VERSION ""

NS_ :

BS_:

BU_: AHLM ASBS CBC DIAGNOST DPDM DTCM ECM EHPS ESC ESL ESM ETM GPF HCP IC IRCM OCM ORC PTS RF_HUB SCCM SGW TBM TCM TPM

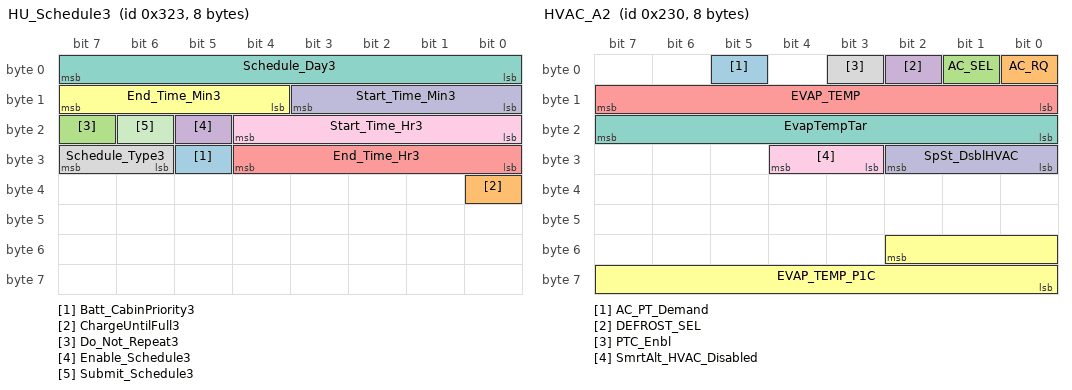
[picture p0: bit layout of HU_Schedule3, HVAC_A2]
BO_ 803 HU_Schedule3: 8 CBC
 SG_ Batt_CabinPriority3 : 29|1@1+ (1,0) [0|0] ""  HCP,SGW
 SG_ ChargeUntilFull3 : 32|1@1+ (1,0) [0|0] ""  HCP,SGW
 SG_ Do_Not_Repeat3 : 23|1@1+ (1,0) [0|0] ""  HCP,SGW
 SG_ Enable_Schedule3 : 21|1@1+ (1,0) [0|0] ""  HCP,SGW
 SG_ End_Time_Hr3 : 24|5@1+ (1,0) [0|23] "Hours"  HCP,SGW
 SG_ End_Time_Min3 : 12|4@1+ (5,0) [0|55] "min"  HCP,SGW
 SG_ Schedule_Day3 : 0|8@1+ (1,0) [0|0] ""  HCP,SGW
 SG_ Schedule_Type3 : 30|2@1+ (1,0) [0|0] ""  HCP,SGW
 SG_ Start_Time_Hr3 : 16|5@1+ (1,0) [0|23] "Hours"  HCP,SGW
 SG_ Start_Time_Min3 : 8|4@1+ (5,0) [0|55] "min"  HCP,SGW
 SG_ Submit_Schedule3 : 22|1@1+ (1,0) [0|0] ""  HCP,SGW

BO_ 560 HVAC_A2: 8 CBC
 SG_ AC_PT_Demand : 5|1@1+ (1,0) [0|0] ""  ECM,SGW
 SG_ AC_RQ : 0|1@1+ (1,0) [0|0] ""  ECM,HCP,SGW
 SG_ AC_SEL : 1|1@1+ (1,0) [0|0] ""  ECM,SGW
 SG_ DEFROST_SEL : 2|1@1+ (1,0) [0|0] ""  ECM,HCP,SGW
 SG_ EVAP_TEMP : 8|8@1+ (0.5,-20) [-20|107] "°C"  ECM,SGW
 SG_ EVAP_TEMP_P1C : 50|11@0+ (0.1,-40) [-40|85] "°C"  HCP,SGW
 SG_ EvapTempTar : 16|8@1+ (0.5,-20) [-20|107] "°C"  ECM,HCP,SGW
 SG_ PTC_Enbl : 3|1@1+ (1,0) [0|0] ""  ECM,SGW
 SG_ SmrtAlt_HVAC_Disabled : 27|2@1+ (1,0) [0|0] ""  SGW
 SG_ SpSt_DsblHVAC : 24|3@1+ (1,0) [0|0] ""  ECM,SGW

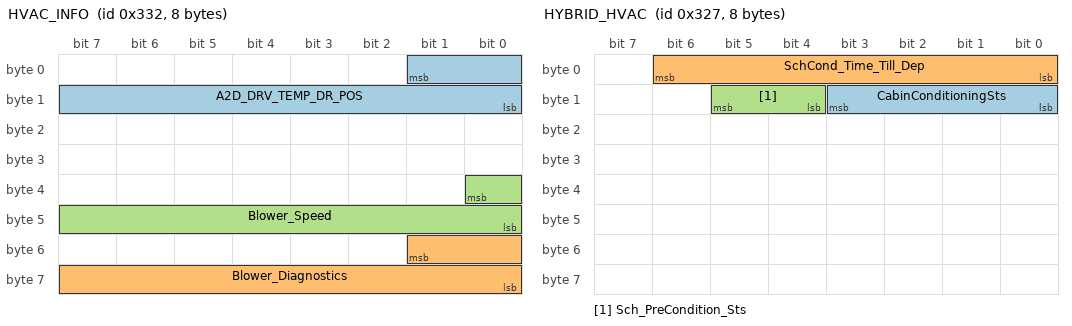
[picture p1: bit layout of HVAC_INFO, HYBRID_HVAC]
BO_ 818 HVAC_INFO: 8 CBC
 SG_ A2D_DRV_TEMP_DR_POS : 1|10@0+ (0.00489237,0) [0|5] "V"  ECM,SGW
 SG_ Blower_Diagnostics : 49|10@0+ (0.1,0) [0|100] "%"  ECM,HCP,SGW
 SG_ Blower_Speed : 32|9@0+ (1,0) [0|350] "Hz"  ECM,SGW

BO_ 807 HYBRID_HVAC: 8 HCP
 SG_ CabinConditioningSts : 8|4@1+ (1,0) [0|0] ""  CBC,ETM,SGW,TBM
 SG_ SchCond_Time_Till_Dep : 0|7@1+ (1,0) [0|126] ""  CBC,SGW,TBM
 SG_ Sch_PreCondition_Sts : 12|2@1+ (1,0) [0|0] ""  CBC,SGW,TBM

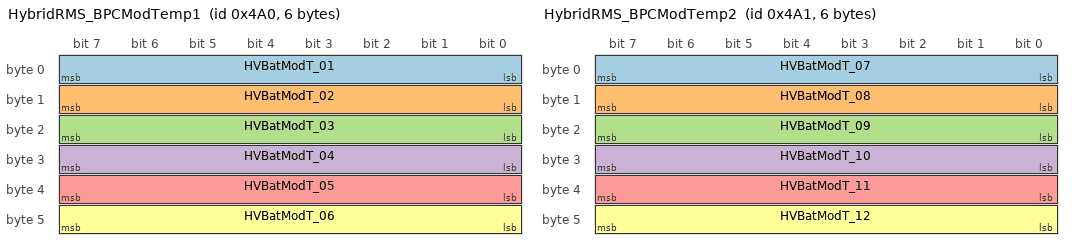
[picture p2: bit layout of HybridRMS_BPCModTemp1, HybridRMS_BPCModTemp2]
BO_ 1184 HybridRMS_BPCModTemp1: 6 HCP
 SG_ HVBatModT_01 : 0|8@1+ (1,-40) [-40|214] "oC"  SGW,TBM
 SG_ HVBatModT_02 : 8|8@1+ (1,-40) [-40|214] "oC"  SGW,TBM
 SG_ HVBatModT_03 : 16|8@1+ (1,-40) [-40|214] "oC"  SGW,TBM
 SG_ HVBatModT_04 : 24|8@1+ (1,-40) [-40|214] "oC"  SGW,TBM
 SG_ HVBatModT_05 : 32|8@1+ (1,-40) [-40|214] "oC"  SGW,TBM
 SG_ HVBatModT_06 : 40|8@1+ (1,-40) [-40|214] "oC"  SGW,TBM

BO_ 1185 HybridRMS_BPCModTemp2: 6 HCP
 SG_ HVBatModT_07 : 0|8@1+ (1,-40) [-40|214] "oC"  SGW,TBM
 SG_ HVBatModT_08 : 8|8@1+ (1,-40) [-40|214] "oC"  SGW,TBM
 SG_ HVBatModT_09 : 16|8@1+ (1,-40) [-40|214] "oC"  SGW,TBM
 SG_ HVBatModT_10 : 24|8@1+ (1,-40) [-40|214] "oC"  SGW,TBM
 SG_ HVBatModT_11 : 32|8@1+ (1,-40) [-40|214] "oC"  SGW,TBM
 SG_ HVBatModT_12 : 40|8@1+ (1,-40) [-40|214] "oC"  SGW,TBM

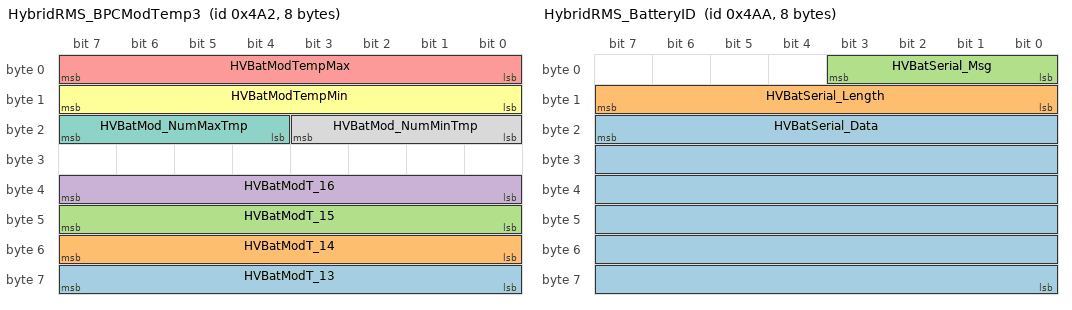
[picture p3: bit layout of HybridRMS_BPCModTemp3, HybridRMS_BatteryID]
BO_ 1186 HybridRMS_BPCModTemp3: 8 HCP
 SG_ HVBatModT_13 : 56|8@1+ (1,-40) [-40|214] "oC"  SGW,TBM
 SG_ HVBatModT_14 : 48|8@1+ (1,-40) [-40|214] "oC"  SGW,TBM
 SG_ HVBatModT_15 : 40|8@1+ (1,-40) [-40|214] "oC"  SGW,TBM
 SG_ HVBatModT_16 : 32|8@1+ (1,-40) [-40|214] "oC"  SGW,TBM
 SG_ HVBatModTempMax : 0|8@1+ (1,-40) [-40|214] "oC"  SGW,TBM
 SG_ HVBatModTempMin : 8|8@1+ (1,-40) [-40|214] "oC"  SGW,TBM
 SG_ HVBatMod_NumMaxTmp : 20|4@1+ (1,0) [0|15] ""  SGW,TBM
 SG_ HVBatMod_NumMinTmp : 16|4@1+ (1,0) [0|15] ""  SGW,TBM

BO_ 1194 HybridRMS_BatteryID: 8 HCP
 SG_ HVBatSerial_Data : 23|48@0+ (1,0) [0|281474976710000] "ASCII"  SGW,TBM
 SG_ HVBatSerial_Length : 8|8@1+ (1,0) [0|254] ""  SGW,TBM
 SG_ HVBatSerial_Msg : 0|4@1+ (1,0) [0|0] ""  SGW,TBM

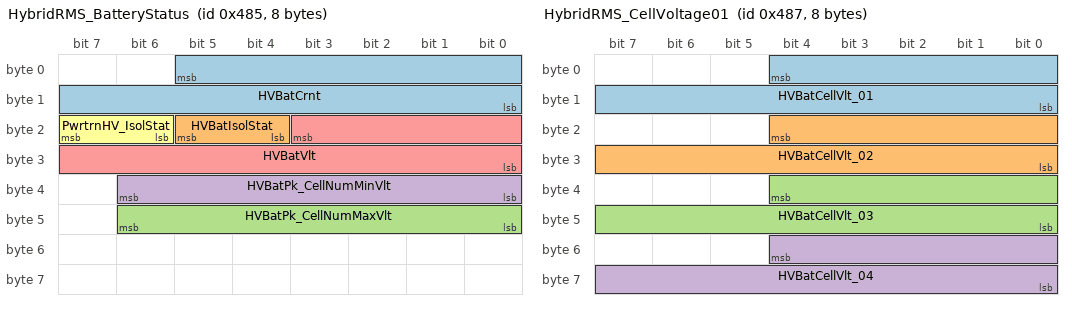
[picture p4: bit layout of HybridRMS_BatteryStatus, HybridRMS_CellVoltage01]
BO_ 1157 HybridRMS_BatteryStatus: 8 HCP
 SG_ HVBatCrnt : 5|14@0+ (0.1,-512.1) [-512|512] "Amp"  SGW,TBM
 SG_ HVBatIsolStat : 20|2@1+ (1,0) [0|0] ""  SGW,TBM
 SG_ HVBatPk_CellNumMaxVlt : 40|7@1+ (1,0) [1|96] "Volts"  SGW,TBM
 SG_ HVBatPk_CellNumMinVlt : 32|7@1+ (1,0) [1|96] "Volts"  SGW,TBM
 SG_ HVBatVlt : 19|12@0+ (0.1,180) [180|511] "Volts"  SGW,TBM
 SG_ PwrtrnHV_IsolStat : 22|2@1+ (1,0) [0|0] ""  SGW,TBM

BO_ 1159 HybridRMS_CellVoltage01: 8 HCP
 SG_ HVBatCellVlt_01 : 4|13@0+ (0.001,0) [0|5] "V"  SGW,TBM
 SG_ HVBatCellVlt_02 : 20|13@0+ (0.001,0) [0|5] "V"  SGW,TBM
 SG_ HVBatCellVlt_03 : 36|13@0+ (0.001,0) [0|5] "V"  SGW,TBM
 SG_ HVBatCellVlt_04 : 52|13@0+ (0.001,0) [0|5] "V"  SGW,TBM

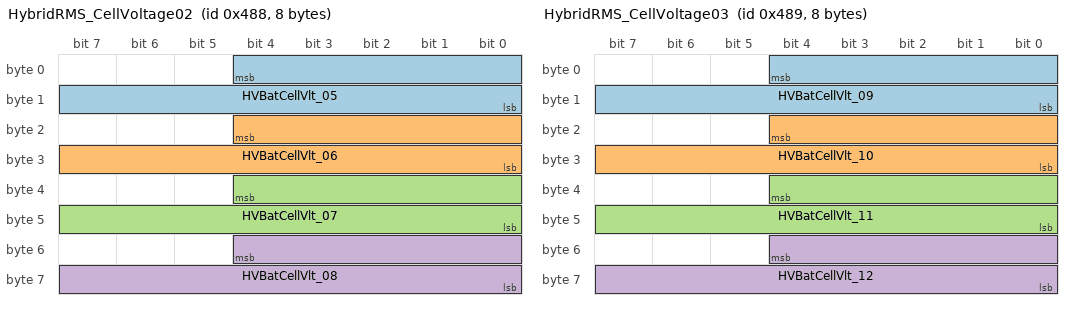
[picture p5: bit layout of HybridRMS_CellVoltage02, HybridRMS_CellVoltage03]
BO_ 1160 HybridRMS_CellVoltage02: 8 HCP
 SG_ HVBatCellVlt_05 : 4|13@0+ (0.001,0) [0|5] "V"  SGW,TBM
 SG_ HVBatCellVlt_06 : 20|13@0+ (0.001,0) [0|5] "V"  SGW,TBM
 SG_ HVBatCellVlt_07 : 36|13@0+ (0.001,0) [0|5] "V"  SGW,TBM
 SG_ HVBatCellVlt_08 : 52|13@0+ (0.001,0) [0|5] "V"  SGW,TBM

BO_ 1161 HybridRMS_CellVoltage03: 8 HCP
 SG_ HVBatCellVlt_09 : 4|13@0+ (0.001,0) [0|5] "V"  SGW,TBM
 SG_ HVBatCellVlt_10 : 20|13@0+ (0.001,0) [0|5] "V"  SGW,TBM
 SG_ HVBatCellVlt_11 : 36|13@0+ (0.001,0) [0|5] "V"  SGW,TBM
 SG_ HVBatCellVlt_12 : 52|13@0+ (0.001,0) [0|5] "V"  SGW,TBM

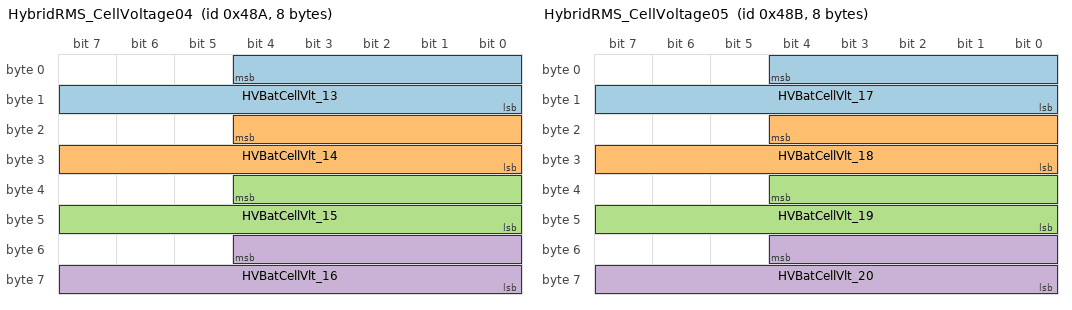
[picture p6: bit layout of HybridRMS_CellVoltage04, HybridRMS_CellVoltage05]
BO_ 1162 HybridRMS_CellVoltage04: 8 HCP
 SG_ HVBatCellVlt_13 : 4|13@0+ (0.001,0) [0|5] "V"  SGW,TBM
 SG_ HVBatCellVlt_14 : 20|13@0+ (0.001,0) [0|5] "V"  SGW,TBM
 SG_ HVBatCellVlt_15 : 36|13@0+ (0.001,0) [0|5] "V"  SGW,TBM
 SG_ HVBatCellVlt_16 : 52|13@0+ (0.001,0) [0|5] "V"  SGW,TBM

BO_ 1163 HybridRMS_CellVoltage05: 8 HCP
 SG_ HVBatCellVlt_17 : 4|13@0+ (0.001,0) [0|5] "V"  SGW,TBM
 SG_ HVBatCellVlt_18 : 20|13@0+ (0.001,0) [0|5] "V"  SGW,TBM
 SG_ HVBatCellVlt_19 : 36|13@0+ (0.001,0) [0|5] "V"  SGW,TBM
 SG_ HVBatCellVlt_20 : 52|13@0+ (0.001,0) [0|5] "V"  SGW,TBM

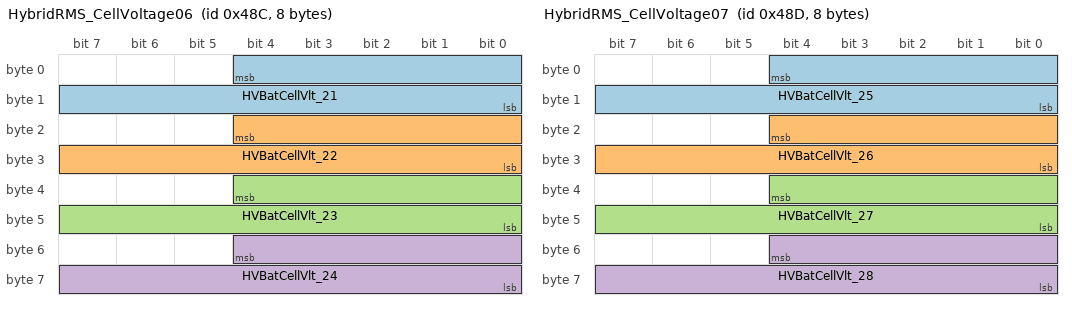
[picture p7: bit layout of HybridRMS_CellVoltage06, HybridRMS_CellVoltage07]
BO_ 1164 HybridRMS_CellVoltage06: 8 HCP
 SG_ HVBatCellVlt_21 : 4|13@0+ (0.001,0) [0|5] "V"  SGW,TBM
 SG_ HVBatCellVlt_22 : 20|13@0+ (0.001,0) [0|5] "V"  SGW,TBM
 SG_ HVBatCellVlt_23 : 36|13@0+ (0.001,0) [0|5] "V"  SGW,TBM
 SG_ HVBatCellVlt_24 : 52|13@0+ (0.001,0) [0|5] "V"  SGW,TBM

BO_ 1165 HybridRMS_CellVoltage07: 8 HCP
 SG_ HVBatCellVlt_25 : 4|13@0+ (0.001,0) [0|5] "V"  SGW,TBM
 SG_ HVBatCellVlt_26 : 20|13@0+ (0.001,0) [0|5] "V"  SGW,TBM
 SG_ HVBatCellVlt_27 : 36|13@0+ (0.001,0) [0|5] "V"  SGW,TBM
 SG_ HVBatCellVlt_28 : 52|13@0+ (0.001,0) [0|5] "V"  SGW,TBM

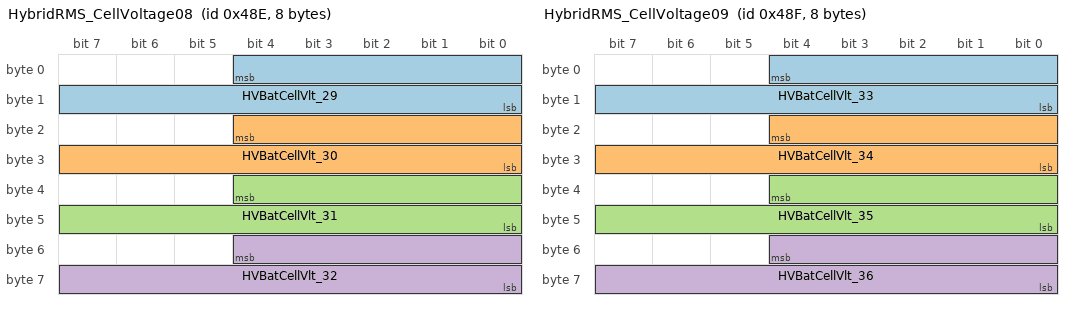
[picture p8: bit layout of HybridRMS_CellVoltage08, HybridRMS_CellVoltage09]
BO_ 1166 HybridRMS_CellVoltage08: 8 HCP
 SG_ HVBatCellVlt_29 : 4|13@0+ (0.001,0) [0|5] "V"  SGW,TBM
 SG_ HVBatCellVlt_30 : 20|13@0+ (0.001,0) [0|5] "V"  SGW,TBM
 SG_ HVBatCellVlt_31 : 36|13@0+ (0.001,0) [0|5] "V"  SGW,TBM
 SG_ HVBatCellVlt_32 : 52|13@0+ (0.001,0) [0|5] "V"  SGW,TBM

BO_ 1167 HybridRMS_CellVoltage09: 8 HCP
 SG_ HVBatCellVlt_33 : 4|13@0+ (0.001,0) [0|5] "V"  SGW,TBM
 SG_ HVBatCellVlt_34 : 20|13@0+ (0.001,0) [0|5] "V"  SGW,TBM
 SG_ HVBatCellVlt_35 : 36|13@0+ (0.001,0) [0|5] "V"  SGW,TBM
 SG_ HVBatCellVlt_36 : 52|13@0+ (0.001,0) [0|5] "V"  SGW,TBM

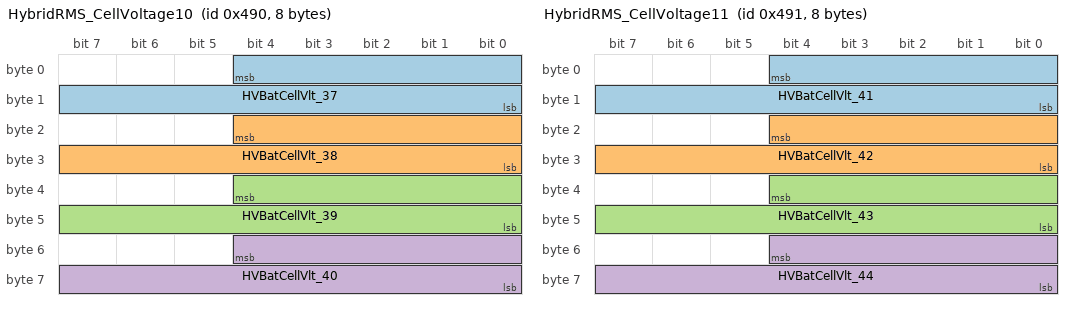
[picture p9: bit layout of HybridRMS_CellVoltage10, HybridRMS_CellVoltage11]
BO_ 1168 HybridRMS_CellVoltage10: 8 HCP
 SG_ HVBatCellVlt_37 : 4|13@0+ (0.001,0) [0|5] "V"  SGW,TBM
 SG_ HVBatCellVlt_38 : 20|13@0+ (0.001,0) [0|5] "V"  SGW,TBM
 SG_ HVBatCellVlt_39 : 36|13@0+ (0.001,0) [0|5] "V"  SGW,TBM
 SG_ HVBatCellVlt_40 : 52|13@0+ (0.001,0) [0|5] "V"  SGW,TBM

BO_ 1169 HybridRMS_CellVoltage11: 8 HCP
 SG_ HVBatCellVlt_41 : 4|13@0+ (0.001,0) [0|5] "V"  SGW,TBM
 SG_ HVBatCellVlt_42 : 20|13@0+ (0.001,0) [0|5] "V"  SGW,TBM
 SG_ HVBatCellVlt_43 : 36|13@0+ (0.001,0) [0|5] "V"  SGW,TBM
 SG_ HVBatCellVlt_44 : 52|13@0+ (0.001,0) [0|5] "V"  SGW,TBM

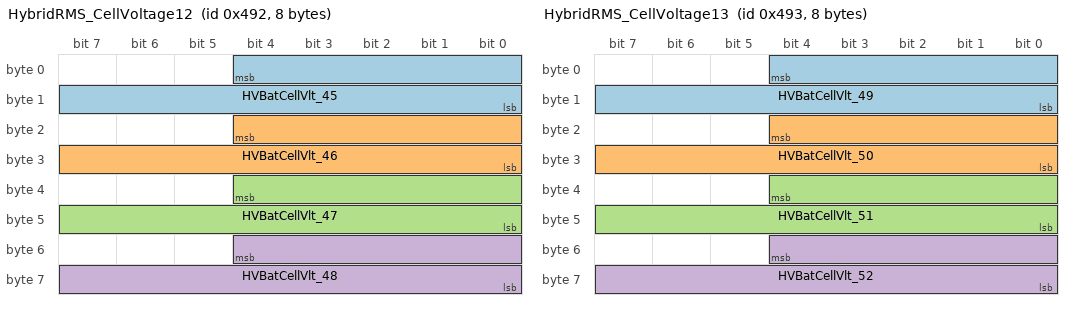
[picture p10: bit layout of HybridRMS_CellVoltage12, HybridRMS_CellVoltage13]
BO_ 1170 HybridRMS_CellVoltage12: 8 HCP
 SG_ HVBatCellVlt_45 : 4|13@0+ (0.001,0) [0|5] "V"  SGW,TBM
 SG_ HVBatCellVlt_46 : 20|13@0+ (0.001,0) [0|5] "V"  SGW,TBM
 SG_ HVBatCellVlt_47 : 36|13@0+ (0.001,0) [0|5] "V"  SGW,TBM
 SG_ HVBatCellVlt_48 : 52|13@0+ (0.001,0) [0|5] "V"  SGW,TBM

BO_ 1171 HybridRMS_CellVoltage13: 8 HCP
 SG_ HVBatCellVlt_49 : 4|13@0+ (0.001,0) [0|5] "V"  SGW,TBM
 SG_ HVBatCellVlt_50 : 20|13@0+ (0.001,0) [0|5] "V"  SGW,TBM
 SG_ HVBatCellVlt_51 : 36|13@0+ (0.001,0) [0|5] "V"  SGW,TBM
 SG_ HVBatCellVlt_52 : 52|13@0+ (0.001,0) [0|5] "V"  SGW,TBM

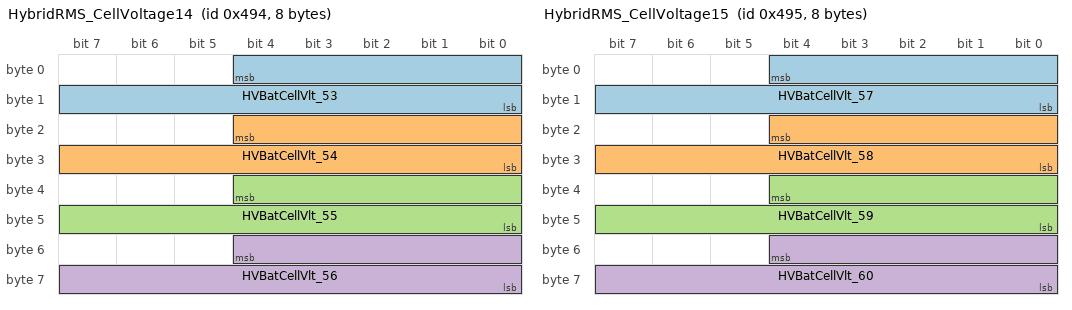
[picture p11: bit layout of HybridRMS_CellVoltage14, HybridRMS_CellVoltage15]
BO_ 1172 HybridRMS_CellVoltage14: 8 HCP
 SG_ HVBatCellVlt_53 : 4|13@0+ (0.001,0) [0|5] "V"  SGW,TBM
 SG_ HVBatCellVlt_54 : 20|13@0+ (0.001,0) [0|5] "V"  SGW,TBM
 SG_ HVBatCellVlt_55 : 36|13@0+ (0.001,0) [0|5] "V"  SGW,TBM
 SG_ HVBatCellVlt_56 : 52|13@0+ (0.001,0) [0|5] "V"  SGW,TBM

BO_ 1173 HybridRMS_CellVoltage15: 8 HCP
 SG_ HVBatCellVlt_57 : 4|13@0+ (0.001,0) [0|5] "V"  SGW,TBM
 SG_ HVBatCellVlt_58 : 20|13@0+ (0.001,0) [0|5] "V"  SGW,TBM
 SG_ HVBatCellVlt_59 : 36|13@0+ (0.001,0) [0|5] "V"  SGW,TBM
 SG_ HVBatCellVlt_60 : 52|13@0+ (0.001,0) [0|5] "V"  SGW,TBM

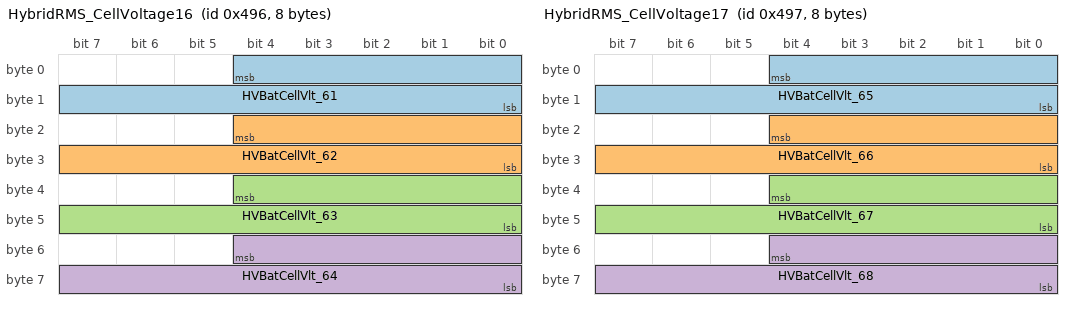
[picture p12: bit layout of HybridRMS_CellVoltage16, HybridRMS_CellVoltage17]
BO_ 1174 HybridRMS_CellVoltage16: 8 HCP
 SG_ HVBatCellVlt_61 : 4|13@0+ (0.001,0) [0|5] "V"  SGW,TBM
 SG_ HVBatCellVlt_62 : 20|13@0+ (0.001,0) [0|5] "V"  SGW,TBM
 SG_ HVBatCellVlt_63 : 36|13@0+ (0.001,0) [0|5] "V"  SGW,TBM
 SG_ HVBatCellVlt_64 : 52|13@0+ (0.001,0) [0|5] "V"  SGW,TBM

BO_ 1175 HybridRMS_CellVoltage17: 8 HCP
 SG_ HVBatCellVlt_65 : 4|13@0+ (0.001,0) [0|5] "V"  SGW,TBM
 SG_ HVBatCellVlt_66 : 20|13@0+ (0.001,0) [0|5] "V"  SGW,TBM
 SG_ HVBatCellVlt_67 : 36|13@0+ (0.001,0) [0|5] "V"  SGW,TBM
 SG_ HVBatCellVlt_68 : 52|13@0+ (0.001,0) [0|5] "V"  SGW,TBM

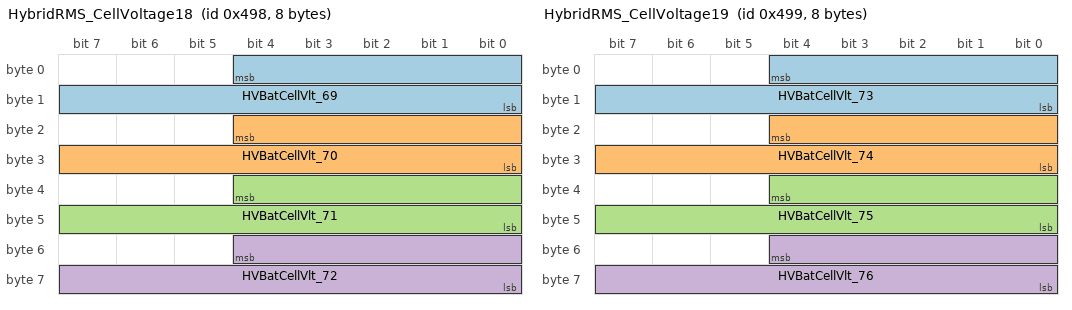
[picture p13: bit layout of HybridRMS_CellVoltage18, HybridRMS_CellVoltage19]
BO_ 1176 HybridRMS_CellVoltage18: 8 HCP
 SG_ HVBatCellVlt_69 : 4|13@0+ (0.001,0) [0|5] "V"  SGW,TBM
 SG_ HVBatCellVlt_70 : 20|13@0+ (0.001,0) [0|5] "V"  SGW,TBM
 SG_ HVBatCellVlt_71 : 36|13@0+ (0.001,0) [0|5] "V"  SGW,TBM
 SG_ HVBatCellVlt_72 : 52|13@0+ (0.001,0) [0|5] "V"  SGW,TBM

BO_ 1177 HybridRMS_CellVoltage19: 8 HCP
 SG_ HVBatCellVlt_73 : 4|13@0+ (0.001,0) [0|5] "V"  SGW,TBM
 SG_ HVBatCellVlt_74 : 20|13@0+ (0.001,0) [0|5] "V"  SGW,TBM
 SG_ HVBatCellVlt_75 : 36|13@0+ (0.001,0) [0|5] "V"  SGW,TBM
 SG_ HVBatCellVlt_76 : 52|13@0+ (0.001,0) [0|5] "V"  SGW,TBM

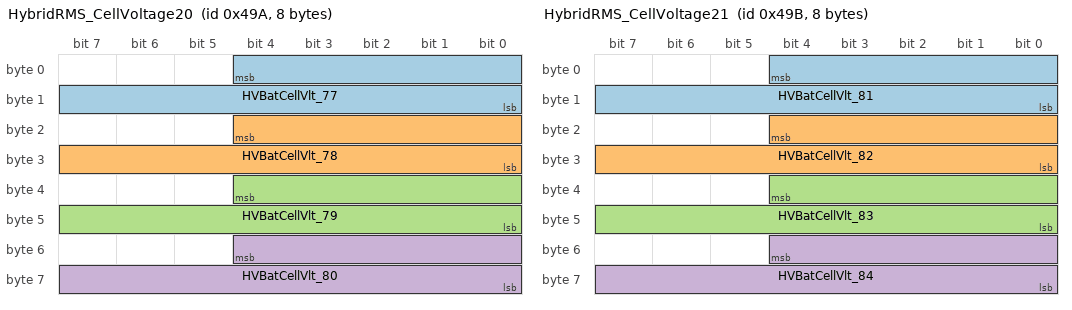
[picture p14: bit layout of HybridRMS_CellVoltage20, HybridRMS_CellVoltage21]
BO_ 1178 HybridRMS_CellVoltage20: 8 HCP
 SG_ HVBatCellVlt_77 : 4|13@0+ (0.001,0) [0|5] "V"  SGW,TBM
 SG_ HVBatCellVlt_78 : 20|13@0+ (0.001,0) [0|5] "V"  SGW,TBM
 SG_ HVBatCellVlt_79 : 36|13@0+ (0.001,0) [0|5] "V"  SGW,TBM
 SG_ HVBatCellVlt_80 : 52|13@0+ (0.001,0) [0|5] "V"  SGW,TBM

BO_ 1179 HybridRMS_CellVoltage21: 8 HCP
 SG_ HVBatCellVlt_81 : 4|13@0+ (0.001,0) [0|5] "V"  SGW,TBM
 SG_ HVBatCellVlt_82 : 20|13@0+ (0.001,0) [0|5] "V"  SGW,TBM
 SG_ HVBatCellVlt_83 : 36|13@0+ (0.001,0) [0|5] "V"  SGW,TBM
 SG_ HVBatCellVlt_84 : 52|13@0+ (0.001,0) [0|5] "V"  SGW,TBM

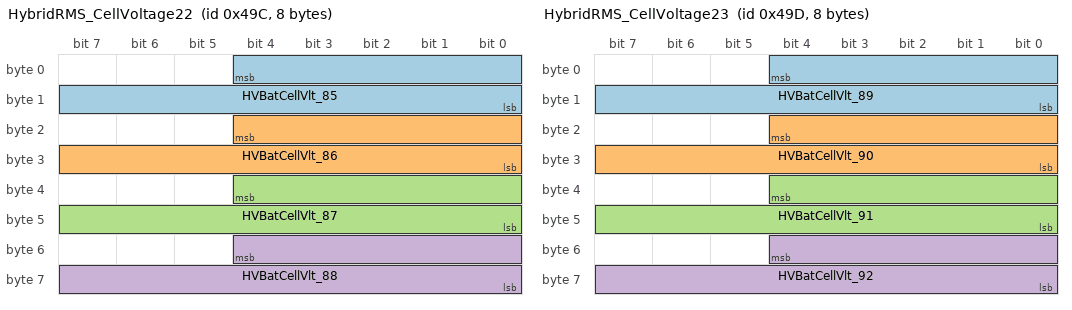
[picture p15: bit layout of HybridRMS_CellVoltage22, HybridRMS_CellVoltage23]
BO_ 1180 HybridRMS_CellVoltage22: 8 HCP
 SG_ HVBatCellVlt_85 : 4|13@0+ (0.001,0) [0|5] "V"  SGW,TBM
 SG_ HVBatCellVlt_86 : 20|13@0+ (0.001,0) [0|5] "V"  SGW,TBM
 SG_ HVBatCellVlt_87 : 36|13@0+ (0.001,0) [0|5] "V"  SGW,TBM
 SG_ HVBatCellVlt_88 : 52|13@0+ (0.001,0) [0|5] "V"  SGW,TBM

BO_ 1181 HybridRMS_CellVoltage23: 8 HCP
 SG_ HVBatCellVlt_89 : 4|13@0+ (0.001,0) [0|5] "V"  SGW,TBM
 SG_ HVBatCellVlt_90 : 20|13@0+ (0.001,0) [0|5] "V"  SGW,TBM
 SG_ HVBatCellVlt_91 : 36|13@0+ (0.001,0) [0|5] "V"  SGW,TBM
 SG_ HVBatCellVlt_92 : 52|13@0+ (0.001,0) [0|5] "V"  SGW,TBM

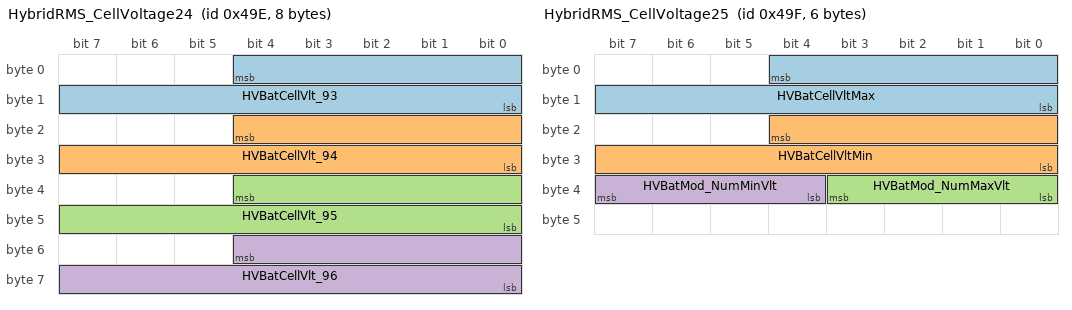
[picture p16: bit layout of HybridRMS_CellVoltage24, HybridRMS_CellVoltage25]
BO_ 1182 HybridRMS_CellVoltage24: 8 HCP
 SG_ HVBatCellVlt_93 : 4|13@0+ (0.001,0) [0|5] "V"  SGW,TBM
 SG_ HVBatCellVlt_94 : 20|13@0+ (0.001,0) [0|5] "V"  SGW,TBM
 SG_ HVBatCellVlt_95 : 36|13@0+ (0.001,0) [0|5] "V"  SGW,TBM
 SG_ HVBatCellVlt_96 : 52|13@0+ (0.001,0) [0|5] "V"  SGW,TBM

BO_ 1183 HybridRMS_CellVoltage25: 6 HCP
 SG_ HVBatCellVltMax : 4|13@0+ (0.001,0) [0|5] "Volts"  SGW,TBM
 SG_ HVBatCellVltMin : 20|13@0+ (0.001,0) [0|5] "Volts"  SGW,TBM
 SG_ HVBatMod_NumMaxVlt : 32|4@1+ (1,0) [0|15] ""  SGW,TBM
 SG_ HVBatMod_NumMinVlt : 36|4@1+ (1,0) [0|15] ""  SGW,TBM

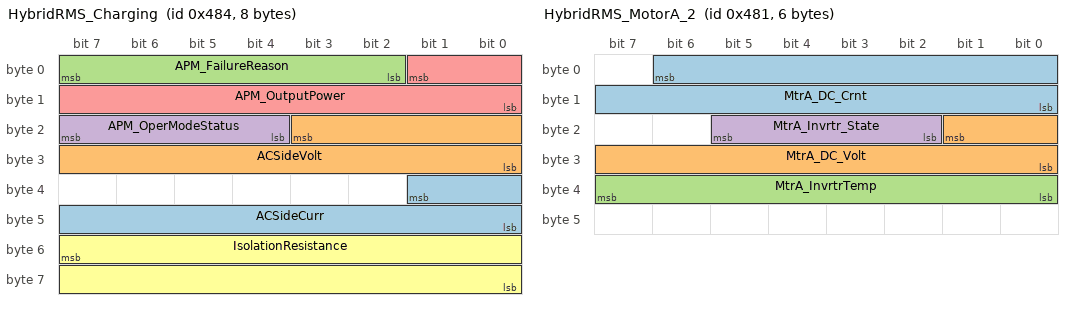
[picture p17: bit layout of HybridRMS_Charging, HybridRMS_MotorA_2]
BO_ 1156 HybridRMS_Charging: 8 HCP
 SG_ ACSideCurr : 33|10@0+ (0.1,-50) [-50|50] "Amp"  SGW,TBM
 SG_ ACSideVolt : 19|12@0+ (0.1,0) [0|300] "Volts"  SGW,TBM
 SG_ APM_FailureReason : 2|6@1+ (1,0) [0|0] ""  SGW,TBM
 SG_ APM_OperModeStatus : 20|4@1+ (1,0) [0|0] ""  SGW,TBM
 SG_ APM_OutputPower : 1|10@0+ (3,0) [0|3066] "W"  SGW,TBM
 SG_ IsolationResistance : 55|16@0+ (1,0) [0|65534] "kOhm"  SGW,TBM

BO_ 1152 HybridRMS_MotorA_1: 6 HCP
 SG_ MtrA_RPM : 7|16@0+ (1,-32768) [-32768|32767] "RPM"  SGW,TBM
 SG_ MtrA_Temp : 32|8@1+ (1,-40) [-40|215] "oC"  SGW,TBM
 SG_ MtrA_TorqAchieved : 20|13@0+ (0.125,-512) [-512|511.875] "Nm"  SGW,TBM

BO_ 1153 HybridRMS_MotorA_2: 6 HCP
 SG_ MtrA_DC_Crnt : 6|15@0+ (0.1,-1638.4) [-1638.4|1638.3] "A"  SGW,TBM
 SG_ MtrA_DC_Volt : 17|10@0+ (1,0) [0|1023] "V"  SGW,TBM
 SG_ MtrA_InvrtrTemp : 32|8@1+ (1,-40) [-40|215] "oC"  SGW,TBM
 SG_ MtrA_Invrtr_State : 18|4@1+ (1,0) [0|0] ""  SGW,TBM

BO_ 1154 HybridRMS_MotorB_1: 6 HCP
 SG_ MtrB_RPM : 7|16@0+ (1,-32768) [-32768|32767] "RPM"  SGW,TBM
 SG_ MtrB_Temp : 32|8@1+ (1,-40) [-40|215] "oC"  SGW,TBM
 SG_ MtrB_TorqAchieved : 20|13@0+ (0.125,-512) [-512|511.875] "Nm"  SGW,TBM

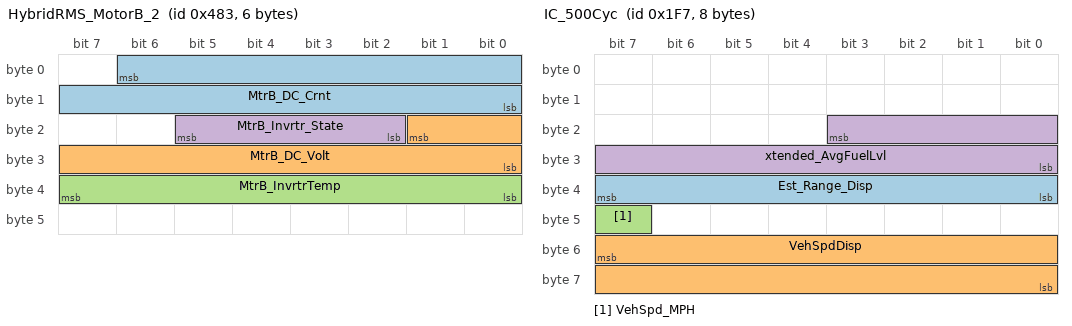
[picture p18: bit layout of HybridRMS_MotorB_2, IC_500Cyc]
BO_ 1155 HybridRMS_MotorB_2: 6 HCP
 SG_ MtrB_DC_Crnt : 6|15@0+ (0.1,-1638.4) [-1638.4|1638.3] "A"  SGW,TBM
 SG_ MtrB_DC_Volt : 17|10@0+ (1,0) [0|1023] "V"  SGW,TBM
 SG_ MtrB_InvrtrTemp : 32|8@1+ (1,-40) [-40|215] "oC"  SGW,TBM
 SG_ MtrB_Invrtr_State : 18|4@1+ (1,0) [0|0] ""  SGW,TBM

BO_ 1158 HybridRMS_Warnings: 8 HCP
 SG_ APMPerfWrn : 2|1@1+ (1,0) [0|0] ""  SGW,TBM
 SG_ APMTempWrn : 3|1@1+ (1,0) [0|0] ""  SGW,TBM
 SG_ BPCMCellBalWrn : 5|1@1+ (1,0) [0|0] ""  SGW,TBM
 SG_ BPCMCellOverWrn : 6|1@1+ (1,0) [0|0] ""  SGW,TBM
 SG_ BPCMCellUnderWrn : 7|1@1+ (1,0) [0|0] ""  SGW,TBM
 SG_ BPCMHighSOCWrn : 8|1@1+ (1,0) [0|0] ""  SGW,TBM
 SG_ BPCMInsulWrn : 9|1@1+ (1,0) [0|0] ""  SGW,TBM
 SG_ BPCMMaxTempWrn : 1|1@1+ (1,0) [0|0] ""  SGW,TBM
 SG_ BPCMOverChrgWrn : 10|1@1+ (1,0) [0|0] ""  SGW,TBM
 SG_ BPCMOverVoltWrn : 11|1@1+ (1,0) [0|0] ""  SGW,TBM
 SG_ BPCMSOCJumpWrn : 12|1@1+ (1,0) [0|0] ""  SGW,TBM
 SG_ BPCMSOCLowWrn : 13|1@1+ (1,0) [0|0] ""  SGW,TBM
 SG_ BPCMTempDiffWrn : 0|1@1+ (1,0) [0|0] ""  SGW,TBM
 SG_ BPCMUnderVoltWrn : 14|1@1+ (1,0) [0|0] ""  SGW,TBM
 SG_ BPCMUnmatchedWrn : 15|1@1+ (1,0) [0|0] ""  SGW,TBM
 SG_ HVILWrn : 4|1@1+ (1,0) [0|0] ""  SGW,TBM
 SG_ HighestWarnLevel : 16|2@1+ (1,0) [0|0] ""  SGW,TBM
 SG_ MtrA_InvOverTempWrn : 19|1@1+ (1,0) [0|0] ""  SGW,TBM
 SG_ MtrA_OverTempWrn : 18|1@1+ (1,0) [0|0] ""  SGW,TBM
 SG_ MtrB_InvOverTempWrn : 21|1@1+ (1,0) [0|0] ""  SGW,TBM
 SG_ MtrB_OverTempWrn : 20|1@1+ (1,0) [0|0] ""  SGW,TBM

BO_ 503 IC_500Cyc: 8 IC
 SG_ Est_Range_Disp : 32|8@1+ (1,0) [0|254] ""  CBC,ETM,SGW,TBM
 SG_ VehSpdDisp : 55|16@0+ (1,0) [0|65534] ""  CBC,SGW
 SG_ VehSpd_MPH : 47|1@1+ (1,0) [0|0] ""  CBC,SGW
 SG_ xtended_AvgFuelLvl : 19|12@0+ (0.5,0) [0|2047] "liters"  CBC,ECM,SGW

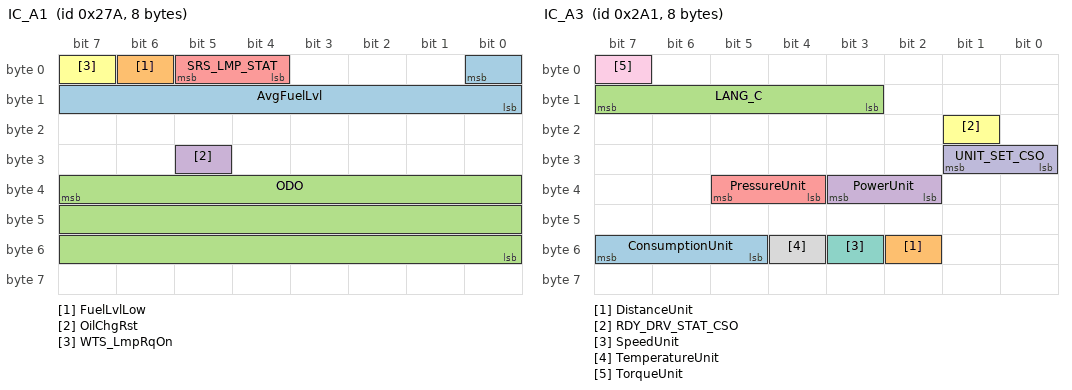
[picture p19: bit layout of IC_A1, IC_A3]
BO_ 634 IC_A1: 8 IC
 SG_ AvgFuelLvl : 0|9@0+ (0.5,0) [0|255] "liters"  CBC,ECM,ETM,SGW,TBM
 SG_ FuelLvlLow : 6|1@1+ (1,0) [0|0] ""  CBC,ECM,ETM,SGW,TBM
 SG_ ODO : 39|24@0+ (0.1,0) [0|1677721.4] "km"  AHLM,ASBS,CBC,DPDM,DTCM,ECM,EHPS,ESC,ESL,ESM,ETM,GPF,HCP,IRCM,OCM,ORC,PTS,RF_HUB,SCCM,SGW,TBM,TCM,TPM
 SG_ OilChgRst : 29|1@1+ (1,0) [0|0] ""  ECM,SGW
 SG_ SRS_LMP_STAT : 4|2@1+ (1,0) [0|0] ""  ETM,ORC,SGW,TBM
 SG_ WTS_LmpRqOn : 7|1@1+ (1,0) [0|0] ""  ECM,SGW

BO_ 673 IC_A3: 8 IC
 SG_ ConsumptionUnit : 53|3@1+ (1,0) [0|0] ""  CBC,SGW
 SG_ DistanceUnit : 50|1@1+ (1,0) [0|0] ""  CBC,ECM,SGW
 SG_ LANG_C : 11|5@1+ (1,0) [0|0] ""  CBC,SGW,TBM
 SG_ PowerUnit : 34|2@1+ (1,0) [0|0] ""  CBC,SGW
 SG_ PressureUnit : 36|2@1+ (1,0) [0|0] ""  CBC,SGW
 SG_ RDY_DRV_STAT_CSO : 17|1@1+ (1,0) [0|0] ""  CBC,SGW
 SG_ SpeedUnit : 51|1@1+ (1,0) [0|0] ""  ASBS,CBC,ECM,IRCM,SGW
 SG_ TemperatureUnit : 52|1@1+ (1,0) [0|0] ""  CBC,SGW
 SG_ TorqueUnit : 7|1@1+ (1,0) [0|0] ""  CBC,SGW
 SG_ UNIT_SET_CSO : 24|2@1+ (1,0) [0|0] ""  CBC,SGW

BO_ 635 IC_A5: 8 IC
 SG_ Gas_Range : 1|10@0+ (1,0) [0|1022] "km"  CBC,ETM,SGW,TBM
 SG_ Total_Range : 18|11@0+ (1,0) [0|2046] "km"  CBC,ETM,SGW,TBM

BO_ 754 IC_A6: 8 IC
 SG_ Avg_Fuel_Econ : 33|10@0+ (0.05,0) [0|50] "kmpl"  CBC,ETM,SGW,TBM
 SG_ Inst_Fuel_Econ : 49|10@0+ (0.05,0) [0|50] "kmpl"  CBC,SGW

BO_ 938 IC_TripData_1: 8 IC
 SG_ A_EV_Kilometers : 47|24@0+ (0.1,0) [0|16093.3] "km"  ETM,SGW,TBM
 SG_ A_EV_Miles : 23|24@0+ (0.1,0) [0|9999.9] "Mile"  ETM,SGW,TBM
 SG_ A_MPG : 1|10@0+ (0.1,0) [0|99.9] "MPG"  ETM,SGW,TBM

BO_ 939 IC_TripData_2: 8 IC
 SG_ A_Hybrid_Kilometers : 47|24@0+ (0.1,0) [0|16093.3] "km"  ETM,SGW,TBM
 SG_ A_Hybrid_Miles : 23|24@0+ (0.1,0) [0|9999.9] "Mile"  ETM,SGW,TBM
 SG_ A_KMpL : 1|10@0+ (0.1,0) [0|99.9] "kmpl"  ETM,SGW,TBM

BO_ 940 IC_TripData_3: 8 IC
 SG_ A_Total_Dist_Kilometers : 47|24@0+ (0.1,0) [0|16093.3] "km"  ETM,SGW,TBM
 SG_ A_Total_Dist_Miles : 23|24@0+ (0.1,0) [0|9999.9] "Mile"  ETM,SGW,TBM

BO_ 941 IC_TripData_4: 8 IC
 SG_ B_EV_Kilometers : 47|24@0+ (0.1,0) [0|16093.3] "km"  ETM,SGW,TBM
 SG_ B_EV_Miles : 23|24@0+ (0.1,0) [0|9999.9] "Mile"  ETM,SGW,TBM
 SG_ B_MPG : 1|10@0+ (0.1,0) [0|99.9] "MPG"  ETM,SGW,TBM

BO_ 942 IC_TripData_5: 8 IC
 SG_ B_Hybrid_Kilometers : 47|24@0+ (0.1,0) [0|16093.3] "km"  ETM,SGW,TBM
 SG_ B_Hybrid_Miles : 23|24@0+ (0.1,0) [0|9999.9] "Mile"  ETM,SGW,TBM
 SG_ B_KMpL : 1|10@0+ (0.1,0) [0|99.9] "kmpl"  ETM,SGW,TBM

CM_ SG_ 803 Batt_CabinPriority3 "Bit to prioritize battery charging or cabin conditioning under schedule 3";
CM_ SG_ 803 ChargeUntilFull3 "Charge until battery is fully charged with schedule 3";
CM_ SG_ 803 Do_Not_Repeat3 "Do not repeat the set Schedule";
CM_ SG_ 803 Enable_Schedule3 "Schedule 3 checkbox enabled";
CM_ SG_ 803 End_Time_Hr3 "End Time of schedule 3 (hours in 24 hrs. format)";
CM_ SG_ 803 End_Time_Min3 "End Time of schedule 3 (Minutes)";
CM_ SG_ 803 Schedule_Day3 "Schedule#3 Day for charging or cabin conditioning";
CM_ SG_ 803 Schedule_Type3 "Type of charging and climate schedule";
CM_ SG_ 803 Start_Time_Hr3 "Start Time of schedule 3 (hours in 24 hrs. format)";
CM_ SG_ 803 Start_Time_Min3 "Start Time of schedule 3 (minutes)";
CM_ SG_ 803 Submit_Schedule3 "Schedule 3 submitted";
CM_ SG_ 560 AC_PT_Demand "Maximum A/C demand to powertrain";
CM_ SG_ 560 AC_RQ "A/C clutch request; [1] = A/C Clutch requested; 0 = A/C Clutch not requested";
CM_ SG_ 560 AC_SEL "Customer has selected A/C; [1] = A/C selected; 0 = A/C not selected";
CM_ SG_ 560 DEFROST_SEL "Defrost select switch";
CM_ SG_ 560 EVAP_TEMP "AC evaporator temperature";
CM_ SG_ 560 EVAP_TEMP_P1C "AC evap temp point one C";
CM_ SG_ 560 EvapTempTar "Evaporator temperature target";
CM_ SG_ 560 PTC_Enbl "PTC heater enable; [1] = enable";
CM_ SG_ 560 SmrtAlt_HVAC_Disabled "Disable the smart alternator";
CM_ SG_ 560 SpSt_DsblHVAC "Stop start disable from HVAC";
CM_ SG_ 818 A2D_DRV_TEMP_DR_POS "Transmit raw A/D driver temp door position to ECM to make OBD model more robust";
CM_ SG_ 818 Blower_Diagnostics "Duty cycle Feedback received from the Blower";
CM_ SG_ 818 Blower_Speed "Frequency Feedback received from the Blower";
CM_ SG_ 807 CabinConditioningSts "Cabin condition status";
CM_ SG_ 807 SchCond_Time_Till_Dep "Schedule Cabin Conditonting - Time till Departure for HVAC";
CM_ SG_ 807 Sch_PreCondition_Sts "HCP Status for Scheduled Pre Conditioning Request";
CM_ SG_ 1184 HVBatModT_01 "High voltage battery module temperature";
CM_ SG_ 1184 HVBatModT_02 "High voltage battery module temperature";
CM_ SG_ 1184 HVBatModT_03 "High voltage battery module temperature";
CM_ SG_ 1184 HVBatModT_04 "High voltage battery module temperature";
CM_ SG_ 1184 HVBatModT_05 "High voltage battery module temperature";
CM_ SG_ 1184 HVBatModT_06 "High voltage battery module temperature";
CM_ SG_ 1185 HVBatModT_07 "High voltage battery module temperature";
CM_ SG_ 1185 HVBatModT_08 "High voltage battery module temperature";
CM_ SG_ 1185 HVBatModT_09 "High voltage battery module temperature";
CM_ SG_ 1185 HVBatModT_10 "High voltage battery module temperature";
CM_ SG_ 1185 HVBatModT_11 "High voltage battery module temperature";
CM_ SG_ 1185 HVBatModT_12 "High voltage battery module temperature";
CM_ SG_ 1186 HVBatModT_13 "High voltage battery module temperature";
CM_ SG_ 1186 HVBatModT_14 "High voltage battery module temperature";
CM_ SG_ 1186 HVBatModT_15 "High voltage battery module temperature";
CM_ SG_ 1186 HVBatModT_16 "High voltage battery module temperature";
CM_ SG_ 1186 HVBatModTempMax "HV Battery pack Maximum temperature";
CM_ SG_ 1186 HVBatModTempMin "HV Battery pack Minimum temperature";
CM_ SG_ 1186 HVBatMod_NumMaxTmp "Module number - maximum temperature";
CM_ SG_ 1186 HVBatMod_NumMinTmp "Module number - minimum temperature";
CM_ SG_ 1194 HVBatSerial_Data "6 character segment of HV Battery pack serial number (using 8-bit ASCII encoding)";
CM_ SG_ 1194 HVBatSerial_Length "Length of the High Voltage Battery pack's serial number (number of ASCII characters)";
CM_ SG_ 1194 HVBatSerial_Msg "Identifies which 6 character segment of the HV Battery pack serial number is currently in HVBatSerial_Data";
CM_ SG_ 1157 HVBatCrnt "High voltage Battery pack current...";
CM_ SG_ 1157 HVBatIsolStat "High voltage battery pack Isolation state";
CM_ SG_ 1157 HVBatPk_CellNumMaxVlt "Cell ID of high voltage battery pack cell with the highest voltage.";
CM_ SG_ 1157 HVBatPk_CellNumMinVlt "Cell ID of high voltage battery pack cell with the lowest voltage.";
CM_ SG_ 1157 HVBatVlt "High voltage battery pack voltage";
CM_ SG_ 1157 PwrtrnHV_IsolStat "Powertrain High voltage Isolation state";
CM_ SG_ 1159 HVBatCellVlt_01 "High voltage battery cell voltage for Cell 01";
CM_ SG_ 1159 HVBatCellVlt_02 "High voltage battery cell voltage for Cell 02";
CM_ SG_ 1159 HVBatCellVlt_03 "High voltage battery cell voltage for Cell 03";
CM_ SG_ 1159 HVBatCellVlt_04 "High voltage battery cell voltage for Cell 04";
CM_ SG_ 1160 HVBatCellVlt_05 "High voltage battery cell voltage for Cell 05";
CM_ SG_ 1160 HVBatCellVlt_06 "High voltage battery cell voltage for Cell 06";
CM_ SG_ 1160 HVBatCellVlt_07 "High voltage battery cell voltage for Cell 07";
CM_ SG_ 1160 HVBatCellVlt_08 "High voltage battery cell voltage for Cell 08";
CM_ SG_ 1161 HVBatCellVlt_09 "High voltage battery cell voltage for Cell 09";
CM_ SG_ 1161 HVBatCellVlt_10 "High voltage battery cell voltage for Cell 10";
CM_ SG_ 1161 HVBatCellVlt_11 "High voltage battery cell voltage for Cell 11";
CM_ SG_ 1161 HVBatCellVlt_12 "High voltage battery cell voltage for Cell 12";
CM_ SG_ 1162 HVBatCellVlt_13 "High voltage battery cell voltage for Cell 13";
CM_ SG_ 1162 HVBatCellVlt_14 "High voltage battery cell voltage for Cell 14";
CM_ SG_ 1162 HVBatCellVlt_15 "High voltage battery cell voltage for Cell 15";
CM_ SG_ 1162 HVBatCellVlt_16 "High voltage battery cell voltage for Cell 16";
CM_ SG_ 1163 HVBatCellVlt_17 "High voltage battery cell voltage for Cell 17";
CM_ SG_ 1163 HVBatCellVlt_18 "High voltage battery cell voltage for Cell 18";
CM_ SG_ 1163 HVBatCellVlt_19 "High voltage battery cell voltage for Cell 19";
CM_ SG_ 1163 HVBatCellVlt_20 "High voltage battery cell voltage for Cell 20";
CM_ SG_ 1164 HVBatCellVlt_21 "High voltage battery cell voltage for Cell 21";
CM_ SG_ 1164 HVBatCellVlt_22 "High voltage battery cell voltage for Cell 22";
CM_ SG_ 1164 HVBatCellVlt_23 "High voltage battery cell voltage for Cell 23";
CM_ SG_ 1164 HVBatCellVlt_24 "High voltage battery cell voltage for Cell 24";
CM_ SG_ 1165 HVBatCellVlt_25 "High voltage battery cell voltage for Cell 25";
CM_ SG_ 1165 HVBatCellVlt_26 "High voltage battery cell voltage for Cell 26";
CM_ SG_ 1165 HVBatCellVlt_27 "High voltage battery cell voltage for Cell 27";
CM_ SG_ 1165 HVBatCellVlt_28 "High voltage battery cell voltage for Cell 28";
CM_ SG_ 1166 HVBatCellVlt_29 "High voltage battery cell voltage for Cell 29";
CM_ SG_ 1166 HVBatCellVlt_30 "High voltage battery cell voltage for Cell 30";
CM_ SG_ 1166 HVBatCellVlt_31 "High voltage battery cell voltage for Cell 31";
CM_ SG_ 1166 HVBatCellVlt_32 "High voltage battery cell voltage for Cell 32";
CM_ SG_ 1167 HVBatCellVlt_33 "High voltage battery cell voltage for Cell 33";
CM_ SG_ 1167 HVBatCellVlt_34 "High voltage battery cell voltage for Cell 34";
CM_ SG_ 1167 HVBatCellVlt_35 "High voltage battery cell voltage for Cell 35";
CM_ SG_ 1167 HVBatCellVlt_36 "High voltage battery cell voltage for Cell 36";
CM_ SG_ 1168 HVBatCellVlt_37 "High voltage battery cell voltage for Cell 37";
CM_ SG_ 1168 HVBatCellVlt_38 "High voltage battery cell voltage for Cell 38";
CM_ SG_ 1168 HVBatCellVlt_39 "High voltage battery cell voltage for Cell 39";
CM_ SG_ 1168 HVBatCellVlt_40 "High voltage battery cell voltage for Cell 40";
CM_ SG_ 1169 HVBatCellVlt_41 "High voltage battery cell voltage for Cell 41";
CM_ SG_ 1169 HVBatCellVlt_42 "High voltage battery cell voltage for Cell 42";
CM_ SG_ 1169 HVBatCellVlt_43 "High voltage battery cell voltage for Cell 43";
CM_ SG_ 1169 HVBatCellVlt_44 "High voltage battery cell voltage for Cell 44";
CM_ SG_ 1170 HVBatCellVlt_45 "High voltage battery cell voltage for Cell 45";
CM_ SG_ 1170 HVBatCellVlt_46 "High voltage battery cell voltage for Cell 46";
CM_ SG_ 1170 HVBatCellVlt_47 "High voltage battery cell voltage for Cell 47";
CM_ SG_ 1170 HVBatCellVlt_48 "High voltage battery cell voltage for Cell 48";
CM_ SG_ 1171 HVBatCellVlt_49 "High voltage battery cell voltage for Cell 49";
CM_ SG_ 1171 HVBatCellVlt_50 "High voltage battery cell voltage for Cell 50";
CM_ SG_ 1171 HVBatCellVlt_51 "High voltage battery cell voltage for Cell 51";
CM_ SG_ 1171 HVBatCellVlt_52 "High voltage battery cell voltage for Cell 52";
CM_ SG_ 1172 HVBatCellVlt_53 "High voltage battery cell voltage for Cell 53";
CM_ SG_ 1172 HVBatCellVlt_54 "High voltage battery cell voltage for Cell 54";
CM_ SG_ 1172 HVBatCellVlt_55 "High voltage battery cell voltage for Cell 55";
CM_ SG_ 1172 HVBatCellVlt_56 "High voltage battery cell voltage for Cell 56";
CM_ SG_ 1173 HVBatCellVlt_57 "High voltage battery cell voltage for Cell 57";
CM_ SG_ 1173 HVBatCellVlt_58 "High voltage battery cell voltage for Cell 58";
CM_ SG_ 1173 HVBatCellVlt_59 "High voltage battery cell voltage for Cell 59";
CM_ SG_ 1173 HVBatCellVlt_60 "High voltage battery cell voltage for Cell 60";
CM_ SG_ 1174 HVBatCellVlt_61 "High voltage battery cell voltage for Cell 61";
CM_ SG_ 1174 HVBatCellVlt_62 "High voltage battery cell voltage for Cell 62";
CM_ SG_ 1174 HVBatCellVlt_63 "High voltage battery cell voltage for Cell 63";
CM_ SG_ 1174 HVBatCellVlt_64 "High voltage battery cell voltage for Cell 64";
CM_ SG_ 1175 HVBatCellVlt_65 "High voltage battery cell voltage for Cell 65";
CM_ SG_ 1175 HVBatCellVlt_66 "High voltage battery cell voltage for Cell 66";
CM_ SG_ 1175 HVBatCellVlt_67 "High voltage battery cell voltage for Cell 67";
CM_ SG_ 1175 HVBatCellVlt_68 "High voltage battery cell voltage for Cell 68";
CM_ SG_ 1176 HVBatCellVlt_69 "High voltage battery cell voltage for Cell 69";
CM_ SG_ 1176 HVBatCellVlt_70 "High voltage battery cell voltage for Cell 70";
CM_ SG_ 1176 HVBatCellVlt_71 "High voltage battery cell voltage for Cell 71";
CM_ SG_ 1176 HVBatCellVlt_72 "High voltage battery cell voltage for Cell 72";
CM_ SG_ 1177 HVBatCellVlt_73 "High voltage battery cell voltage for Cell 73";
CM_ SG_ 1177 HVBatCellVlt_74 "High voltage battery cell voltage for Cell 74";
CM_ SG_ 1177 HVBatCellVlt_75 "High voltage battery cell voltage for Cell 75";
CM_ SG_ 1177 HVBatCellVlt_76 "High voltage battery cell voltage for Cell 76";
CM_ SG_ 1178 HVBatCellVlt_77 "High voltage battery cell voltage for Cell 77";
CM_ SG_ 1178 HVBatCellVlt_78 "High voltage battery cell voltage for Cell 78";
CM_ SG_ 1178 HVBatCellVlt_79 "High voltage battery cell voltage for Cell 79";
CM_ SG_ 1178 HVBatCellVlt_80 "High voltage battery cell voltage for Cell 80";
CM_ SG_ 1179 HVBatCellVlt_81 "High voltage battery cell voltage for Cell 81";
CM_ SG_ 1179 HVBatCellVlt_82 "High voltage battery cell voltage for Cell 82";
CM_ SG_ 1179 HVBatCellVlt_83 "High voltage battery cell voltage for Cell 83";
CM_ SG_ 1179 HVBatCellVlt_84 "High voltage battery cell voltage for Cell 84";
CM_ SG_ 1180 HVBatCellVlt_85 "High voltage battery cell voltage for Cell 85";
CM_ SG_ 1180 HVBatCellVlt_86 "High voltage battery cell voltage for Cell 86";
CM_ SG_ 1180 HVBatCellVlt_87 "High voltage battery cell voltage for Cell 87";
CM_ SG_ 1180 HVBatCellVlt_88 "High voltage battery cell voltage for Cell 88";
CM_ SG_ 1181 HVBatCellVlt_89 "High voltage battery cell voltage for Cell 89";
CM_ SG_ 1181 HVBatCellVlt_90 "High voltage battery cell voltage for Cell 90";
CM_ SG_ 1181 HVBatCellVlt_91 "High voltage battery cell voltage for Cell 91";
CM_ SG_ 1181 HVBatCellVlt_92 "High voltage battery cell voltage for Cell 92";
CM_ SG_ 1182 HVBatCellVlt_93 "High voltage battery cell voltage for Cell 93";
CM_ SG_ 1182 HVBatCellVlt_94 "High voltage battery cell voltage for Cell 94";
CM_ SG_ 1182 HVBatCellVlt_95 "High voltage battery cell voltage for Cell 95";
CM_ SG_ 1182 HVBatCellVlt_96 "High voltage battery cell voltage for Cell 96";
CM_ SG_ 1183 HVBatCellVltMax "Max cell voltage";
CM_ SG_ 1183 HVBatCellVltMin "Min cell voltage";
CM_ SG_ 1183 HVBatMod_NumMaxVlt "Module number - maximum voltage; Enumeration  0 = Module 1 ...15 = Module 16.";
CM_ SG_ 1183 HVBatMod_NumMinVlt "Module number - Minimum voltage; Enumeration  0 = Module 1, 15 = Module 16.";
CM_ SG_ 1156 ACSideCurr "AC side current";
CM_ SG_ 1156 ACSideVolt "AC side voltage";
CM_ SG_ 1156 APM_FailureReason "FailureReason";
CM_ SG_ 1156 APM_OperModeStatus "APM Operation  mode  Status";
CM_ SG_ 1156 APM_OutputPower "APM output power";
CM_ SG_ 1156 IsolationResistance "Insulation resistance";
CM_ SG_ 1152 MtrA_RPM "Motor A Speed Raw";
CM_ SG_ 1152 MtrA_Temp "Motor A temperature";
CM_ SG_ 1152 MtrA_TorqAchieved "Motor A Torque Achieved";
CM_ SG_ 1153 MtrA_DC_Crnt "Motor A DC Current";
CM_ SG_ 1153 MtrA_DC_Volt "Motor A DC Voltage";
CM_ SG_ 1153 MtrA_InvrtrTemp "Inverter A Temperature";
CM_ SG_ 1153 MtrA_Invrtr_State "Inverter State of Operation ";
CM_ SG_ 1154 MtrB_RPM "Motor B Speed Raw";
CM_ SG_ 1154 MtrB_Temp "Motor B temperature";
CM_ SG_ 1154 MtrB_TorqAchieved "Motor B Torque Achieved";
CM_ SG_ 1155 MtrB_DC_Crnt "Motor B DC Current";
CM_ SG_ 1155 MtrB_DC_Volt "Motor B DC Voltage";
CM_ SG_ 1155 MtrB_InvrtrTemp "Inverter B Temperature";
CM_ SG_ 1155 MtrB_Invrtr_State "Inverter State of Operation ";
CM_ SG_ 1158 APMPerfWrn "APM performance warning";
CM_ SG_ 1158 APMTempWrn "APM temperature warning";
CM_ SG_ 1158 BPCMCellBalWrn "Poor cell consistency warning";
CM_ SG_ 1158 BPCMCellOverWrn "Cell overvoltage warning";
CM_ SG_ 1158 BPCMCellUnderWrn "Cell undervoltage warning";
CM_ SG_ 1158 BPCMHighSOCWrn "Battery high SOC warning";
CM_ SG_ 1158 BPCMInsulWrn "Insulation warning";
CM_ SG_ 1158 BPCMMaxTempWrn "Battery high temperature warning";
CM_ SG_ 1158 BPCMOverChrgWrn "Overcharge warning";
CM_ SG_ 1158 BPCMOverVoltWrn "Battery overvoltage warning";
CM_ SG_ 1158 BPCMSOCJumpWrn "Battery SOC jump warning";
CM_ SG_ 1158 BPCMSOCLowWrn "Battery low SOC warning";
CM_ SG_ 1158 BPCMTempDiffWrn "Temperature difference warning";
CM_ SG_ 1158 BPCMUnderVoltWrn "Battery undervoltage warning";
CM_ SG_ 1158 BPCMUnmatchedWrn "Battery unmatched warning";
CM_ SG_ 1158 HVILWrn "HV interlock state warning";
CM_ SG_ 1158 HighestWarnLevel "Highest warning level detected";
CM_ SG_ 1158 MtrA_InvOverTempWrn "Motor A inverter over-temperature warning";
CM_ SG_ 1158 MtrA_OverTempWrn "Motor A over-temperature warning";
CM_ SG_ 1158 MtrB_InvOverTempWrn "Motor B inverter over-temperature warning";
CM_ SG_ 1158 MtrB_OverTempWrn "Motor B over-temperature warning";
CM_ SG_ 503 Est_Range_Disp "Estimated electric range for display";
CM_ SG_ 503 VehSpdDisp "Vehicle speed - displayed";
CM_ SG_ 503 VehSpd_MPH "Vehicle speed signal is in miles per hour format";
CM_ SG_ 503 xtended_AvgFuelLvl "Epanded average filtered fuel level in liters";
CM_ SG_ 634 AvgFuelLvl "Average filtered fuel level in liters";
CM_ SG_ 634 FuelLvlLow "Fuel level low";
CM_ SG_ 634 ODO "Odometer";
CM_ SG_ 634 OilChgRst "Oil change reminder reset request";
CM_ SG_ 634 SRS_LMP_STAT "Airbag indicator lamp status";
CM_ SG_ 634 WTS_LmpRqOn "Wait to start lamp requested on; true = [1]";
CM_ SG_ 673 ConsumptionUnit "Fuel consumption units";
CM_ SG_ 673 DistanceUnit "Distance (odometer) units; Miles = [1]";
CM_ SG_ 673 LANG_C "Language preference (5 bit)";
CM_ SG_ 673 PowerUnit "Power units";
CM_ SG_ 673 PressureUnit "Pressure units";
CM_ SG_ 673 RDY_DRV_STAT_CSO "Ready to drive popup status enable/disable; Disabled = [1]";
CM_ SG_ 673 SpeedUnit "Speed (speedometer) units; Miles = [1]";
CM_ SG_ 673 TemperatureUnit "Temperature units; Farenheit = [1]";
CM_ SG_ 673 TorqueUnit "Torque units; Foot Pounds (ft-lb) = [1]";
CM_ SG_ 673 UNIT_SET_CSO "Unit set status enable/disable";
CM_ SG_ 635 Gas_Range "Gas range or DTE";
CM_ SG_ 635 Total_Range "Total range or DTE";
CM_ SG_ 754 Avg_Fuel_Econ "Average fuel economy";
CM_ SG_ 754 Inst_Fuel_Econ "Instantaneous fuel economy";
CM_ SG_ 938 A_EV_Kilometers "Trip A EV distance in kilometers";
CM_ SG_ 938 A_EV_Miles "Trip A EV distance in US miles";
CM_ SG_ 938 A_MPG "Trip A Combined fuel economy in US MPG";
CM_ SG_ 939 A_Hybrid_Kilometers "Trip A hybrid distance in kilometers";
CM_ SG_ 939 A_Hybrid_Miles "Trip A hybrid distance in US miles";
CM_ SG_ 939 A_KMpL "Trip A Combined fuel economy in Km/L";
CM_ SG_ 940 A_Total_Dist_Kilometers "Trip A total distance in kilometers";
CM_ SG_ 940 A_Total_Dist_Miles "Trip A total distance in US miles";
CM_ SG_ 941 B_EV_Kilometers "Trip B EV distance in kilometers";
CM_ SG_ 941 B_EV_Miles "Trip B EV distance in US miles";
CM_ SG_ 941 B_MPG "Trip B Combined fuel economy in US MPG";
CM_ SG_ 942 B_Hybrid_Kilometers "Trip B hybrid distance in kilometers";
CM_ SG_ 942 B_Hybrid_Miles "Trip B hybrid distance in US miles";
CM_ SG_ 942 B_KMpL "Trip B Combined fuel economy in Km/L";
BA_DEF_ BO_  "App-Botschaft" ENUM  "nein","ja";
BA_DEF_ BO_  "CanMsgMinLen" INT 0 8;
BA_DEF_ BO_  "DiagRequest" ENUM  "nein","ja";
BA_DEF_ BO_  "DiagResponse" ENUM  "nein","ja";
BA_DEF_ BO_  "DiagState" ENUM  "nein","ja";
BA_DEF_ BO_  "GenMsgCycleTime" INT 0 65535;
BA_DEF_ BO_  "GenMsgCycleTimeActive" INT 0 65535;
BA_DEF_ BO_  "GenMsgDelayTime" INT 0 65535;
BA_DEF_ BO_  "GenMsgNrOfRepetitions" INT 0 65535;
BA_DEF_ BO_  "GenMsgSendType" ENUM  "cyclicX","spontanX","cyclicIfActiveX","spontanWithDelay","cyclicAndSpontanX","cyclicAndSpontanWithDelay","spontanWithRepitition","cyclicIfActiveAndSpontanWD","cyclicIfActiveFast","cyclicWithRepeatOnDemand","none";
BA_DEF_ BO_  "GenMsgStartDelayTime" INT 0 65535;
BA_DEF_ BO_  "GenMsgStartValue" STRING ;
BA_DEF_ BO_  "NWM-Botschaft" ENUM  "nein","ja";
BA_DEF_ BO_  "TpTxIndex" INT 0 99;
BA_DEF_ SG_  "FlexKomComment" STRING ;
BA_DEF_ SG_  "FlexKomIsMotorola" ENUM  "nein","ja";
BA_DEF_ SG_  "FlexKomSID" INT 0 2147483647;
BA_DEF_ SG_  "FlexKomSigLaenge" INT 0 64;
BA_DEF_ SG_  "FlexKomSigName" STRING ;
BA_DEF_ SG_  "FlexKomSigStartPos" INT 0 63;
BA_DEF_ SG_  "FlexKomSigStartValue" STRING ;
BA_DEF_ SG_  "GenSigCycleTime" INT 0 65535;
BA_DEF_ SG_  "GenSigCycleTimeActive" INT 0 65535;
BA_DEF_ SG_  "GenSigSendType" ENUM  "cyclicX","spontanX","cyclicIfActiveX","spontanWithDelay","cyclicAndSpontanX","cyclicAndSpontanWithDelay","spontanWithRepitition","cyclicIfActiveAndSpontanWD","cyclicIfActiveFast","cyclicWithRepeatOnDemand","none";
BA_DEF_ SG_  "GenSigSNA" STRING ;
BA_DEF_ SG_  "GenSigStartValue" HEX 0 2147483648;
BA_DEF_ SG_  "GenSigTimeout_AHLM" INT 0 65535;
BA_DEF_ SG_  "GenSigTimeout_ASBS" INT 0 65535;
BA_DEF_ SG_  "GenSigTimeout_CBC" INT 0 65535;
BA_DEF_ SG_  "GenSigTimeout_DPDM" INT 0 65535;
BA_DEF_ SG_  "GenSigTimeout_DTCM" INT 0 65535;
BA_DEF_ SG_  "GenSigTimeout_EHPS" INT 0 65535;
BA_DEF_ SG_  "GenSigTimeout_ESC" INT 0 65535;
BA_DEF_ SG_  "GenSigTimeout_ESL" INT 0 65535;
BA_DEF_ SG_  "GenSigTimeout_ESM" INT 0 65535;
BA_DEF_ SG_  "GenSigTimeout_ETM" INT 0 65535;
BA_DEF_ SG_  "GenSigTimeout_IC" INT 0 65535;
BA_DEF_ SG_  "GenSigTimeout_OCM" INT 0 65535;
BA_DEF_ SG_  "GenSigTimeout_ORC" INT 0 65535;
BA_DEF_ SG_  "GenSigTimeout_PTS" INT 0 65535;
BA_DEF_ SG_  "GenSigTimeout_RF_HUB" INT 0 65535;
BA_DEF_ SG_  "GenSigTimeout_SCCM" INT 0 65535;
BA_DEF_ SG_  "GenSigTimeout_TBM" INT 0 65535;
BA_DEF_ SG_  "GenSigTimeout_TCM" INT 0 65535;
BA_DEF_ SG_  "GenSigTimeout_TPM" INT 0 65535;
BA_DEF_ SG_  "RID" STRING ;
BA_DEF_ SG_  "SystemSignalLongSymbol" STRING ;
BA_DEF_DEF_  "App-Botschaft" "nein";
BA_DEF_DEF_  "CanMsgMinLen" 0;
BA_DEF_DEF_  "DiagRequest" "nein";
BA_DEF_DEF_  "DiagResponse" "nein";
BA_DEF_DEF_  "DiagState" "nein";
BA_DEF_DEF_  "GenMsgCycleTime" 0;
BA_DEF_DEF_  "GenMsgCycleTimeActive" 0;
BA_DEF_DEF_  "GenMsgDelayTime" 0;
BA_DEF_DEF_  "GenMsgNrOfRepetitions" 0;
BA_DEF_DEF_  "GenMsgSendType" "cyclicX";
BA_DEF_DEF_  "GenMsgStartDelayTime" 0;
BA_DEF_DEF_  "GenMsgStartValue" "";
BA_DEF_DEF_  "NWM-Botschaft" "nein";
BA_DEF_DEF_  "TpTxIndex" 0;
BA_DEF_DEF_  "FlexKomComment" "";
BA_DEF_DEF_  "FlexKomIsMotorola" "nein";
BA_DEF_DEF_  "FlexKomSID" 0;
BA_DEF_DEF_  "FlexKomSigLaenge" 0;
BA_DEF_DEF_  "FlexKomSigName" "";
BA_DEF_DEF_  "FlexKomSigStartPos" 0;
BA_DEF_DEF_  "FlexKomSigStartValue" "";
BA_DEF_DEF_  "GenSigCycleTime" 0;
BA_DEF_DEF_  "GenSigCycleTimeActive" 0;
BA_DEF_DEF_  "GenSigSendType" "cyclicX";
BA_DEF_DEF_  "GenSigSNA" "";
BA_DEF_DEF_  "GenSigStartValue" 0;
BA_DEF_DEF_  "GenSigTimeout_AHLM" 0;
BA_DEF_DEF_  "GenSigTimeout_ASBS" 0;
BA_DEF_DEF_  "GenSigTimeout_CBC" 0;
BA_DEF_DEF_  "GenSigTimeout_DPDM" 0;
BA_DEF_DEF_  "GenSigTimeout_DTCM" 0;
BA_DEF_DEF_  "GenSigTimeout_EHPS" 0;
BA_DEF_DEF_  "GenSigTimeout_ESC" 0;
BA_DEF_DEF_  "GenSigTimeout_ESL" 0;
BA_DEF_DEF_  "GenSigTimeout_ESM" 0;
BA_DEF_DEF_  "GenSigTimeout_ETM" 0;
BA_DEF_DEF_  "GenSigTimeout_IC" 0;
BA_DEF_DEF_  "GenSigTimeout_OCM" 0;
BA_DEF_DEF_  "GenSigTimeout_ORC" 0;
BA_DEF_DEF_  "GenSigTimeout_PTS" 0;
BA_DEF_DEF_  "GenSigTimeout_RF_HUB" 0;
BA_DEF_DEF_  "GenSigTimeout_SCCM" 0;
BA_DEF_DEF_  "GenSigTimeout_TBM" 0;
BA_DEF_DEF_  "GenSigTimeout_TCM" 0;
BA_DEF_DEF_  "GenSigTimeout_TPM" 0;
BA_DEF_DEF_  "RID" "";
BA_DEF_DEF_  "SystemSignalLongSymbol" "";
BA_ "GenMsgStartValue" BO_ 803 "0000000000000000h";
BA_ "GenMsgSendType" BO_ 803 5;
BA_ "GenMsgNrOfRepetitions" BO_ 803 2;
BA_ "GenMsgDelayTime" BO_ 803 20;
BA_ "GenMsgCycleTime" BO_ 803 1000;
BA_ "GenMsgStartValue" BO_ 560 "0800000000000000h";
BA_ "GenMsgSendType" BO_ 560 5;
BA_ "GenMsgNrOfRepetitions" BO_ 560 2;
BA_ "GenMsgDelayTime" BO_ 560 20;
BA_ "GenMsgCycleTime" BO_ 560 500;
BA_ "GenMsgStartValue" BO_ 818 "03FF03FF00000000h";
BA_ "GenMsgSendType" BO_ 818 5;
BA_ "GenMsgNrOfRepetitions" BO_ 818 2;
BA_ "GenMsgDelayTime" BO_ 818 20;
BA_ "GenMsgCycleTime" BO_ 818 1000;
BA_ "GenMsgStartValue" BO_ 807 "0000000000000000h";
BA_ "GenMsgSendType" BO_ 807 5;
BA_ "GenMsgNrOfRepetitions" BO_ 807 2;
BA_ "GenMsgDelayTime" BO_ 807 20;
BA_ "GenMsgCycleTime" BO_ 807 1000;
BA_ "GenMsgStartValue" BO_ 1184 "000000000000h";
BA_ "GenMsgNrOfRepetitions" BO_ 1184 2;
BA_ "GenMsgDelayTime" BO_ 1184 20;
BA_ "GenMsgCycleTime" BO_ 1184 1000;
BA_ "GenMsgStartValue" BO_ 1185 "000000000000h";
BA_ "GenMsgNrOfRepetitions" BO_ 1185 2;
BA_ "GenMsgDelayTime" BO_ 1185 20;
BA_ "GenMsgCycleTime" BO_ 1185 1000;
BA_ "GenMsgStartValue" BO_ 1186 "00000000h";
BA_ "GenMsgNrOfRepetitions" BO_ 1186 2;
BA_ "GenMsgDelayTime" BO_ 1186 20;
BA_ "GenMsgCycleTime" BO_ 1186 1000;
BA_ "GenMsgStartValue" BO_ 1194 "0F00000000000000h";
BA_ "GenMsgNrOfRepetitions" BO_ 1194 2;
BA_ "GenMsgDelayTime" BO_ 1194 20;
BA_ "GenMsgCycleTime" BO_ 1194 250;
BA_ "GenMsgStartValue" BO_ 1157 "000000007F7F0000h";
BA_ "GenMsgNrOfRepetitions" BO_ 1157 2;
BA_ "GenMsgDelayTime" BO_ 1157 20;
BA_ "GenMsgCycleTime" BO_ 1157 1000;
BA_ "GenMsgStartValue" BO_ 1159 "0000000000000000h";
BA_ "GenMsgNrOfRepetitions" BO_ 1159 2;
BA_ "GenMsgDelayTime" BO_ 1159 20;
BA_ "GenMsgCycleTime" BO_ 1159 1000;
BA_ "GenMsgStartValue" BO_ 1160 "0000000000000000h";
BA_ "GenMsgNrOfRepetitions" BO_ 1160 2;
BA_ "GenMsgDelayTime" BO_ 1160 20;
BA_ "GenMsgCycleTime" BO_ 1160 1000;
BA_ "GenMsgStartValue" BO_ 1161 "0000000000000000h";
BA_ "GenMsgNrOfRepetitions" BO_ 1161 2;
BA_ "GenMsgDelayTime" BO_ 1161 20;
BA_ "GenMsgCycleTime" BO_ 1161 1000;
BA_ "GenMsgStartValue" BO_ 1162 "0000000000000000h";
BA_ "GenMsgNrOfRepetitions" BO_ 1162 2;
BA_ "GenMsgDelayTime" BO_ 1162 20;
BA_ "GenMsgCycleTime" BO_ 1162 1000;
BA_ "GenMsgStartValue" BO_ 1163 "0000000000000000h";
BA_ "GenMsgNrOfRepetitions" BO_ 1163 2;
BA_ "GenMsgDelayTime" BO_ 1163 20;
BA_ "GenMsgCycleTime" BO_ 1163 1000;
BA_ "GenMsgStartValue" BO_ 1164 "0000000000000000h";
BA_ "GenMsgNrOfRepetitions" BO_ 1164 2;
BA_ "GenMsgDelayTime" BO_ 1164 20;
BA_ "GenMsgCycleTime" BO_ 1164 1000;
BA_ "GenMsgStartValue" BO_ 1165 "0000000000000000h";
BA_ "GenMsgNrOfRepetitions" BO_ 1165 2;
BA_ "GenMsgDelayTime" BO_ 1165 20;
BA_ "GenMsgCycleTime" BO_ 1165 1000;
BA_ "GenMsgStartValue" BO_ 1166 "0000000000000000h";
BA_ "GenMsgNrOfRepetitions" BO_ 1166 2;
BA_ "GenMsgDelayTime" BO_ 1166 20;
BA_ "GenMsgCycleTime" BO_ 1166 1000;
BA_ "GenMsgStartValue" BO_ 1167 "0000000000000000h";
BA_ "GenMsgNrOfRepetitions" BO_ 1167 2;
BA_ "GenMsgDelayTime" BO_ 1167 20;
BA_ "GenMsgCycleTime" BO_ 1167 1000;
BA_ "GenMsgStartValue" BO_ 1168 "0000000000000000h";
BA_ "GenMsgNrOfRepetitions" BO_ 1168 2;
BA_ "GenMsgDelayTime" BO_ 1168 20;
BA_ "GenMsgCycleTime" BO_ 1168 1000;
BA_ "GenMsgStartValue" BO_ 1169 "0000000000000000h";
BA_ "GenMsgNrOfRepetitions" BO_ 1169 2;
BA_ "GenMsgDelayTime" BO_ 1169 20;
BA_ "GenMsgCycleTime" BO_ 1169 1000;
BA_ "GenMsgStartValue" BO_ 1170 "0000000000000000h";
BA_ "GenMsgNrOfRepetitions" BO_ 1170 2;
BA_ "GenMsgDelayTime" BO_ 1170 20;
BA_ "GenMsgCycleTime" BO_ 1170 1000;
BA_ "GenMsgStartValue" BO_ 1171 "0000000000000000h";
BA_ "GenMsgNrOfRepetitions" BO_ 1171 2;
BA_ "GenMsgDelayTime" BO_ 1171 20;
BA_ "GenMsgCycleTime" BO_ 1171 1000;
BA_ "GenMsgStartValue" BO_ 1172 "0000000000000000h";
BA_ "GenMsgNrOfRepetitions" BO_ 1172 2;
BA_ "GenMsgDelayTime" BO_ 1172 20;
BA_ "GenMsgCycleTime" BO_ 1172 1000;
BA_ "GenMsgStartValue" BO_ 1173 "0000000000000000h";
BA_ "GenMsgNrOfRepetitions" BO_ 1173 2;
BA_ "GenMsgDelayTime" BO_ 1173 20;
BA_ "GenMsgCycleTime" BO_ 1173 1000;
BA_ "GenMsgStartValue" BO_ 1174 "0000000000000000h";
BA_ "GenMsgNrOfRepetitions" BO_ 1174 2;
BA_ "GenMsgDelayTime" BO_ 1174 20;
BA_ "GenMsgCycleTime" BO_ 1174 1000;
BA_ "GenMsgStartValue" BO_ 1175 "0000000000000000h";
BA_ "GenMsgNrOfRepetitions" BO_ 1175 2;
BA_ "GenMsgDelayTime" BO_ 1175 20;
BA_ "GenMsgCycleTime" BO_ 1175 1000;
BA_ "GenMsgStartValue" BO_ 1176 "0000000000000000h";
BA_ "GenMsgNrOfRepetitions" BO_ 1176 2;
BA_ "GenMsgDelayTime" BO_ 1176 20;
BA_ "GenMsgCycleTime" BO_ 1176 1000;
BA_ "GenMsgStartValue" BO_ 1177 "0000000000000000h";
BA_ "GenMsgNrOfRepetitions" BO_ 1177 2;
BA_ "GenMsgDelayTime" BO_ 1177 20;
BA_ "GenMsgCycleTime" BO_ 1177 1000;
BA_ "GenMsgStartValue" BO_ 1178 "0000000000000000h";
BA_ "GenMsgNrOfRepetitions" BO_ 1178 2;
BA_ "GenMsgDelayTime" BO_ 1178 20;
BA_ "GenMsgCycleTime" BO_ 1178 1000;
BA_ "GenMsgStartValue" BO_ 1179 "0000000000000000h";
BA_ "GenMsgNrOfRepetitions" BO_ 1179 2;
BA_ "GenMsgDelayTime" BO_ 1179 20;
BA_ "GenMsgCycleTime" BO_ 1179 1000;
BA_ "GenMsgStartValue" BO_ 1180 "0000000000000000h";
BA_ "GenMsgNrOfRepetitions" BO_ 1180 2;
BA_ "GenMsgDelayTime" BO_ 1180 20;
BA_ "GenMsgCycleTime" BO_ 1180 1000;
BA_ "GenMsgStartValue" BO_ 1181 "0000000000000000h";
BA_ "GenMsgNrOfRepetitions" BO_ 1181 2;
BA_ "GenMsgDelayTime" BO_ 1181 20;
BA_ "GenMsgCycleTime" BO_ 1181 1000;
BA_ "GenMsgStartValue" BO_ 1182 "0000000000000000h";
BA_ "GenMsgNrOfRepetitions" BO_ 1182 2;
BA_ "GenMsgDelayTime" BO_ 1182 20;
BA_ "GenMsgCycleTime" BO_ 1182 1000;
BA_ "GenMsgStartValue" BO_ 1183 "000000000000h";
BA_ "GenMsgNrOfRepetitions" BO_ 1183 2;
BA_ "GenMsgDelayTime" BO_ 1183 20;
BA_ "GenMsgCycleTime" BO_ 1183 1000;
BA_ "GenMsgStartValue" BO_ 1156 "0000000000000000h";
BA_ "GenMsgNrOfRepetitions" BO_ 1156 2;
BA_ "GenMsgDelayTime" BO_ 1156 20;
BA_ "GenMsgCycleTime" BO_ 1156 1000;
BA_ "GenMsgStartValue" BO_ 1152 "800010002800h";
BA_ "GenMsgNrOfRepetitions" BO_ 1152 2;
BA_ "GenMsgDelayTime" BO_ 1152 20;
BA_ "GenMsgCycleTime" BO_ 1152 1000;
BA_ "GenMsgStartValue" BO_ 1153 "400000002800h";
BA_ "GenMsgNrOfRepetitions" BO_ 1153 2;
BA_ "GenMsgDelayTime" BO_ 1153 20;
BA_ "GenMsgCycleTime" BO_ 1153 1000;
BA_ "GenMsgStartValue" BO_ 1154 "800010002800h";
BA_ "GenMsgNrOfRepetitions" BO_ 1154 2;
BA_ "GenMsgDelayTime" BO_ 1154 20;
BA_ "GenMsgCycleTime" BO_ 1154 1000;
BA_ "GenMsgStartValue" BO_ 1155 "400000002800h";
BA_ "GenMsgNrOfRepetitions" BO_ 1155 2;
BA_ "GenMsgDelayTime" BO_ 1155 20;
BA_ "GenMsgCycleTime" BO_ 1155 1000;
BA_ "GenMsgStartValue" BO_ 1158 "0000000000000000h";
BA_ "GenMsgNrOfRepetitions" BO_ 1158 2;
BA_ "GenMsgDelayTime" BO_ 1158 20;
BA_ "GenMsgCycleTime" BO_ 1158 1000;
BA_ "GenMsgStartValue" BO_ 503 "FFFF0FFF0000FFFFh";
BA_ "GenMsgNrOfRepetitions" BO_ 503 2;
BA_ "GenMsgDelayTime" BO_ 503 20;
BA_ "GenMsgCycleTime" BO_ 503 500;
BA_ "GenMsgStartValue" BO_ 634 "01FF0000FFFFFF07h";
BA_ "GenMsgSendType" BO_ 634 5;
BA_ "GenMsgNrOfRepetitions" BO_ 634 2;
BA_ "GenMsgDelayTime" BO_ 634 20;
BA_ "GenMsgCycleTime" BO_ 634 1000;
BA_ "GenMsgStartValue" BO_ 673 "00F8FCF001FE01FEh";
BA_ "GenMsgSendType" BO_ 673 5;
BA_ "GenMsgNrOfRepetitions" BO_ 673 2;
BA_ "GenMsgDelayTime" BO_ 673 20;
BA_ "GenMsgCycleTime" BO_ 673 1000;
BA_ "GenMsgStartValue" BO_ 635 "A3FF07FF00000000h";
BA_ "GenMsgSendType" BO_ 635 5;
BA_ "GenMsgNrOfRepetitions" BO_ 635 2;
BA_ "GenMsgDelayTime" BO_ 635 20;
BA_ "GenMsgCycleTime" BO_ 635 1000;
BA_ "GenMsgStartValue" BO_ 754 "0000000003FF03FFh";
BA_ "GenMsgNrOfRepetitions" BO_ 754 2;
BA_ "GenMsgDelayTime" BO_ 754 20;
BA_ "GenMsgCycleTime" BO_ 754 100;
BA_ "GenMsgStartValue" BO_ 938 "0000000000000000h";
BA_ "GenMsgNrOfRepetitions" BO_ 938 2;
BA_ "GenMsgDelayTime" BO_ 938 20;
BA_ "GenMsgCycleTime" BO_ 938 1000;
BA_ "GenMsgStartValue" BO_ 939 "0000000000000000h";
BA_ "GenMsgStartDelayTime" BO_ 939 50;
BA_ "GenMsgNrOfRepetitions" BO_ 939 2;
BA_ "GenMsgDelayTime" BO_ 939 20;
BA_ "GenMsgCycleTime" BO_ 939 1000;
BA_ "GenMsgStartValue" BO_ 940 "00FF000000000000h";
BA_ "GenMsgStartDelayTime" BO_ 940 100;
BA_ "GenMsgNrOfRepetitions" BO_ 940 2;
BA_ "GenMsgDelayTime" BO_ 940 20;
BA_ "GenMsgCycleTime" BO_ 940 1000;
BA_ "GenMsgStartValue" BO_ 941 "0000000000000000h";
BA_ "GenMsgStartDelayTime" BO_ 941 150;
BA_ "GenMsgNrOfRepetitions" BO_ 941 2;
BA_ "GenMsgDelayTime" BO_ 941 20;
BA_ "GenMsgCycleTime" BO_ 941 1000;
BA_ "GenMsgStartValue" BO_ 942 "0000000000000000h";
BA_ "GenMsgStartDelayTime" BO_ 942 200;
BA_ "GenMsgNrOfRepetitions" BO_ 942 2;
BA_ "GenMsgDelayTime" BO_ 942 20;
BA_ "GenMsgCycleTime" BO_ 942 1000;
BA_ "RID" SG_ 803 Batt_CabinPriority3 "6620";
BA_ "GenSigSNA" SG_ 803 Batt_CabinPriority3 "0h";
BA_ "GenSigSendType" SG_ 803 Batt_CabinPriority3 5;
BA_ "GenSigCycleTime" SG_ 803 Batt_CabinPriority3 1000;
BA_ "FlexKomSigStartValue" SG_ 803 Batt_CabinPriority3 "0000000000000000h";
BA_ "FlexKomSigStartPos" SG_ 803 Batt_CabinPriority3 7;
BA_ "FlexKomSigName" SG_ 803 Batt_CabinPriority3 "HU_Schedule3";
BA_ "FlexKomSigLaenge" SG_ 803 Batt_CabinPriority3 64;
BA_ "FlexKomSID" SG_ 803 Batt_CabinPriority3 3110;
BA_ "FlexKomIsMotorola" SG_ 803 Batt_CabinPriority3 1;
BA_ "FlexKomComment" SG_ 803 Batt_CabinPriority3 "HU_Schedule3";
BA_ "RID" SG_ 803 ChargeUntilFull3 "6674";
BA_ "GenSigSNA" SG_ 803 ChargeUntilFull3 "0h";
BA_ "GenSigSendType" SG_ 803 ChargeUntilFull3 5;
BA_ "GenSigCycleTime" SG_ 803 ChargeUntilFull3 1000;
BA_ "FlexKomSigStartValue" SG_ 803 ChargeUntilFull3 "0000000000000000h";
BA_ "FlexKomSigStartPos" SG_ 803 ChargeUntilFull3 7;
BA_ "FlexKomSigName" SG_ 803 ChargeUntilFull3 "HU_Schedule3";
BA_ "FlexKomSigLaenge" SG_ 803 ChargeUntilFull3 64;
BA_ "FlexKomSID" SG_ 803 ChargeUntilFull3 3110;
BA_ "FlexKomIsMotorola" SG_ 803 ChargeUntilFull3 1;
BA_ "FlexKomComment" SG_ 803 ChargeUntilFull3 "HU_Schedule3";
BA_ "RID" SG_ 803 Do_Not_Repeat3 "6652";
BA_ "GenSigSNA" SG_ 803 Do_Not_Repeat3 "0h";
BA_ "GenSigSendType" SG_ 803 Do_Not_Repeat3 5;
BA_ "GenSigCycleTime" SG_ 803 Do_Not_Repeat3 1000;
BA_ "FlexKomSigStartValue" SG_ 803 Do_Not_Repeat3 "0000000000000000h";
BA_ "FlexKomSigStartPos" SG_ 803 Do_Not_Repeat3 7;
BA_ "FlexKomSigName" SG_ 803 Do_Not_Repeat3 "HU_Schedule3";
BA_ "FlexKomSigLaenge" SG_ 803 Do_Not_Repeat3 64;
BA_ "FlexKomSID" SG_ 803 Do_Not_Repeat3 3110;
BA_ "FlexKomIsMotorola" SG_ 803 Do_Not_Repeat3 1;
BA_ "FlexKomComment" SG_ 803 Do_Not_Repeat3 "HU_Schedule3";
BA_ "RID" SG_ 803 Enable_Schedule3 "6699";
BA_ "GenSigSNA" SG_ 803 Enable_Schedule3 "0h";
BA_ "GenSigSendType" SG_ 803 Enable_Schedule3 5;
BA_ "GenSigCycleTime" SG_ 803 Enable_Schedule3 1000;
BA_ "FlexKomSigStartValue" SG_ 803 Enable_Schedule3 "0000000000000000h";
BA_ "FlexKomSigStartPos" SG_ 803 Enable_Schedule3 7;
BA_ "FlexKomSigName" SG_ 803 Enable_Schedule3 "HU_Schedule3";
BA_ "FlexKomSigLaenge" SG_ 803 Enable_Schedule3 64;
BA_ "FlexKomSID" SG_ 803 Enable_Schedule3 3110;
BA_ "FlexKomIsMotorola" SG_ 803 Enable_Schedule3 1;
BA_ "FlexKomComment" SG_ 803 Enable_Schedule3 "HU_Schedule3";
BA_ "RID" SG_ 803 End_Time_Hr3 "6622";
BA_ "GenSigSNA" SG_ 803 End_Time_Hr3 "1Fh";
BA_ "GenSigSendType" SG_ 803 End_Time_Hr3 5;
BA_ "GenSigCycleTime" SG_ 803 End_Time_Hr3 1000;
BA_ "FlexKomSigStartValue" SG_ 803 End_Time_Hr3 "0000000000000000h";
BA_ "FlexKomSigStartPos" SG_ 803 End_Time_Hr3 7;
BA_ "FlexKomSigName" SG_ 803 End_Time_Hr3 "HU_Schedule3";
BA_ "FlexKomSigLaenge" SG_ 803 End_Time_Hr3 64;
BA_ "FlexKomSID" SG_ 803 End_Time_Hr3 3110;
BA_ "FlexKomIsMotorola" SG_ 803 End_Time_Hr3 1;
BA_ "FlexKomComment" SG_ 803 End_Time_Hr3 "HU_Schedule3";
BA_ "RID" SG_ 803 End_Time_Min3 "6638";
BA_ "GenSigSNA" SG_ 803 End_Time_Min3 "Fh";
BA_ "GenSigSendType" SG_ 803 End_Time_Min3 5;
BA_ "GenSigCycleTime" SG_ 803 End_Time_Min3 1000;
BA_ "FlexKomSigStartValue" SG_ 803 End_Time_Min3 "0000000000000000h";
BA_ "FlexKomSigStartPos" SG_ 803 End_Time_Min3 7;
BA_ "FlexKomSigName" SG_ 803 End_Time_Min3 "HU_Schedule3";
BA_ "FlexKomSigLaenge" SG_ 803 End_Time_Min3 64;
BA_ "FlexKomSID" SG_ 803 End_Time_Min3 3110;
BA_ "FlexKomIsMotorola" SG_ 803 End_Time_Min3 1;
BA_ "FlexKomComment" SG_ 803 End_Time_Min3 "HU_Schedule3";
BA_ "RID" SG_ 803 Schedule_Day3 "6683";
BA_ "GenSigSNA" SG_ 803 Schedule_Day3 "FFh";
BA_ "GenSigSendType" SG_ 803 Schedule_Day3 5;
BA_ "GenSigCycleTime" SG_ 803 Schedule_Day3 1000;
BA_ "FlexKomSigStartValue" SG_ 803 Schedule_Day3 "0000000000000000h";
BA_ "FlexKomSigStartPos" SG_ 803 Schedule_Day3 7;
BA_ "FlexKomSigName" SG_ 803 Schedule_Day3 "HU_Schedule3";
BA_ "FlexKomSigLaenge" SG_ 803 Schedule_Day3 64;
BA_ "FlexKomSID" SG_ 803 Schedule_Day3 3110;
BA_ "FlexKomIsMotorola" SG_ 803 Schedule_Day3 1;
BA_ "FlexKomComment" SG_ 803 Schedule_Day3 "HU_Schedule3";
BA_ "RID" SG_ 803 Schedule_Type3 "6649";
BA_ "GenSigSNA" SG_ 803 Schedule_Type3 "3h";
BA_ "GenSigSendType" SG_ 803 Schedule_Type3 5;
BA_ "GenSigCycleTime" SG_ 803 Schedule_Type3 1000;
BA_ "FlexKomSigStartValue" SG_ 803 Schedule_Type3 "0000000000000000h";
BA_ "FlexKomSigStartPos" SG_ 803 Schedule_Type3 7;
BA_ "FlexKomSigName" SG_ 803 Schedule_Type3 "HU_Schedule3";
BA_ "FlexKomSigLaenge" SG_ 803 Schedule_Type3 64;
BA_ "FlexKomSID" SG_ 803 Schedule_Type3 3110;
BA_ "FlexKomIsMotorola" SG_ 803 Schedule_Type3 1;
BA_ "FlexKomComment" SG_ 803 Schedule_Type3 "HU_Schedule3";
BA_ "RID" SG_ 803 Start_Time_Hr3 "6628";
BA_ "GenSigSNA" SG_ 803 Start_Time_Hr3 "1Fh";
BA_ "GenSigSendType" SG_ 803 Start_Time_Hr3 5;
BA_ "GenSigCycleTime" SG_ 803 Start_Time_Hr3 1000;
BA_ "FlexKomSigStartValue" SG_ 803 Start_Time_Hr3 "0000000000000000h";
BA_ "FlexKomSigStartPos" SG_ 803 Start_Time_Hr3 7;
BA_ "FlexKomSigName" SG_ 803 Start_Time_Hr3 "HU_Schedule3";
BA_ "FlexKomSigLaenge" SG_ 803 Start_Time_Hr3 64;
BA_ "FlexKomSID" SG_ 803 Start_Time_Hr3 3110;
BA_ "FlexKomIsMotorola" SG_ 803 Start_Time_Hr3 1;
BA_ "FlexKomComment" SG_ 803 Start_Time_Hr3 "HU_Schedule3";
BA_ "RID" SG_ 803 Start_Time_Min3 "6688";
BA_ "GenSigSNA" SG_ 803 Start_Time_Min3 "Fh";
BA_ "GenSigSendType" SG_ 803 Start_Time_Min3 5;
BA_ "GenSigCycleTime" SG_ 803 Start_Time_Min3 1000;
BA_ "FlexKomSigStartValue" SG_ 803 Start_Time_Min3 "0000000000000000h";
BA_ "FlexKomSigStartPos" SG_ 803 Start_Time_Min3 7;
BA_ "FlexKomSigName" SG_ 803 Start_Time_Min3 "HU_Schedule3";
BA_ "FlexKomSigLaenge" SG_ 803 Start_Time_Min3 64;
BA_ "FlexKomSID" SG_ 803 Start_Time_Min3 3110;
BA_ "FlexKomIsMotorola" SG_ 803 Start_Time_Min3 1;
BA_ "FlexKomComment" SG_ 803 Start_Time_Min3 "HU_Schedule3";
BA_ "RID" SG_ 803 Submit_Schedule3 "6610";
BA_ "GenSigSNA" SG_ 803 Submit_Schedule3 "0h";
BA_ "GenSigSendType" SG_ 803 Submit_Schedule3 5;
BA_ "GenSigCycleTime" SG_ 803 Submit_Schedule3 1000;
BA_ "FlexKomSigStartValue" SG_ 803 Submit_Schedule3 "0000000000000000h";
BA_ "FlexKomSigStartPos" SG_ 803 Submit_Schedule3 7;
BA_ "FlexKomSigName" SG_ 803 Submit_Schedule3 "HU_Schedule3";
BA_ "FlexKomSigLaenge" SG_ 803 Submit_Schedule3 64;
BA_ "FlexKomSID" SG_ 803 Submit_Schedule3 3110;
BA_ "FlexKomIsMotorola" SG_ 803 Submit_Schedule3 1;
BA_ "FlexKomComment" SG_ 803 Submit_Schedule3 "HU_Schedule3";
BA_ "RID" SG_ 560 AC_PT_Demand "1916";
BA_ "GenSigSNA" SG_ 560 AC_PT_Demand "0h";
BA_ "GenSigSendType" SG_ 560 AC_PT_Demand 5;
BA_ "GenSigCycleTime" SG_ 560 AC_PT_Demand 500;
BA_ "FlexKomSigStartValue" SG_ 560 AC_PT_Demand "00h";
BA_ "FlexKomSigStartPos" SG_ 560 AC_PT_Demand 5;
BA_ "FlexKomSigName" SG_ 560 AC_PT_Demand "AC_PT_Demand";
BA_ "FlexKomSigLaenge" SG_ 560 AC_PT_Demand 1;
BA_ "FlexKomSID" SG_ 560 AC_PT_Demand 1945;
BA_ "FlexKomIsMotorola" SG_ 560 AC_PT_Demand 1;
BA_ "FlexKomComment" SG_ 560 AC_PT_Demand "Maximum A/C demand to powertrain";
BA_ "RID" SG_ 560 AC_RQ "1237";
BA_ "GenSigSNA" SG_ 560 AC_RQ "0h";
BA_ "GenSigSendType" SG_ 560 AC_RQ 5;
BA_ "GenSigCycleTime" SG_ 560 AC_RQ 500;
BA_ "FlexKomSigStartValue" SG_ 560 AC_RQ "00h";
BA_ "FlexKomSigName" SG_ 560 AC_RQ "AC_RQ";
BA_ "FlexKomSigLaenge" SG_ 560 AC_RQ 1;
BA_ "FlexKomSID" SG_ 560 AC_RQ 27;
BA_ "FlexKomIsMotorola" SG_ 560 AC_RQ 1;
BA_ "FlexKomComment" SG_ 560 AC_RQ "A/C clutch request; [1] = A/C Clutch requested; 0 ";
BA_ "RID" SG_ 560 AC_SEL "1154";
BA_ "GenSigSNA" SG_ 560 AC_SEL "0h";
BA_ "GenSigSendType" SG_ 560 AC_SEL 5;
BA_ "GenSigCycleTime" SG_ 560 AC_SEL 500;
BA_ "FlexKomSigStartValue" SG_ 560 AC_SEL "00h";
BA_ "FlexKomSigStartPos" SG_ 560 AC_SEL 1;
BA_ "FlexKomSigName" SG_ 560 AC_SEL "AC_SEL";
BA_ "FlexKomSigLaenge" SG_ 560 AC_SEL 1;
BA_ "FlexKomSID" SG_ 560 AC_SEL 31;
BA_ "FlexKomIsMotorola" SG_ 560 AC_SEL 1;
BA_ "FlexKomComment" SG_ 560 AC_SEL "Customer has selected A/C; [1] = A/C selected; 0 =";
BA_ "RID" SG_ 560 DEFROST_SEL "1103";
BA_ "GenSigSNA" SG_ 560 DEFROST_SEL "0h";
BA_ "GenSigSendType" SG_ 560 DEFROST_SEL 5;
BA_ "GenSigCycleTime" SG_ 560 DEFROST_SEL 500;
BA_ "FlexKomSigStartValue" SG_ 560 DEFROST_SEL "00h";
BA_ "FlexKomSigStartPos" SG_ 560 DEFROST_SEL 2;
BA_ "FlexKomSigName" SG_ 560 DEFROST_SEL "DEFROST_SEL";
BA_ "FlexKomSigLaenge" SG_ 560 DEFROST_SEL 1;
BA_ "FlexKomSID" SG_ 560 DEFROST_SEL 28;
BA_ "FlexKomIsMotorola" SG_ 560 DEFROST_SEL 1;
BA_ "FlexKomComment" SG_ 560 DEFROST_SEL "Defrost select switch";
BA_ "RID" SG_ 560 EVAP_TEMP "1096";
BA_ "GenSigSNA" SG_ 560 EVAP_TEMP "FFh";
BA_ "GenSigSendType" SG_ 560 EVAP_TEMP 5;
BA_ "GenSigCycleTime" SG_ 560 EVAP_TEMP 500;
BA_ "FlexKomSigStartValue" SG_ 560 EVAP_TEMP "00h";
BA_ "FlexKomSigStartPos" SG_ 560 EVAP_TEMP 15;
BA_ "FlexKomSigName" SG_ 560 EVAP_TEMP "EVAP_TEMP";
BA_ "FlexKomSigLaenge" SG_ 560 EVAP_TEMP 8;
BA_ "FlexKomSID" SG_ 560 EVAP_TEMP 29;
BA_ "FlexKomIsMotorola" SG_ 560 EVAP_TEMP 1;
BA_ "FlexKomComment" SG_ 560 EVAP_TEMP "AC evaporator temperature";
BA_ "GenSigSNA" SG_ 560 EVAP_TEMP_P1C "7FFh";
BA_ "GenSigCycleTime" SG_ 560 EVAP_TEMP_P1C 500;
BA_ "FlexKomSigStartValue" SG_ 560 EVAP_TEMP_P1C "00000000h";
BA_ "FlexKomSigStartPos" SG_ 560 EVAP_TEMP_P1C 39;
BA_ "FlexKomSigName" SG_ 560 EVAP_TEMP_P1C "HVAC_A2_PDU";
BA_ "FlexKomSigLaenge" SG_ 560 EVAP_TEMP_P1C 32;
BA_ "FlexKomSID" SG_ 560 EVAP_TEMP_P1C 2867;
BA_ "FlexKomIsMotorola" SG_ 560 EVAP_TEMP_P1C 1;
BA_ "FlexKomComment" SG_ 560 EVAP_TEMP_P1C "PDU for HVAC_A2";
BA_ "RID" SG_ 560 EvapTempTar "1247";
BA_ "GenSigSNA" SG_ 560 EvapTempTar "FFh";
BA_ "GenSigSendType" SG_ 560 EvapTempTar 5;
BA_ "GenSigCycleTime" SG_ 560 EvapTempTar 500;
BA_ "FlexKomSigStartValue" SG_ 560 EvapTempTar "00h";
BA_ "FlexKomSigStartPos" SG_ 560 EvapTempTar 23;
BA_ "FlexKomSigName" SG_ 560 EvapTempTar "EvapTempTar";
BA_ "FlexKomSigLaenge" SG_ 560 EvapTempTar 8;
BA_ "FlexKomSID" SG_ 560 EvapTempTar 30;
BA_ "FlexKomIsMotorola" SG_ 560 EvapTempTar 1;
BA_ "FlexKomComment" SG_ 560 EvapTempTar "Evaporator temperature target";
BA_ "RID" SG_ 560 PTC_Enbl "1098";
BA_ "GenSigStartValue" SG_ 560 PTC_Enbl 1;
BA_ "GenSigSNA" SG_ 560 PTC_Enbl "1h";
BA_ "GenSigSendType" SG_ 560 PTC_Enbl 5;
BA_ "GenSigCycleTime" SG_ 560 PTC_Enbl 500;
BA_ "FlexKomSigStartValue" SG_ 560 PTC_Enbl "01h";
BA_ "FlexKomSigStartPos" SG_ 560 PTC_Enbl 3;
BA_ "FlexKomSigName" SG_ 560 PTC_Enbl "PTC_Enbl";
BA_ "FlexKomSigLaenge" SG_ 560 PTC_Enbl 1;
BA_ "FlexKomSID" SG_ 560 PTC_Enbl 33;
BA_ "FlexKomIsMotorola" SG_ 560 PTC_Enbl 1;
BA_ "FlexKomComment" SG_ 560 PTC_Enbl "PTC heater enable; [1] = enable";
BA_ "RID" SG_ 560 SmrtAlt_HVAC_Disabled "3588";
BA_ "GenSigSNA" SG_ 560 SmrtAlt_HVAC_Disabled "3h";
BA_ "GenSigSendType" SG_ 560 SmrtAlt_HVAC_Disabled 5;
BA_ "GenSigCycleTime" SG_ 560 SmrtAlt_HVAC_Disabled 500;
BA_ "FlexKomSigStartValue" SG_ 560 SmrtAlt_HVAC_Disabled "00h";
BA_ "FlexKomSigStartPos" SG_ 560 SmrtAlt_HVAC_Disabled 28;
BA_ "FlexKomSigName" SG_ 560 SmrtAlt_HVAC_Disabled "SmrtAlt_HVAC_Disabled";
BA_ "FlexKomSigLaenge" SG_ 560 SmrtAlt_HVAC_Disabled 2;
BA_ "FlexKomSID" SG_ 560 SmrtAlt_HVAC_Disabled 2552;
BA_ "FlexKomIsMotorola" SG_ 560 SmrtAlt_HVAC_Disabled 1;
BA_ "FlexKomComment" SG_ 560 SmrtAlt_HVAC_Disabled "Disable the smart alternator";
BA_ "RID" SG_ 560 SpSt_DsblHVAC "1127";
BA_ "GenSigSNA" SG_ 560 SpSt_DsblHVAC "7h";
BA_ "GenSigSendType" SG_ 560 SpSt_DsblHVAC 5;
BA_ "GenSigCycleTime" SG_ 560 SpSt_DsblHVAC 500;
BA_ "FlexKomSigStartValue" SG_ 560 SpSt_DsblHVAC "00h";
BA_ "FlexKomSigStartPos" SG_ 560 SpSt_DsblHVAC 26;
BA_ "FlexKomSigName" SG_ 560 SpSt_DsblHVAC "SpSt_DsblHVAC";
BA_ "FlexKomSigLaenge" SG_ 560 SpSt_DsblHVAC 3;
BA_ "FlexKomSID" SG_ 560 SpSt_DsblHVAC 1555;
BA_ "FlexKomIsMotorola" SG_ 560 SpSt_DsblHVAC 1;
BA_ "FlexKomComment" SG_ 560 SpSt_DsblHVAC "Stop start disable from HVAC";
BA_ "RID" SG_ 818 A2D_DRV_TEMP_DR_POS "6333";
BA_ "GenSigStartValue" SG_ 818 A2D_DRV_TEMP_DR_POS 1023;
BA_ "GenSigSNA" SG_ 818 A2D_DRV_TEMP_DR_POS "3FFh";
BA_ "GenSigSendType" SG_ 818 A2D_DRV_TEMP_DR_POS 5;
BA_ "GenSigCycleTime" SG_ 818 A2D_DRV_TEMP_DR_POS 1000;
BA_ "FlexKomSigStartValue" SG_ 818 A2D_DRV_TEMP_DR_POS "03FFh";
BA_ "FlexKomSigStartPos" SG_ 818 A2D_DRV_TEMP_DR_POS 7;
BA_ "FlexKomSigName" SG_ 818 A2D_DRV_TEMP_DR_POS "A2D_DRV_TEMP_DR_POS";
BA_ "FlexKomSigLaenge" SG_ 818 A2D_DRV_TEMP_DR_POS 16;
BA_ "FlexKomSID" SG_ 818 A2D_DRV_TEMP_DR_POS 2695;
BA_ "FlexKomIsMotorola" SG_ 818 A2D_DRV_TEMP_DR_POS 1;
BA_ "FlexKomComment" SG_ 818 A2D_DRV_TEMP_DR_POS "Transmit raw A/D driver temp door position to ECM ";
BA_ "GenSigSNA" SG_ 818 Blower_Diagnostics "3FFh";
BA_ "GenSigSendType" SG_ 818 Blower_Diagnostics 5;
BA_ "GenSigCycleTime" SG_ 818 Blower_Diagnostics 1000;
BA_ "FlexKomSigStartValue" SG_ 818 Blower_Diagnostics "0000h";
BA_ "FlexKomSigStartPos" SG_ 818 Blower_Diagnostics 55;
BA_ "FlexKomSigName" SG_ 818 Blower_Diagnostics "Blower_Dutycycle";
BA_ "FlexKomSigLaenge" SG_ 818 Blower_Diagnostics 16;
BA_ "FlexKomSID" SG_ 818 Blower_Diagnostics 2802;
BA_ "FlexKomIsMotorola" SG_ 818 Blower_Diagnostics 1;
BA_ "FlexKomComment" SG_ 818 Blower_Diagnostics "Duty cycle Feedback received from the Blower";
BA_ "GenSigSNA" SG_ 818 Blower_Speed "1FFh";
BA_ "GenSigSendType" SG_ 818 Blower_Speed 5;
BA_ "GenSigCycleTime" SG_ 818 Blower_Speed 1000;
BA_ "FlexKomSigStartValue" SG_ 818 Blower_Speed "0000h";
BA_ "FlexKomSigStartPos" SG_ 818 Blower_Speed 39;
BA_ "FlexKomSigName" SG_ 818 Blower_Speed "Blower_Frequency";
BA_ "FlexKomSigLaenge" SG_ 818 Blower_Speed 16;
BA_ "FlexKomSID" SG_ 818 Blower_Speed 2801;
BA_ "FlexKomIsMotorola" SG_ 818 Blower_Speed 1;
BA_ "FlexKomComment" SG_ 818 Blower_Speed "Frequency Feedback received from the Blower";
BA_ "RID" SG_ 807 CabinConditioningSts "6715";
BA_ "GenSigSNA" SG_ 807 CabinConditioningSts "Fh";
BA_ "GenSigSendType" SG_ 807 CabinConditioningSts 5;
BA_ "GenSigCycleTime" SG_ 807 CabinConditioningSts 1000;
BA_ "FlexKomSigStartValue" SG_ 807 CabinConditioningSts "0000000000000000h";
BA_ "FlexKomSigStartPos" SG_ 807 CabinConditioningSts 7;
BA_ "FlexKomSigName" SG_ 807 CabinConditioningSts "HYBRID_HVAC";
BA_ "FlexKomSigLaenge" SG_ 807 CabinConditioningSts 64;
BA_ "FlexKomSID" SG_ 807 CabinConditioningSts 3111;
BA_ "FlexKomIsMotorola" SG_ 807 CabinConditioningSts 1;
BA_ "FlexKomComment" SG_ 807 CabinConditioningSts "HYBRID_HVAC";
BA_ "RID" SG_ 807 SchCond_Time_Till_Dep "6713";
BA_ "GenSigSNA" SG_ 807 SchCond_Time_Till_Dep "7Fh";
BA_ "GenSigSendType" SG_ 807 SchCond_Time_Till_Dep 5;
BA_ "GenSigCycleTime" SG_ 807 SchCond_Time_Till_Dep 1000;
BA_ "FlexKomSigStartValue" SG_ 807 SchCond_Time_Till_Dep "0000000000000000h";
BA_ "FlexKomSigStartPos" SG_ 807 SchCond_Time_Till_Dep 7;
BA_ "FlexKomSigName" SG_ 807 SchCond_Time_Till_Dep "HYBRID_HVAC";
BA_ "FlexKomSigLaenge" SG_ 807 SchCond_Time_Till_Dep 64;
BA_ "FlexKomSID" SG_ 807 SchCond_Time_Till_Dep 3111;
BA_ "FlexKomIsMotorola" SG_ 807 SchCond_Time_Till_Dep 1;
BA_ "FlexKomComment" SG_ 807 SchCond_Time_Till_Dep "HYBRID_HVAC";
BA_ "RID" SG_ 807 Sch_PreCondition_Sts "6709";
BA_ "GenSigSNA" SG_ 807 Sch_PreCondition_Sts "3h";
BA_ "GenSigSendType" SG_ 807 Sch_PreCondition_Sts 5;
BA_ "GenSigCycleTime" SG_ 807 Sch_PreCondition_Sts 1000;
BA_ "FlexKomSigStartValue" SG_ 807 Sch_PreCondition_Sts "0000000000000000h";
BA_ "FlexKomSigStartPos" SG_ 807 Sch_PreCondition_Sts 7;
BA_ "FlexKomSigName" SG_ 807 Sch_PreCondition_Sts "HYBRID_HVAC";
BA_ "FlexKomSigLaenge" SG_ 807 Sch_PreCondition_Sts 64;
BA_ "FlexKomSID" SG_ 807 Sch_PreCondition_Sts 3111;
BA_ "FlexKomIsMotorola" SG_ 807 Sch_PreCondition_Sts 1;
BA_ "FlexKomComment" SG_ 807 Sch_PreCondition_Sts "HYBRID_HVAC";
BA_ "GenSigSNA" SG_ 1184 HVBatModT_01 "0h";
BA_ "GenSigCycleTime" SG_ 1184 HVBatModT_01 1000;
BA_ "FlexKomSigStartValue" SG_ 1184 HVBatModT_01 "000000000000h";
BA_ "FlexKomSigStartPos" SG_ 1184 HVBatModT_01 7;
BA_ "FlexKomSigName" SG_ 1184 HVBatModT_01 "HybridRMS_BPCModTemp1_PKT";
BA_ "FlexKomSigLaenge" SG_ 1184 HVBatModT_01 48;
BA_ "FlexKomSID" SG_ 1184 HVBatModT_01 2882;
BA_ "FlexKomIsMotorola" SG_ 1184 HVBatModT_01 1;
BA_ "FlexKomComment" SG_ 1184 HVBatModT_01 ".";
BA_ "GenSigSNA" SG_ 1184 HVBatModT_02 "0h";
BA_ "GenSigCycleTime" SG_ 1184 HVBatModT_02 1000;
BA_ "FlexKomSigStartValue" SG_ 1184 HVBatModT_02 "000000000000h";
BA_ "FlexKomSigStartPos" SG_ 1184 HVBatModT_02 7;
BA_ "FlexKomSigName" SG_ 1184 HVBatModT_02 "HybridRMS_BPCModTemp1_PKT";
BA_ "FlexKomSigLaenge" SG_ 1184 HVBatModT_02 48;
BA_ "FlexKomSID" SG_ 1184 HVBatModT_02 2882;
BA_ "FlexKomIsMotorola" SG_ 1184 HVBatModT_02 1;
BA_ "FlexKomComment" SG_ 1184 HVBatModT_02 ".";
BA_ "GenSigSNA" SG_ 1184 HVBatModT_03 "0h";
BA_ "GenSigCycleTime" SG_ 1184 HVBatModT_03 1000;
BA_ "FlexKomSigStartValue" SG_ 1184 HVBatModT_03 "000000000000h";
BA_ "FlexKomSigStartPos" SG_ 1184 HVBatModT_03 7;
BA_ "FlexKomSigName" SG_ 1184 HVBatModT_03 "HybridRMS_BPCModTemp1_PKT";
BA_ "FlexKomSigLaenge" SG_ 1184 HVBatModT_03 48;
BA_ "FlexKomSID" SG_ 1184 HVBatModT_03 2882;
BA_ "FlexKomIsMotorola" SG_ 1184 HVBatModT_03 1;
BA_ "FlexKomComment" SG_ 1184 HVBatModT_03 ".";
BA_ "GenSigSNA" SG_ 1184 HVBatModT_04 "0h";
BA_ "GenSigCycleTime" SG_ 1184 HVBatModT_04 1000;
BA_ "FlexKomSigStartValue" SG_ 1184 HVBatModT_04 "000000000000h";
BA_ "FlexKomSigStartPos" SG_ 1184 HVBatModT_04 7;
BA_ "FlexKomSigName" SG_ 1184 HVBatModT_04 "HybridRMS_BPCModTemp1_PKT";
BA_ "FlexKomSigLaenge" SG_ 1184 HVBatModT_04 48;
BA_ "FlexKomSID" SG_ 1184 HVBatModT_04 2882;
BA_ "FlexKomIsMotorola" SG_ 1184 HVBatModT_04 1;
BA_ "FlexKomComment" SG_ 1184 HVBatModT_04 ".";
BA_ "GenSigSNA" SG_ 1184 HVBatModT_05 "0h";
BA_ "GenSigCycleTime" SG_ 1184 HVBatModT_05 1000;
BA_ "FlexKomSigStartValue" SG_ 1184 HVBatModT_05 "000000000000h";
BA_ "FlexKomSigStartPos" SG_ 1184 HVBatModT_05 7;
BA_ "FlexKomSigName" SG_ 1184 HVBatModT_05 "HybridRMS_BPCModTemp1_PKT";
BA_ "FlexKomSigLaenge" SG_ 1184 HVBatModT_05 48;
BA_ "FlexKomSID" SG_ 1184 HVBatModT_05 2882;
BA_ "FlexKomIsMotorola" SG_ 1184 HVBatModT_05 1;
BA_ "FlexKomComment" SG_ 1184 HVBatModT_05 ".";
BA_ "GenSigSNA" SG_ 1184 HVBatModT_06 "0h";
BA_ "GenSigCycleTime" SG_ 1184 HVBatModT_06 1000;
BA_ "FlexKomSigStartValue" SG_ 1184 HVBatModT_06 "000000000000h";
BA_ "FlexKomSigStartPos" SG_ 1184 HVBatModT_06 7;
BA_ "FlexKomSigName" SG_ 1184 HVBatModT_06 "HybridRMS_BPCModTemp1_PKT";
BA_ "FlexKomSigLaenge" SG_ 1184 HVBatModT_06 48;
BA_ "FlexKomSID" SG_ 1184 HVBatModT_06 2882;
BA_ "FlexKomIsMotorola" SG_ 1184 HVBatModT_06 1;
BA_ "FlexKomComment" SG_ 1184 HVBatModT_06 ".";
BA_ "GenSigSNA" SG_ 1185 HVBatModT_07 "0h";
BA_ "GenSigCycleTime" SG_ 1185 HVBatModT_07 1000;
BA_ "FlexKomSigStartValue" SG_ 1185 HVBatModT_07 "000000000000h";
BA_ "FlexKomSigStartPos" SG_ 1185 HVBatModT_07 7;
BA_ "FlexKomSigName" SG_ 1185 HVBatModT_07 "HybridRMS_BPCModTemp2_PKT";
BA_ "FlexKomSigLaenge" SG_ 1185 HVBatModT_07 48;
BA_ "FlexKomSID" SG_ 1185 HVBatModT_07 2881;
BA_ "FlexKomIsMotorola" SG_ 1185 HVBatModT_07 1;
BA_ "FlexKomComment" SG_ 1185 HVBatModT_07 ".";
BA_ "GenSigSNA" SG_ 1185 HVBatModT_08 "0h";
BA_ "GenSigCycleTime" SG_ 1185 HVBatModT_08 1000;
BA_ "FlexKomSigStartValue" SG_ 1185 HVBatModT_08 "000000000000h";
BA_ "FlexKomSigStartPos" SG_ 1185 HVBatModT_08 7;
BA_ "FlexKomSigName" SG_ 1185 HVBatModT_08 "HybridRMS_BPCModTemp2_PKT";
BA_ "FlexKomSigLaenge" SG_ 1185 HVBatModT_08 48;
BA_ "FlexKomSID" SG_ 1185 HVBatModT_08 2881;
BA_ "FlexKomIsMotorola" SG_ 1185 HVBatModT_08 1;
BA_ "FlexKomComment" SG_ 1185 HVBatModT_08 ".";
BA_ "GenSigSNA" SG_ 1185 HVBatModT_09 "0h";
BA_ "GenSigCycleTime" SG_ 1185 HVBatModT_09 1000;
BA_ "FlexKomSigStartValue" SG_ 1185 HVBatModT_09 "000000000000h";
BA_ "FlexKomSigStartPos" SG_ 1185 HVBatModT_09 7;
BA_ "FlexKomSigName" SG_ 1185 HVBatModT_09 "HybridRMS_BPCModTemp2_PKT";
BA_ "FlexKomSigLaenge" SG_ 1185 HVBatModT_09 48;
BA_ "FlexKomSID" SG_ 1185 HVBatModT_09 2881;
BA_ "FlexKomIsMotorola" SG_ 1185 HVBatModT_09 1;
BA_ "FlexKomComment" SG_ 1185 HVBatModT_09 ".";
BA_ "GenSigSNA" SG_ 1185 HVBatModT_10 "0h";
BA_ "GenSigCycleTime" SG_ 1185 HVBatModT_10 1000;
BA_ "FlexKomSigStartValue" SG_ 1185 HVBatModT_10 "000000000000h";
BA_ "FlexKomSigStartPos" SG_ 1185 HVBatModT_10 7;
BA_ "FlexKomSigName" SG_ 1185 HVBatModT_10 "HybridRMS_BPCModTemp2_PKT";
BA_ "FlexKomSigLaenge" SG_ 1185 HVBatModT_10 48;
BA_ "FlexKomSID" SG_ 1185 HVBatModT_10 2881;
BA_ "FlexKomIsMotorola" SG_ 1185 HVBatModT_10 1;
BA_ "FlexKomComment" SG_ 1185 HVBatModT_10 ".";
BA_ "GenSigSNA" SG_ 1185 HVBatModT_11 "0h";
BA_ "GenSigCycleTime" SG_ 1185 HVBatModT_11 1000;
BA_ "FlexKomSigStartValue" SG_ 1185 HVBatModT_11 "000000000000h";
BA_ "FlexKomSigStartPos" SG_ 1185 HVBatModT_11 7;
BA_ "FlexKomSigName" SG_ 1185 HVBatModT_11 "HybridRMS_BPCModTemp2_PKT";
BA_ "FlexKomSigLaenge" SG_ 1185 HVBatModT_11 48;
BA_ "FlexKomSID" SG_ 1185 HVBatModT_11 2881;
BA_ "FlexKomIsMotorola" SG_ 1185 HVBatModT_11 1;
BA_ "FlexKomComment" SG_ 1185 HVBatModT_11 ".";
BA_ "GenSigSNA" SG_ 1185 HVBatModT_12 "0h";
BA_ "GenSigCycleTime" SG_ 1185 HVBatModT_12 1000;
BA_ "FlexKomSigStartValue" SG_ 1185 HVBatModT_12 "000000000000h";
BA_ "FlexKomSigStartPos" SG_ 1185 HVBatModT_12 7;
BA_ "FlexKomSigName" SG_ 1185 HVBatModT_12 "HybridRMS_BPCModTemp2_PKT";
BA_ "FlexKomSigLaenge" SG_ 1185 HVBatModT_12 48;
BA_ "FlexKomSID" SG_ 1185 HVBatModT_12 2881;
BA_ "FlexKomIsMotorola" SG_ 1185 HVBatModT_12 1;
BA_ "FlexKomComment" SG_ 1185 HVBatModT_12 ".";
BA_ "GenSigSNA" SG_ 1186 HVBatModT_13 "FFh";
BA_ "GenSigCycleTime" SG_ 1186 HVBatModT_13 1000;
BA_ "FlexKomSigStartValue" SG_ 1186 HVBatModT_13 "00000000h";
BA_ "FlexKomSigStartPos" SG_ 1186 HVBatModT_13 39;
BA_ "FlexKomSigName" SG_ 1186 HVBatModT_13 "HVBatModT_PKT";
BA_ "FlexKomSigLaenge" SG_ 1186 HVBatModT_13 32;
BA_ "FlexKomSID" SG_ 1186 HVBatModT_13 3014;
BA_ "FlexKomIsMotorola" SG_ 1186 HVBatModT_13 1;
BA_ "FlexKomComment" SG_ 1186 HVBatModT_13 ".";
BA_ "GenSigSNA" SG_ 1186 HVBatModT_14 "FFh";
BA_ "GenSigCycleTime" SG_ 1186 HVBatModT_14 1000;
BA_ "FlexKomSigStartValue" SG_ 1186 HVBatModT_14 "00000000h";
BA_ "FlexKomSigStartPos" SG_ 1186 HVBatModT_14 39;
BA_ "FlexKomSigName" SG_ 1186 HVBatModT_14 "HVBatModT_PKT";
BA_ "FlexKomSigLaenge" SG_ 1186 HVBatModT_14 32;
BA_ "FlexKomSID" SG_ 1186 HVBatModT_14 3014;
BA_ "FlexKomIsMotorola" SG_ 1186 HVBatModT_14 1;
BA_ "FlexKomComment" SG_ 1186 HVBatModT_14 ".";
BA_ "GenSigSNA" SG_ 1186 HVBatModT_15 "FFh";
BA_ "GenSigCycleTime" SG_ 1186 HVBatModT_15 1000;
BA_ "FlexKomSigStartValue" SG_ 1186 HVBatModT_15 "00000000h";
BA_ "FlexKomSigStartPos" SG_ 1186 HVBatModT_15 39;
BA_ "FlexKomSigName" SG_ 1186 HVBatModT_15 "HVBatModT_PKT";
BA_ "FlexKomSigLaenge" SG_ 1186 HVBatModT_15 32;
BA_ "FlexKomSID" SG_ 1186 HVBatModT_15 3014;
BA_ "FlexKomIsMotorola" SG_ 1186 HVBatModT_15 1;
BA_ "FlexKomComment" SG_ 1186 HVBatModT_15 ".";
BA_ "GenSigSNA" SG_ 1186 HVBatModT_16 "FFh";
BA_ "GenSigCycleTime" SG_ 1186 HVBatModT_16 1000;
BA_ "FlexKomSigStartValue" SG_ 1186 HVBatModT_16 "00000000h";
BA_ "FlexKomSigStartPos" SG_ 1186 HVBatModT_16 39;
BA_ "FlexKomSigName" SG_ 1186 HVBatModT_16 "HVBatModT_PKT";
BA_ "FlexKomSigLaenge" SG_ 1186 HVBatModT_16 32;
BA_ "FlexKomSID" SG_ 1186 HVBatModT_16 3014;
BA_ "FlexKomIsMotorola" SG_ 1186 HVBatModT_16 1;
BA_ "FlexKomComment" SG_ 1186 HVBatModT_16 ".";
BA_ "GenSigSNA" SG_ 1186 HVBatModTempMax "FFh";
BA_ "GenSigCycleTime" SG_ 1186 HVBatModTempMax 1000;
BA_ "FlexKomSigStartValue" SG_ 1186 HVBatModTempMax "00000000h";
BA_ "FlexKomSigStartPos" SG_ 1186 HVBatModTempMax 7;
BA_ "FlexKomSigName" SG_ 1186 HVBatModTempMax "HybridRMS_BPCModTemp3_PKT";
BA_ "FlexKomSigLaenge" SG_ 1186 HVBatModTempMax 32;
BA_ "FlexKomSID" SG_ 1186 HVBatModTempMax 2912;
BA_ "FlexKomIsMotorola" SG_ 1186 HVBatModTempMax 1;
BA_ "FlexKomComment" SG_ 1186 HVBatModTempMax ".";
BA_ "GenSigSNA" SG_ 1186 HVBatModTempMin "FFh";
BA_ "GenSigCycleTime" SG_ 1186 HVBatModTempMin 1000;
BA_ "FlexKomSigStartValue" SG_ 1186 HVBatModTempMin "00000000h";
BA_ "FlexKomSigStartPos" SG_ 1186 HVBatModTempMin 7;
BA_ "FlexKomSigName" SG_ 1186 HVBatModTempMin "HybridRMS_BPCModTemp3_PKT";
BA_ "FlexKomSigLaenge" SG_ 1186 HVBatModTempMin 32;
BA_ "FlexKomSID" SG_ 1186 HVBatModTempMin 2912;
BA_ "FlexKomIsMotorola" SG_ 1186 HVBatModTempMin 1;
BA_ "FlexKomComment" SG_ 1186 HVBatModTempMin ".";
BA_ "GenSigSNA" SG_ 1186 HVBatMod_NumMaxTmp "0h";
BA_ "GenSigCycleTime" SG_ 1186 HVBatMod_NumMaxTmp 1000;
BA_ "FlexKomSigStartValue" SG_ 1186 HVBatMod_NumMaxTmp "00000000h";
BA_ "FlexKomSigStartPos" SG_ 1186 HVBatMod_NumMaxTmp 7;
BA_ "FlexKomSigName" SG_ 1186 HVBatMod_NumMaxTmp "HybridRMS_BPCModTemp3_PKT";
BA_ "FlexKomSigLaenge" SG_ 1186 HVBatMod_NumMaxTmp 32;
BA_ "FlexKomSID" SG_ 1186 HVBatMod_NumMaxTmp 2912;
BA_ "FlexKomIsMotorola" SG_ 1186 HVBatMod_NumMaxTmp 1;
BA_ "FlexKomComment" SG_ 1186 HVBatMod_NumMaxTmp ".";
BA_ "GenSigSNA" SG_ 1186 HVBatMod_NumMinTmp "0h";
BA_ "GenSigCycleTime" SG_ 1186 HVBatMod_NumMinTmp 1000;
BA_ "FlexKomSigStartValue" SG_ 1186 HVBatMod_NumMinTmp "00000000h";
BA_ "FlexKomSigStartPos" SG_ 1186 HVBatMod_NumMinTmp 7;
BA_ "FlexKomSigName" SG_ 1186 HVBatMod_NumMinTmp "HybridRMS_BPCModTemp3_PKT";
BA_ "FlexKomSigLaenge" SG_ 1186 HVBatMod_NumMinTmp 32;
BA_ "FlexKomSID" SG_ 1186 HVBatMod_NumMinTmp 2912;
BA_ "FlexKomIsMotorola" SG_ 1186 HVBatMod_NumMinTmp 1;
BA_ "FlexKomComment" SG_ 1186 HVBatMod_NumMinTmp ".";
BA_ "GenSigSNA" SG_ 1194 HVBatSerial_Data "0h";
BA_ "GenSigCycleTime" SG_ 1194 HVBatSerial_Data 250;
BA_ "FlexKomSigStartValue" SG_ 1194 HVBatSerial_Data "0F00000000000000h";
BA_ "FlexKomSigStartPos" SG_ 1194 HVBatSerial_Data 7;
BA_ "FlexKomSigName" SG_ 1194 HVBatSerial_Data "HybridRMS_BatteryID";
BA_ "FlexKomSigLaenge" SG_ 1194 HVBatSerial_Data 64;
BA_ "FlexKomSID" SG_ 1194 HVBatSerial_Data 3060;
BA_ "FlexKomIsMotorola" SG_ 1194 HVBatSerial_Data 1;
BA_ "FlexKomComment" SG_ 1194 HVBatSerial_Data "HybridRMS_BatteryID";
BA_ "GenSigSNA" SG_ 1194 HVBatSerial_Length "FFh";
BA_ "GenSigCycleTime" SG_ 1194 HVBatSerial_Length 250;
BA_ "FlexKomSigStartValue" SG_ 1194 HVBatSerial_Length "0F00000000000000h";
BA_ "FlexKomSigStartPos" SG_ 1194 HVBatSerial_Length 7;
BA_ "FlexKomSigName" SG_ 1194 HVBatSerial_Length "HybridRMS_BatteryID";
BA_ "FlexKomSigLaenge" SG_ 1194 HVBatSerial_Length 64;
BA_ "FlexKomSID" SG_ 1194 HVBatSerial_Length 3060;
BA_ "FlexKomIsMotorola" SG_ 1194 HVBatSerial_Length 1;
BA_ "FlexKomComment" SG_ 1194 HVBatSerial_Length "HybridRMS_BatteryID";
BA_ "GenSigStartValue" SG_ 1194 HVBatSerial_Msg 15;
BA_ "GenSigSNA" SG_ 1194 HVBatSerial_Msg "Fh";
BA_ "GenSigCycleTime" SG_ 1194 HVBatSerial_Msg 250;
BA_ "FlexKomSigStartValue" SG_ 1194 HVBatSerial_Msg "0F00000000000000h";
BA_ "FlexKomSigStartPos" SG_ 1194 HVBatSerial_Msg 7;
BA_ "FlexKomSigName" SG_ 1194 HVBatSerial_Msg "HybridRMS_BatteryID";
BA_ "FlexKomSigLaenge" SG_ 1194 HVBatSerial_Msg 64;
BA_ "FlexKomSID" SG_ 1194 HVBatSerial_Msg 3060;
BA_ "FlexKomIsMotorola" SG_ 1194 HVBatSerial_Msg 1;
BA_ "FlexKomComment" SG_ 1194 HVBatSerial_Msg "HybridRMS_BatteryID";
BA_ "GenSigSNA" SG_ 1157 HVBatCrnt "0h";
BA_ "GenSigCycleTime" SG_ 1157 HVBatCrnt 1000;
BA_ "FlexKomSigStartValue" SG_ 1157 HVBatCrnt "000000007F7F0000h";
BA_ "FlexKomSigStartPos" SG_ 1157 HVBatCrnt 7;
BA_ "FlexKomSigName" SG_ 1157 HVBatCrnt "HybridRMS_BatteryStatus_PKT";
BA_ "FlexKomSigLaenge" SG_ 1157 HVBatCrnt 64;
BA_ "FlexKomSID" SG_ 1157 HVBatCrnt 2887;
BA_ "FlexKomIsMotorola" SG_ 1157 HVBatCrnt 1;
BA_ "FlexKomComment" SG_ 1157 HVBatCrnt ".";
BA_ "GenSigSNA" SG_ 1157 HVBatIsolStat "0h";
BA_ "GenSigCycleTime" SG_ 1157 HVBatIsolStat 1000;
BA_ "FlexKomSigStartValue" SG_ 1157 HVBatIsolStat "000000007F7F0000h";
BA_ "FlexKomSigStartPos" SG_ 1157 HVBatIsolStat 7;
BA_ "FlexKomSigName" SG_ 1157 HVBatIsolStat "HybridRMS_BatteryStatus_PKT";
BA_ "FlexKomSigLaenge" SG_ 1157 HVBatIsolStat 64;
BA_ "FlexKomSID" SG_ 1157 HVBatIsolStat 2887;
BA_ "FlexKomIsMotorola" SG_ 1157 HVBatIsolStat 1;
BA_ "FlexKomComment" SG_ 1157 HVBatIsolStat ".";
BA_ "GenSigStartValue" SG_ 1157 HVBatPk_CellNumMaxVlt 127;
BA_ "GenSigSNA" SG_ 1157 HVBatPk_CellNumMaxVlt "7Fh";
BA_ "GenSigCycleTime" SG_ 1157 HVBatPk_CellNumMaxVlt 1000;
BA_ "FlexKomSigStartValue" SG_ 1157 HVBatPk_CellNumMaxVlt "000000007F7F0000h";
BA_ "FlexKomSigStartPos" SG_ 1157 HVBatPk_CellNumMaxVlt 7;
BA_ "FlexKomSigName" SG_ 1157 HVBatPk_CellNumMaxVlt "HybridRMS_BatteryStatus_PKT";
BA_ "FlexKomSigLaenge" SG_ 1157 HVBatPk_CellNumMaxVlt 64;
BA_ "FlexKomSID" SG_ 1157 HVBatPk_CellNumMaxVlt 2887;
BA_ "FlexKomIsMotorola" SG_ 1157 HVBatPk_CellNumMaxVlt 1;
BA_ "FlexKomComment" SG_ 1157 HVBatPk_CellNumMaxVlt ".";
BA_ "GenSigStartValue" SG_ 1157 HVBatPk_CellNumMinVlt 127;
BA_ "GenSigSNA" SG_ 1157 HVBatPk_CellNumMinVlt "7Fh";
BA_ "GenSigCycleTime" SG_ 1157 HVBatPk_CellNumMinVlt 1000;
BA_ "FlexKomSigStartValue" SG_ 1157 HVBatPk_CellNumMinVlt "000000007F7F0000h";
BA_ "FlexKomSigStartPos" SG_ 1157 HVBatPk_CellNumMinVlt 7;
BA_ "FlexKomSigName" SG_ 1157 HVBatPk_CellNumMinVlt "HybridRMS_BatteryStatus_PKT";
BA_ "FlexKomSigLaenge" SG_ 1157 HVBatPk_CellNumMinVlt 64;
BA_ "FlexKomSID" SG_ 1157 HVBatPk_CellNumMinVlt 2887;
BA_ "FlexKomIsMotorola" SG_ 1157 HVBatPk_CellNumMinVlt 1;
BA_ "FlexKomComment" SG_ 1157 HVBatPk_CellNumMinVlt ".";
BA_ "GenSigSNA" SG_ 1157 HVBatVlt "FFFh";
BA_ "GenSigCycleTime" SG_ 1157 HVBatVlt 1000;
BA_ "FlexKomSigStartValue" SG_ 1157 HVBatVlt "000000007F7F0000h";
BA_ "FlexKomSigStartPos" SG_ 1157 HVBatVlt 7;
BA_ "FlexKomSigName" SG_ 1157 HVBatVlt "HybridRMS_BatteryStatus_PKT";
BA_ "FlexKomSigLaenge" SG_ 1157 HVBatVlt 64;
BA_ "FlexKomSID" SG_ 1157 HVBatVlt 2887;
BA_ "FlexKomIsMotorola" SG_ 1157 HVBatVlt 1;
BA_ "FlexKomComment" SG_ 1157 HVBatVlt ".";
BA_ "GenSigSNA" SG_ 1157 PwrtrnHV_IsolStat "0h";
BA_ "GenSigCycleTime" SG_ 1157 PwrtrnHV_IsolStat 1000;
BA_ "FlexKomSigStartValue" SG_ 1157 PwrtrnHV_IsolStat "000000007F7F0000h";
BA_ "FlexKomSigStartPos" SG_ 1157 PwrtrnHV_IsolStat 7;
BA_ "FlexKomSigName" SG_ 1157 PwrtrnHV_IsolStat "HybridRMS_BatteryStatus_PKT";
BA_ "FlexKomSigLaenge" SG_ 1157 PwrtrnHV_IsolStat 64;
BA_ "FlexKomSID" SG_ 1157 PwrtrnHV_IsolStat 2887;
BA_ "FlexKomIsMotorola" SG_ 1157 PwrtrnHV_IsolStat 1;
BA_ "FlexKomComment" SG_ 1157 PwrtrnHV_IsolStat ".";
BA_ "GenSigSNA" SG_ 1159 HVBatCellVlt_01 "1FFFh";
BA_ "GenSigCycleTime" SG_ 1159 HVBatCellVlt_01 1000;
BA_ "FlexKomSigStartValue" SG_ 1159 HVBatCellVlt_01 "0000000000000000h";
BA_ "FlexKomSigStartPos" SG_ 1159 HVBatCellVlt_01 7;
BA_ "FlexKomSigName" SG_ 1159 HVBatCellVlt_01 "HybridRMS_CellVoltage01";
BA_ "FlexKomSigLaenge" SG_ 1159 HVBatCellVlt_01 64;
BA_ "FlexKomSID" SG_ 1159 HVBatCellVlt_01 2911;
BA_ "FlexKomIsMotorola" SG_ 1159 HVBatCellVlt_01 1;
BA_ "FlexKomComment" SG_ 1159 HVBatCellVlt_01 ".";
BA_ "GenSigSNA" SG_ 1159 HVBatCellVlt_02 "1FFFh";
BA_ "GenSigCycleTime" SG_ 1159 HVBatCellVlt_02 1000;
BA_ "FlexKomSigStartValue" SG_ 1159 HVBatCellVlt_02 "0000000000000000h";
BA_ "FlexKomSigStartPos" SG_ 1159 HVBatCellVlt_02 7;
BA_ "FlexKomSigName" SG_ 1159 HVBatCellVlt_02 "HybridRMS_CellVoltage01";
BA_ "FlexKomSigLaenge" SG_ 1159 HVBatCellVlt_02 64;
BA_ "FlexKomSID" SG_ 1159 HVBatCellVlt_02 2911;
BA_ "FlexKomIsMotorola" SG_ 1159 HVBatCellVlt_02 1;
BA_ "FlexKomComment" SG_ 1159 HVBatCellVlt_02 ".";
BA_ "GenSigSNA" SG_ 1159 HVBatCellVlt_03 "1FFFh";
BA_ "GenSigCycleTime" SG_ 1159 HVBatCellVlt_03 1000;
BA_ "FlexKomSigStartValue" SG_ 1159 HVBatCellVlt_03 "0000000000000000h";
BA_ "FlexKomSigStartPos" SG_ 1159 HVBatCellVlt_03 7;
BA_ "FlexKomSigName" SG_ 1159 HVBatCellVlt_03 "HybridRMS_CellVoltage01";
BA_ "FlexKomSigLaenge" SG_ 1159 HVBatCellVlt_03 64;
BA_ "FlexKomSID" SG_ 1159 HVBatCellVlt_03 2911;
BA_ "FlexKomIsMotorola" SG_ 1159 HVBatCellVlt_03 1;
BA_ "FlexKomComment" SG_ 1159 HVBatCellVlt_03 ".";
BA_ "GenSigSNA" SG_ 1159 HVBatCellVlt_04 "1FFFh";
BA_ "GenSigCycleTime" SG_ 1159 HVBatCellVlt_04 1000;
BA_ "FlexKomSigStartValue" SG_ 1159 HVBatCellVlt_04 "0000000000000000h";
BA_ "FlexKomSigStartPos" SG_ 1159 HVBatCellVlt_04 7;
BA_ "FlexKomSigName" SG_ 1159 HVBatCellVlt_04 "HybridRMS_CellVoltage01";
BA_ "FlexKomSigLaenge" SG_ 1159 HVBatCellVlt_04 64;
BA_ "FlexKomSID" SG_ 1159 HVBatCellVlt_04 2911;
BA_ "FlexKomIsMotorola" SG_ 1159 HVBatCellVlt_04 1;
BA_ "FlexKomComment" SG_ 1159 HVBatCellVlt_04 ".";
BA_ "GenSigSNA" SG_ 1160 HVBatCellVlt_05 "1FFFh";
BA_ "GenSigCycleTime" SG_ 1160 HVBatCellVlt_05 1000;
BA_ "FlexKomSigStartValue" SG_ 1160 HVBatCellVlt_05 "0000000000000000h";
BA_ "FlexKomSigStartPos" SG_ 1160 HVBatCellVlt_05 7;
BA_ "FlexKomSigName" SG_ 1160 HVBatCellVlt_05 "HybridRMS_CellVoltage02";
BA_ "FlexKomSigLaenge" SG_ 1160 HVBatCellVlt_05 64;
BA_ "FlexKomSID" SG_ 1160 HVBatCellVlt_05 2910;
BA_ "FlexKomIsMotorola" SG_ 1160 HVBatCellVlt_05 1;
BA_ "FlexKomComment" SG_ 1160 HVBatCellVlt_05 ".";
BA_ "GenSigSNA" SG_ 1160 HVBatCellVlt_06 "1FFFh";
BA_ "GenSigCycleTime" SG_ 1160 HVBatCellVlt_06 1000;
BA_ "FlexKomSigStartValue" SG_ 1160 HVBatCellVlt_06 "0000000000000000h";
BA_ "FlexKomSigStartPos" SG_ 1160 HVBatCellVlt_06 7;
BA_ "FlexKomSigName" SG_ 1160 HVBatCellVlt_06 "HybridRMS_CellVoltage02";
BA_ "FlexKomSigLaenge" SG_ 1160 HVBatCellVlt_06 64;
BA_ "FlexKomSID" SG_ 1160 HVBatCellVlt_06 2910;
BA_ "FlexKomIsMotorola" SG_ 1160 HVBatCellVlt_06 1;
BA_ "FlexKomComment" SG_ 1160 HVBatCellVlt_06 ".";
BA_ "GenSigSNA" SG_ 1160 HVBatCellVlt_07 "1FFFh";
BA_ "GenSigCycleTime" SG_ 1160 HVBatCellVlt_07 1000;
BA_ "FlexKomSigStartValue" SG_ 1160 HVBatCellVlt_07 "0000000000000000h";
BA_ "FlexKomSigStartPos" SG_ 1160 HVBatCellVlt_07 7;
BA_ "FlexKomSigName" SG_ 1160 HVBatCellVlt_07 "HybridRMS_CellVoltage02";
BA_ "FlexKomSigLaenge" SG_ 1160 HVBatCellVlt_07 64;
BA_ "FlexKomSID" SG_ 1160 HVBatCellVlt_07 2910;
BA_ "FlexKomIsMotorola" SG_ 1160 HVBatCellVlt_07 1;
BA_ "FlexKomComment" SG_ 1160 HVBatCellVlt_07 ".";
BA_ "GenSigSNA" SG_ 1160 HVBatCellVlt_08 "1FFFh";
BA_ "GenSigCycleTime" SG_ 1160 HVBatCellVlt_08 1000;
BA_ "FlexKomSigStartValue" SG_ 1160 HVBatCellVlt_08 "0000000000000000h";
BA_ "FlexKomSigStartPos" SG_ 1160 HVBatCellVlt_08 7;
BA_ "FlexKomSigName" SG_ 1160 HVBatCellVlt_08 "HybridRMS_CellVoltage02";
BA_ "FlexKomSigLaenge" SG_ 1160 HVBatCellVlt_08 64;
BA_ "FlexKomSID" SG_ 1160 HVBatCellVlt_08 2910;
BA_ "FlexKomIsMotorola" SG_ 1160 HVBatCellVlt_08 1;
BA_ "FlexKomComment" SG_ 1160 HVBatCellVlt_08 ".";
BA_ "GenSigSNA" SG_ 1161 HVBatCellVlt_09 "1FFFh";
BA_ "GenSigCycleTime" SG_ 1161 HVBatCellVlt_09 1000;
BA_ "FlexKomSigStartValue" SG_ 1161 HVBatCellVlt_09 "0000000000000000h";
BA_ "FlexKomSigStartPos" SG_ 1161 HVBatCellVlt_09 7;
BA_ "FlexKomSigName" SG_ 1161 HVBatCellVlt_09 "HybridRMS_CellVoltage03";
BA_ "FlexKomSigLaenge" SG_ 1161 HVBatCellVlt_09 64;
BA_ "FlexKomSID" SG_ 1161 HVBatCellVlt_09 2909;
BA_ "FlexKomIsMotorola" SG_ 1161 HVBatCellVlt_09 1;
BA_ "FlexKomComment" SG_ 1161 HVBatCellVlt_09 ".";
BA_ "GenSigSNA" SG_ 1161 HVBatCellVlt_10 "1FFFh";
BA_ "GenSigCycleTime" SG_ 1161 HVBatCellVlt_10 1000;
BA_ "FlexKomSigStartValue" SG_ 1161 HVBatCellVlt_10 "0000000000000000h";
BA_ "FlexKomSigStartPos" SG_ 1161 HVBatCellVlt_10 7;
BA_ "FlexKomSigName" SG_ 1161 HVBatCellVlt_10 "HybridRMS_CellVoltage03";
BA_ "FlexKomSigLaenge" SG_ 1161 HVBatCellVlt_10 64;
BA_ "FlexKomSID" SG_ 1161 HVBatCellVlt_10 2909;
BA_ "FlexKomIsMotorola" SG_ 1161 HVBatCellVlt_10 1;
BA_ "FlexKomComment" SG_ 1161 HVBatCellVlt_10 ".";
BA_ "GenSigSNA" SG_ 1161 HVBatCellVlt_11 "1FFFh";
BA_ "GenSigCycleTime" SG_ 1161 HVBatCellVlt_11 1000;
BA_ "FlexKomSigStartValue" SG_ 1161 HVBatCellVlt_11 "0000000000000000h";
BA_ "FlexKomSigStartPos" SG_ 1161 HVBatCellVlt_11 7;
BA_ "FlexKomSigName" SG_ 1161 HVBatCellVlt_11 "HybridRMS_CellVoltage03";
BA_ "FlexKomSigLaenge" SG_ 1161 HVBatCellVlt_11 64;
BA_ "FlexKomSID" SG_ 1161 HVBatCellVlt_11 2909;
BA_ "FlexKomIsMotorola" SG_ 1161 HVBatCellVlt_11 1;
BA_ "FlexKomComment" SG_ 1161 HVBatCellVlt_11 ".";
BA_ "GenSigSNA" SG_ 1161 HVBatCellVlt_12 "1FFFh";
BA_ "GenSigCycleTime" SG_ 1161 HVBatCellVlt_12 1000;
BA_ "FlexKomSigStartValue" SG_ 1161 HVBatCellVlt_12 "0000000000000000h";
BA_ "FlexKomSigStartPos" SG_ 1161 HVBatCellVlt_12 7;
BA_ "FlexKomSigName" SG_ 1161 HVBatCellVlt_12 "HybridRMS_CellVoltage03";
BA_ "FlexKomSigLaenge" SG_ 1161 HVBatCellVlt_12 64;
BA_ "FlexKomSID" SG_ 1161 HVBatCellVlt_12 2909;
BA_ "FlexKomIsMotorola" SG_ 1161 HVBatCellVlt_12 1;
BA_ "FlexKomComment" SG_ 1161 HVBatCellVlt_12 ".";
BA_ "GenSigSNA" SG_ 1162 HVBatCellVlt_13 "1FFFh";
BA_ "GenSigCycleTime" SG_ 1162 HVBatCellVlt_13 1000;
BA_ "FlexKomSigStartValue" SG_ 1162 HVBatCellVlt_13 "0000000000000000h";
BA_ "FlexKomSigStartPos" SG_ 1162 HVBatCellVlt_13 7;
BA_ "FlexKomSigName" SG_ 1162 HVBatCellVlt_13 "HybridRMS_CellVoltage04";
BA_ "FlexKomSigLaenge" SG_ 1162 HVBatCellVlt_13 64;
BA_ "FlexKomSID" SG_ 1162 HVBatCellVlt_13 2908;
BA_ "FlexKomIsMotorola" SG_ 1162 HVBatCellVlt_13 1;
BA_ "FlexKomComment" SG_ 1162 HVBatCellVlt_13 ".";
BA_ "GenSigSNA" SG_ 1162 HVBatCellVlt_14 "1FFFh";
BA_ "GenSigCycleTime" SG_ 1162 HVBatCellVlt_14 1000;
BA_ "FlexKomSigStartValue" SG_ 1162 HVBatCellVlt_14 "0000000000000000h";
BA_ "FlexKomSigStartPos" SG_ 1162 HVBatCellVlt_14 7;
BA_ "FlexKomSigName" SG_ 1162 HVBatCellVlt_14 "HybridRMS_CellVoltage04";
BA_ "FlexKomSigLaenge" SG_ 1162 HVBatCellVlt_14 64;
BA_ "FlexKomSID" SG_ 1162 HVBatCellVlt_14 2908;
BA_ "FlexKomIsMotorola" SG_ 1162 HVBatCellVlt_14 1;
BA_ "FlexKomComment" SG_ 1162 HVBatCellVlt_14 ".";
BA_ "GenSigSNA" SG_ 1162 HVBatCellVlt_15 "1FFFh";
BA_ "GenSigCycleTime" SG_ 1162 HVBatCellVlt_15 1000;
BA_ "FlexKomSigStartValue" SG_ 1162 HVBatCellVlt_15 "0000000000000000h";
BA_ "FlexKomSigStartPos" SG_ 1162 HVBatCellVlt_15 7;
BA_ "FlexKomSigName" SG_ 1162 HVBatCellVlt_15 "HybridRMS_CellVoltage04";
BA_ "FlexKomSigLaenge" SG_ 1162 HVBatCellVlt_15 64;
BA_ "FlexKomSID" SG_ 1162 HVBatCellVlt_15 2908;
BA_ "FlexKomIsMotorola" SG_ 1162 HVBatCellVlt_15 1;
BA_ "FlexKomComment" SG_ 1162 HVBatCellVlt_15 ".";
BA_ "GenSigSNA" SG_ 1162 HVBatCellVlt_16 "1FFFh";
BA_ "GenSigCycleTime" SG_ 1162 HVBatCellVlt_16 1000;
BA_ "FlexKomSigStartValue" SG_ 1162 HVBatCellVlt_16 "0000000000000000h";
BA_ "FlexKomSigStartPos" SG_ 1162 HVBatCellVlt_16 7;
BA_ "FlexKomSigName" SG_ 1162 HVBatCellVlt_16 "HybridRMS_CellVoltage04";
BA_ "FlexKomSigLaenge" SG_ 1162 HVBatCellVlt_16 64;
BA_ "FlexKomSID" SG_ 1162 HVBatCellVlt_16 2908;
BA_ "FlexKomIsMotorola" SG_ 1162 HVBatCellVlt_16 1;
BA_ "FlexKomComment" SG_ 1162 HVBatCellVlt_16 ".";
BA_ "GenSigSNA" SG_ 1163 HVBatCellVlt_17 "1FFFh";
BA_ "GenSigCycleTime" SG_ 1163 HVBatCellVlt_17 1000;
BA_ "FlexKomSigStartValue" SG_ 1163 HVBatCellVlt_17 "0000000000000000h";
BA_ "FlexKomSigStartPos" SG_ 1163 HVBatCellVlt_17 7;
BA_ "FlexKomSigName" SG_ 1163 HVBatCellVlt_17 "HybridRMS_CellVoltage05";
BA_ "FlexKomSigLaenge" SG_ 1163 HVBatCellVlt_17 64;
BA_ "FlexKomSID" SG_ 1163 HVBatCellVlt_17 2907;
BA_ "FlexKomIsMotorola" SG_ 1163 HVBatCellVlt_17 1;
BA_ "FlexKomComment" SG_ 1163 HVBatCellVlt_17 ".";
BA_ "GenSigSNA" SG_ 1163 HVBatCellVlt_18 "1FFFh";
BA_ "GenSigCycleTime" SG_ 1163 HVBatCellVlt_18 1000;
BA_ "FlexKomSigStartValue" SG_ 1163 HVBatCellVlt_18 "0000000000000000h";
BA_ "FlexKomSigStartPos" SG_ 1163 HVBatCellVlt_18 7;
BA_ "FlexKomSigName" SG_ 1163 HVBatCellVlt_18 "HybridRMS_CellVoltage05";
BA_ "FlexKomSigLaenge" SG_ 1163 HVBatCellVlt_18 64;
BA_ "FlexKomSID" SG_ 1163 HVBatCellVlt_18 2907;
BA_ "FlexKomIsMotorola" SG_ 1163 HVBatCellVlt_18 1;
BA_ "FlexKomComment" SG_ 1163 HVBatCellVlt_18 ".";
BA_ "GenSigSNA" SG_ 1163 HVBatCellVlt_19 "1FFFh";
BA_ "GenSigCycleTime" SG_ 1163 HVBatCellVlt_19 1000;
BA_ "FlexKomSigStartValue" SG_ 1163 HVBatCellVlt_19 "0000000000000000h";
BA_ "FlexKomSigStartPos" SG_ 1163 HVBatCellVlt_19 7;
BA_ "FlexKomSigName" SG_ 1163 HVBatCellVlt_19 "HybridRMS_CellVoltage05";
BA_ "FlexKomSigLaenge" SG_ 1163 HVBatCellVlt_19 64;
BA_ "FlexKomSID" SG_ 1163 HVBatCellVlt_19 2907;
BA_ "FlexKomIsMotorola" SG_ 1163 HVBatCellVlt_19 1;
BA_ "FlexKomComment" SG_ 1163 HVBatCellVlt_19 ".";
BA_ "GenSigSNA" SG_ 1163 HVBatCellVlt_20 "1FFFh";
BA_ "GenSigCycleTime" SG_ 1163 HVBatCellVlt_20 1000;
BA_ "FlexKomSigStartValue" SG_ 1163 HVBatCellVlt_20 "0000000000000000h";
BA_ "FlexKomSigStartPos" SG_ 1163 HVBatCellVlt_20 7;
BA_ "FlexKomSigName" SG_ 1163 HVBatCellVlt_20 "HybridRMS_CellVoltage05";
BA_ "FlexKomSigLaenge" SG_ 1163 HVBatCellVlt_20 64;
BA_ "FlexKomSID" SG_ 1163 HVBatCellVlt_20 2907;
BA_ "FlexKomIsMotorola" SG_ 1163 HVBatCellVlt_20 1;
BA_ "FlexKomComment" SG_ 1163 HVBatCellVlt_20 ".";
BA_ "GenSigSNA" SG_ 1164 HVBatCellVlt_21 "1FFFh";
BA_ "GenSigCycleTime" SG_ 1164 HVBatCellVlt_21 1000;
BA_ "FlexKomSigStartValue" SG_ 1164 HVBatCellVlt_21 "0000000000000000h";
BA_ "FlexKomSigStartPos" SG_ 1164 HVBatCellVlt_21 7;
BA_ "FlexKomSigName" SG_ 1164 HVBatCellVlt_21 "HybridRMS_CellVoltage06";
BA_ "FlexKomSigLaenge" SG_ 1164 HVBatCellVlt_21 64;
BA_ "FlexKomSID" SG_ 1164 HVBatCellVlt_21 2906;
BA_ "FlexKomIsMotorola" SG_ 1164 HVBatCellVlt_21 1;
BA_ "FlexKomComment" SG_ 1164 HVBatCellVlt_21 ".";
BA_ "GenSigSNA" SG_ 1164 HVBatCellVlt_22 "1FFFh";
BA_ "GenSigCycleTime" SG_ 1164 HVBatCellVlt_22 1000;
BA_ "FlexKomSigStartValue" SG_ 1164 HVBatCellVlt_22 "0000000000000000h";
BA_ "FlexKomSigStartPos" SG_ 1164 HVBatCellVlt_22 7;
BA_ "FlexKomSigName" SG_ 1164 HVBatCellVlt_22 "HybridRMS_CellVoltage06";
BA_ "FlexKomSigLaenge" SG_ 1164 HVBatCellVlt_22 64;
BA_ "FlexKomSID" SG_ 1164 HVBatCellVlt_22 2906;
BA_ "FlexKomIsMotorola" SG_ 1164 HVBatCellVlt_22 1;
BA_ "FlexKomComment" SG_ 1164 HVBatCellVlt_22 ".";
BA_ "GenSigSNA" SG_ 1164 HVBatCellVlt_23 "1FFFh";
BA_ "GenSigCycleTime" SG_ 1164 HVBatCellVlt_23 1000;
BA_ "FlexKomSigStartValue" SG_ 1164 HVBatCellVlt_23 "0000000000000000h";
BA_ "FlexKomSigStartPos" SG_ 1164 HVBatCellVlt_23 7;
BA_ "FlexKomSigName" SG_ 1164 HVBatCellVlt_23 "HybridRMS_CellVoltage06";
BA_ "FlexKomSigLaenge" SG_ 1164 HVBatCellVlt_23 64;
BA_ "FlexKomSID" SG_ 1164 HVBatCellVlt_23 2906;
BA_ "FlexKomIsMotorola" SG_ 1164 HVBatCellVlt_23 1;
BA_ "FlexKomComment" SG_ 1164 HVBatCellVlt_23 ".";
BA_ "GenSigSNA" SG_ 1164 HVBatCellVlt_24 "1FFFh";
BA_ "GenSigCycleTime" SG_ 1164 HVBatCellVlt_24 1000;
BA_ "FlexKomSigStartValue" SG_ 1164 HVBatCellVlt_24 "0000000000000000h";
BA_ "FlexKomSigStartPos" SG_ 1164 HVBatCellVlt_24 7;
BA_ "FlexKomSigName" SG_ 1164 HVBatCellVlt_24 "HybridRMS_CellVoltage06";
BA_ "FlexKomSigLaenge" SG_ 1164 HVBatCellVlt_24 64;
BA_ "FlexKomSID" SG_ 1164 HVBatCellVlt_24 2906;
BA_ "FlexKomIsMotorola" SG_ 1164 HVBatCellVlt_24 1;
BA_ "FlexKomComment" SG_ 1164 HVBatCellVlt_24 ".";
BA_ "GenSigSNA" SG_ 1165 HVBatCellVlt_25 "1FFFh";
BA_ "GenSigCycleTime" SG_ 1165 HVBatCellVlt_25 1000;
BA_ "FlexKomSigStartValue" SG_ 1165 HVBatCellVlt_25 "0000000000000000h";
BA_ "FlexKomSigStartPos" SG_ 1165 HVBatCellVlt_25 7;
BA_ "FlexKomSigName" SG_ 1165 HVBatCellVlt_25 "HybridRMS_CellVoltage07";
BA_ "FlexKomSigLaenge" SG_ 1165 HVBatCellVlt_25 64;
BA_ "FlexKomSID" SG_ 1165 HVBatCellVlt_25 2905;
BA_ "FlexKomIsMotorola" SG_ 1165 HVBatCellVlt_25 1;
BA_ "FlexKomComment" SG_ 1165 HVBatCellVlt_25 ".";
BA_ "GenSigSNA" SG_ 1165 HVBatCellVlt_26 "1FFFh";
BA_ "GenSigCycleTime" SG_ 1165 HVBatCellVlt_26 1000;
BA_ "FlexKomSigStartValue" SG_ 1165 HVBatCellVlt_26 "0000000000000000h";
BA_ "FlexKomSigStartPos" SG_ 1165 HVBatCellVlt_26 7;
BA_ "FlexKomSigName" SG_ 1165 HVBatCellVlt_26 "HybridRMS_CellVoltage07";
BA_ "FlexKomSigLaenge" SG_ 1165 HVBatCellVlt_26 64;
BA_ "FlexKomSID" SG_ 1165 HVBatCellVlt_26 2905;
BA_ "FlexKomIsMotorola" SG_ 1165 HVBatCellVlt_26 1;
BA_ "FlexKomComment" SG_ 1165 HVBatCellVlt_26 ".";
BA_ "GenSigSNA" SG_ 1165 HVBatCellVlt_27 "1FFFh";
BA_ "GenSigCycleTime" SG_ 1165 HVBatCellVlt_27 1000;
BA_ "FlexKomSigStartValue" SG_ 1165 HVBatCellVlt_27 "0000000000000000h";
BA_ "FlexKomSigStartPos" SG_ 1165 HVBatCellVlt_27 7;
BA_ "FlexKomSigName" SG_ 1165 HVBatCellVlt_27 "HybridRMS_CellVoltage07";
BA_ "FlexKomSigLaenge" SG_ 1165 HVBatCellVlt_27 64;
BA_ "FlexKomSID" SG_ 1165 HVBatCellVlt_27 2905;
BA_ "FlexKomIsMotorola" SG_ 1165 HVBatCellVlt_27 1;
BA_ "FlexKomComment" SG_ 1165 HVBatCellVlt_27 ".";
BA_ "GenSigSNA" SG_ 1165 HVBatCellVlt_28 "1FFFh";
BA_ "GenSigCycleTime" SG_ 1165 HVBatCellVlt_28 1000;
BA_ "FlexKomSigStartValue" SG_ 1165 HVBatCellVlt_28 "0000000000000000h";
BA_ "FlexKomSigStartPos" SG_ 1165 HVBatCellVlt_28 7;
BA_ "FlexKomSigName" SG_ 1165 HVBatCellVlt_28 "HybridRMS_CellVoltage07";
BA_ "FlexKomSigLaenge" SG_ 1165 HVBatCellVlt_28 64;
BA_ "FlexKomSID" SG_ 1165 HVBatCellVlt_28 2905;
BA_ "FlexKomIsMotorola" SG_ 1165 HVBatCellVlt_28 1;
BA_ "FlexKomComment" SG_ 1165 HVBatCellVlt_28 ".";
BA_ "GenSigSNA" SG_ 1166 HVBatCellVlt_29 "1FFFh";
BA_ "GenSigCycleTime" SG_ 1166 HVBatCellVlt_29 1000;
BA_ "FlexKomSigStartValue" SG_ 1166 HVBatCellVlt_29 "0000000000000000h";
BA_ "FlexKomSigStartPos" SG_ 1166 HVBatCellVlt_29 7;
BA_ "FlexKomSigName" SG_ 1166 HVBatCellVlt_29 "HybridRMS_CellVoltage08";
BA_ "FlexKomSigLaenge" SG_ 1166 HVBatCellVlt_29 64;
BA_ "FlexKomSID" SG_ 1166 HVBatCellVlt_29 2904;
BA_ "FlexKomIsMotorola" SG_ 1166 HVBatCellVlt_29 1;
BA_ "FlexKomComment" SG_ 1166 HVBatCellVlt_29 ".";
BA_ "GenSigSNA" SG_ 1166 HVBatCellVlt_30 "1FFFh";
BA_ "GenSigCycleTime" SG_ 1166 HVBatCellVlt_30 1000;
BA_ "FlexKomSigStartValue" SG_ 1166 HVBatCellVlt_30 "0000000000000000h";
BA_ "FlexKomSigStartPos" SG_ 1166 HVBatCellVlt_30 7;
BA_ "FlexKomSigName" SG_ 1166 HVBatCellVlt_30 "HybridRMS_CellVoltage08";
BA_ "FlexKomSigLaenge" SG_ 1166 HVBatCellVlt_30 64;
BA_ "FlexKomSID" SG_ 1166 HVBatCellVlt_30 2904;
BA_ "FlexKomIsMotorola" SG_ 1166 HVBatCellVlt_30 1;
BA_ "FlexKomComment" SG_ 1166 HVBatCellVlt_30 ".";
BA_ "GenSigSNA" SG_ 1166 HVBatCellVlt_31 "1FFFh";
BA_ "GenSigCycleTime" SG_ 1166 HVBatCellVlt_31 1000;
BA_ "FlexKomSigStartValue" SG_ 1166 HVBatCellVlt_31 "0000000000000000h";
BA_ "FlexKomSigStartPos" SG_ 1166 HVBatCellVlt_31 7;
BA_ "FlexKomSigName" SG_ 1166 HVBatCellVlt_31 "HybridRMS_CellVoltage08";
BA_ "FlexKomSigLaenge" SG_ 1166 HVBatCellVlt_31 64;
BA_ "FlexKomSID" SG_ 1166 HVBatCellVlt_31 2904;
BA_ "FlexKomIsMotorola" SG_ 1166 HVBatCellVlt_31 1;
BA_ "FlexKomComment" SG_ 1166 HVBatCellVlt_31 ".";
BA_ "GenSigSNA" SG_ 1166 HVBatCellVlt_32 "1FFFh";
BA_ "GenSigCycleTime" SG_ 1166 HVBatCellVlt_32 1000;
BA_ "FlexKomSigStartValue" SG_ 1166 HVBatCellVlt_32 "0000000000000000h";
BA_ "FlexKomSigStartPos" SG_ 1166 HVBatCellVlt_32 7;
BA_ "FlexKomSigName" SG_ 1166 HVBatCellVlt_32 "HybridRMS_CellVoltage08";
BA_ "FlexKomSigLaenge" SG_ 1166 HVBatCellVlt_32 64;
BA_ "FlexKomSID" SG_ 1166 HVBatCellVlt_32 2904;
BA_ "FlexKomIsMotorola" SG_ 1166 HVBatCellVlt_32 1;
BA_ "FlexKomComment" SG_ 1166 HVBatCellVlt_32 ".";
BA_ "GenSigSNA" SG_ 1167 HVBatCellVlt_33 "1FFFh";
BA_ "GenSigCycleTime" SG_ 1167 HVBatCellVlt_33 1000;
BA_ "FlexKomSigStartValue" SG_ 1167 HVBatCellVlt_33 "0000000000000000h";
BA_ "FlexKomSigStartPos" SG_ 1167 HVBatCellVlt_33 7;
BA_ "FlexKomSigName" SG_ 1167 HVBatCellVlt_33 "HybridRMS_CellVoltage09";
BA_ "FlexKomSigLaenge" SG_ 1167 HVBatCellVlt_33 64;
BA_ "FlexKomSID" SG_ 1167 HVBatCellVlt_33 2903;
BA_ "FlexKomIsMotorola" SG_ 1167 HVBatCellVlt_33 1;
BA_ "FlexKomComment" SG_ 1167 HVBatCellVlt_33 ".";
BA_ "GenSigSNA" SG_ 1167 HVBatCellVlt_34 "1FFFh";
BA_ "GenSigCycleTime" SG_ 1167 HVBatCellVlt_34 1000;
BA_ "FlexKomSigStartValue" SG_ 1167 HVBatCellVlt_34 "0000000000000000h";
BA_ "FlexKomSigStartPos" SG_ 1167 HVBatCellVlt_34 7;
BA_ "FlexKomSigName" SG_ 1167 HVBatCellVlt_34 "HybridRMS_CellVoltage09";
BA_ "FlexKomSigLaenge" SG_ 1167 HVBatCellVlt_34 64;
BA_ "FlexKomSID" SG_ 1167 HVBatCellVlt_34 2903;
BA_ "FlexKomIsMotorola" SG_ 1167 HVBatCellVlt_34 1;
BA_ "FlexKomComment" SG_ 1167 HVBatCellVlt_34 ".";
BA_ "GenSigSNA" SG_ 1167 HVBatCellVlt_35 "1FFFh";
BA_ "GenSigCycleTime" SG_ 1167 HVBatCellVlt_35 1000;
BA_ "FlexKomSigStartValue" SG_ 1167 HVBatCellVlt_35 "0000000000000000h";
BA_ "FlexKomSigStartPos" SG_ 1167 HVBatCellVlt_35 7;
BA_ "FlexKomSigName" SG_ 1167 HVBatCellVlt_35 "HybridRMS_CellVoltage09";
BA_ "FlexKomSigLaenge" SG_ 1167 HVBatCellVlt_35 64;
BA_ "FlexKomSID" SG_ 1167 HVBatCellVlt_35 2903;
BA_ "FlexKomIsMotorola" SG_ 1167 HVBatCellVlt_35 1;
BA_ "FlexKomComment" SG_ 1167 HVBatCellVlt_35 ".";
BA_ "GenSigSNA" SG_ 1167 HVBatCellVlt_36 "1FFFh";
BA_ "GenSigCycleTime" SG_ 1167 HVBatCellVlt_36 1000;
BA_ "FlexKomSigStartValue" SG_ 1167 HVBatCellVlt_36 "0000000000000000h";
BA_ "FlexKomSigStartPos" SG_ 1167 HVBatCellVlt_36 7;
BA_ "FlexKomSigName" SG_ 1167 HVBatCellVlt_36 "HybridRMS_CellVoltage09";
BA_ "FlexKomSigLaenge" SG_ 1167 HVBatCellVlt_36 64;
BA_ "FlexKomSID" SG_ 1167 HVBatCellVlt_36 2903;
BA_ "FlexKomIsMotorola" SG_ 1167 HVBatCellVlt_36 1;
BA_ "FlexKomComment" SG_ 1167 HVBatCellVlt_36 ".";
BA_ "GenSigSNA" SG_ 1168 HVBatCellVlt_37 "1FFFh";
BA_ "GenSigCycleTime" SG_ 1168 HVBatCellVlt_37 1000;
BA_ "FlexKomSigStartValue" SG_ 1168 HVBatCellVlt_37 "0000000000000000h";
BA_ "FlexKomSigStartPos" SG_ 1168 HVBatCellVlt_37 7;
BA_ "FlexKomSigName" SG_ 1168 HVBatCellVlt_37 "HybridRMS_CellVoltage10";
BA_ "FlexKomSigLaenge" SG_ 1168 HVBatCellVlt_37 64;
BA_ "FlexKomSID" SG_ 1168 HVBatCellVlt_37 2902;
BA_ "FlexKomIsMotorola" SG_ 1168 HVBatCellVlt_37 1;
BA_ "FlexKomComment" SG_ 1168 HVBatCellVlt_37 ".";
BA_ "GenSigSNA" SG_ 1168 HVBatCellVlt_38 "1FFFh";
BA_ "GenSigCycleTime" SG_ 1168 HVBatCellVlt_38 1000;
BA_ "FlexKomSigStartValue" SG_ 1168 HVBatCellVlt_38 "0000000000000000h";
BA_ "FlexKomSigStartPos" SG_ 1168 HVBatCellVlt_38 7;
BA_ "FlexKomSigName" SG_ 1168 HVBatCellVlt_38 "HybridRMS_CellVoltage10";
BA_ "FlexKomSigLaenge" SG_ 1168 HVBatCellVlt_38 64;
BA_ "FlexKomSID" SG_ 1168 HVBatCellVlt_38 2902;
BA_ "FlexKomIsMotorola" SG_ 1168 HVBatCellVlt_38 1;
BA_ "FlexKomComment" SG_ 1168 HVBatCellVlt_38 ".";
BA_ "GenSigSNA" SG_ 1168 HVBatCellVlt_39 "1FFFh";
BA_ "GenSigCycleTime" SG_ 1168 HVBatCellVlt_39 1000;
BA_ "FlexKomSigStartValue" SG_ 1168 HVBatCellVlt_39 "0000000000000000h";
BA_ "FlexKomSigStartPos" SG_ 1168 HVBatCellVlt_39 7;
BA_ "FlexKomSigName" SG_ 1168 HVBatCellVlt_39 "HybridRMS_CellVoltage10";
BA_ "FlexKomSigLaenge" SG_ 1168 HVBatCellVlt_39 64;
BA_ "FlexKomSID" SG_ 1168 HVBatCellVlt_39 2902;
BA_ "FlexKomIsMotorola" SG_ 1168 HVBatCellVlt_39 1;
BA_ "FlexKomComment" SG_ 1168 HVBatCellVlt_39 ".";
BA_ "GenSigSNA" SG_ 1168 HVBatCellVlt_40 "1FFFh";
BA_ "GenSigCycleTime" SG_ 1168 HVBatCellVlt_40 1000;
BA_ "FlexKomSigStartValue" SG_ 1168 HVBatCellVlt_40 "0000000000000000h";
BA_ "FlexKomSigStartPos" SG_ 1168 HVBatCellVlt_40 7;
BA_ "FlexKomSigName" SG_ 1168 HVBatCellVlt_40 "HybridRMS_CellVoltage10";
BA_ "FlexKomSigLaenge" SG_ 1168 HVBatCellVlt_40 64;
BA_ "FlexKomSID" SG_ 1168 HVBatCellVlt_40 2902;
BA_ "FlexKomIsMotorola" SG_ 1168 HVBatCellVlt_40 1;
BA_ "FlexKomComment" SG_ 1168 HVBatCellVlt_40 ".";
BA_ "GenSigSNA" SG_ 1169 HVBatCellVlt_41 "1FFFh";
BA_ "GenSigCycleTime" SG_ 1169 HVBatCellVlt_41 1000;
BA_ "FlexKomSigStartValue" SG_ 1169 HVBatCellVlt_41 "0000000000000000h";
BA_ "FlexKomSigStartPos" SG_ 1169 HVBatCellVlt_41 7;
BA_ "FlexKomSigName" SG_ 1169 HVBatCellVlt_41 "HybridRMS_CellVoltage11";
BA_ "FlexKomSigLaenge" SG_ 1169 HVBatCellVlt_41 64;
BA_ "FlexKomSID" SG_ 1169 HVBatCellVlt_41 2901;
BA_ "FlexKomIsMotorola" SG_ 1169 HVBatCellVlt_41 1;
BA_ "FlexKomComment" SG_ 1169 HVBatCellVlt_41 ".";
BA_ "GenSigSNA" SG_ 1169 HVBatCellVlt_42 "1FFFh";
BA_ "GenSigCycleTime" SG_ 1169 HVBatCellVlt_42 1000;
BA_ "FlexKomSigStartValue" SG_ 1169 HVBatCellVlt_42 "0000000000000000h";
BA_ "FlexKomSigStartPos" SG_ 1169 HVBatCellVlt_42 7;
BA_ "FlexKomSigName" SG_ 1169 HVBatCellVlt_42 "HybridRMS_CellVoltage11";
BA_ "FlexKomSigLaenge" SG_ 1169 HVBatCellVlt_42 64;
BA_ "FlexKomSID" SG_ 1169 HVBatCellVlt_42 2901;
BA_ "FlexKomIsMotorola" SG_ 1169 HVBatCellVlt_42 1;
BA_ "FlexKomComment" SG_ 1169 HVBatCellVlt_42 ".";
BA_ "GenSigSNA" SG_ 1169 HVBatCellVlt_43 "1FFFh";
BA_ "GenSigCycleTime" SG_ 1169 HVBatCellVlt_43 1000;
BA_ "FlexKomSigStartValue" SG_ 1169 HVBatCellVlt_43 "0000000000000000h";
BA_ "FlexKomSigStartPos" SG_ 1169 HVBatCellVlt_43 7;
BA_ "FlexKomSigName" SG_ 1169 HVBatCellVlt_43 "HybridRMS_CellVoltage11";
BA_ "FlexKomSigLaenge" SG_ 1169 HVBatCellVlt_43 64;
BA_ "FlexKomSID" SG_ 1169 HVBatCellVlt_43 2901;
BA_ "FlexKomIsMotorola" SG_ 1169 HVBatCellVlt_43 1;
BA_ "FlexKomComment" SG_ 1169 HVBatCellVlt_43 ".";
BA_ "GenSigSNA" SG_ 1169 HVBatCellVlt_44 "1FFFh";
BA_ "GenSigCycleTime" SG_ 1169 HVBatCellVlt_44 1000;
BA_ "FlexKomSigStartValue" SG_ 1169 HVBatCellVlt_44 "0000000000000000h";
BA_ "FlexKomSigStartPos" SG_ 1169 HVBatCellVlt_44 7;
BA_ "FlexKomSigName" SG_ 1169 HVBatCellVlt_44 "HybridRMS_CellVoltage11";
BA_ "FlexKomSigLaenge" SG_ 1169 HVBatCellVlt_44 64;
BA_ "FlexKomSID" SG_ 1169 HVBatCellVlt_44 2901;
BA_ "FlexKomIsMotorola" SG_ 1169 HVBatCellVlt_44 1;
BA_ "FlexKomComment" SG_ 1169 HVBatCellVlt_44 ".";
BA_ "GenSigSNA" SG_ 1170 HVBatCellVlt_45 "1FFFh";
BA_ "GenSigCycleTime" SG_ 1170 HVBatCellVlt_45 1000;
BA_ "FlexKomSigStartValue" SG_ 1170 HVBatCellVlt_45 "0000000000000000h";
BA_ "FlexKomSigStartPos" SG_ 1170 HVBatCellVlt_45 7;
BA_ "FlexKomSigName" SG_ 1170 HVBatCellVlt_45 "HybridRMS_CellVoltage12";
BA_ "FlexKomSigLaenge" SG_ 1170 HVBatCellVlt_45 64;
BA_ "FlexKomSID" SG_ 1170 HVBatCellVlt_45 2900;
BA_ "FlexKomIsMotorola" SG_ 1170 HVBatCellVlt_45 1;
BA_ "FlexKomComment" SG_ 1170 HVBatCellVlt_45 ".";
BA_ "GenSigSNA" SG_ 1170 HVBatCellVlt_46 "1FFFh";
BA_ "GenSigCycleTime" SG_ 1170 HVBatCellVlt_46 1000;
BA_ "FlexKomSigStartValue" SG_ 1170 HVBatCellVlt_46 "0000000000000000h";
BA_ "FlexKomSigStartPos" SG_ 1170 HVBatCellVlt_46 7;
BA_ "FlexKomSigName" SG_ 1170 HVBatCellVlt_46 "HybridRMS_CellVoltage12";
BA_ "FlexKomSigLaenge" SG_ 1170 HVBatCellVlt_46 64;
BA_ "FlexKomSID" SG_ 1170 HVBatCellVlt_46 2900;
BA_ "FlexKomIsMotorola" SG_ 1170 HVBatCellVlt_46 1;
BA_ "FlexKomComment" SG_ 1170 HVBatCellVlt_46 ".";
BA_ "GenSigSNA" SG_ 1170 HVBatCellVlt_47 "1FFFh";
BA_ "GenSigCycleTime" SG_ 1170 HVBatCellVlt_47 1000;
BA_ "FlexKomSigStartValue" SG_ 1170 HVBatCellVlt_47 "0000000000000000h";
BA_ "FlexKomSigStartPos" SG_ 1170 HVBatCellVlt_47 7;
BA_ "FlexKomSigName" SG_ 1170 HVBatCellVlt_47 "HybridRMS_CellVoltage12";
BA_ "FlexKomSigLaenge" SG_ 1170 HVBatCellVlt_47 64;
BA_ "FlexKomSID" SG_ 1170 HVBatCellVlt_47 2900;
BA_ "FlexKomIsMotorola" SG_ 1170 HVBatCellVlt_47 1;
BA_ "FlexKomComment" SG_ 1170 HVBatCellVlt_47 ".";
BA_ "GenSigSNA" SG_ 1170 HVBatCellVlt_48 "1FFFh";
BA_ "GenSigCycleTime" SG_ 1170 HVBatCellVlt_48 1000;
BA_ "FlexKomSigStartValue" SG_ 1170 HVBatCellVlt_48 "0000000000000000h";
BA_ "FlexKomSigStartPos" SG_ 1170 HVBatCellVlt_48 7;
BA_ "FlexKomSigName" SG_ 1170 HVBatCellVlt_48 "HybridRMS_CellVoltage12";
BA_ "FlexKomSigLaenge" SG_ 1170 HVBatCellVlt_48 64;
BA_ "FlexKomSID" SG_ 1170 HVBatCellVlt_48 2900;
BA_ "FlexKomIsMotorola" SG_ 1170 HVBatCellVlt_48 1;
BA_ "FlexKomComment" SG_ 1170 HVBatCellVlt_48 ".";
BA_ "GenSigSNA" SG_ 1171 HVBatCellVlt_49 "1FFFh";
BA_ "GenSigCycleTime" SG_ 1171 HVBatCellVlt_49 1000;
BA_ "FlexKomSigStartValue" SG_ 1171 HVBatCellVlt_49 "0000000000000000h";
BA_ "FlexKomSigStartPos" SG_ 1171 HVBatCellVlt_49 7;
BA_ "FlexKomSigName" SG_ 1171 HVBatCellVlt_49 "HybridRMS_CellVoltage13";
BA_ "FlexKomSigLaenge" SG_ 1171 HVBatCellVlt_49 64;
BA_ "FlexKomSID" SG_ 1171 HVBatCellVlt_49 2899;
BA_ "FlexKomIsMotorola" SG_ 1171 HVBatCellVlt_49 1;
BA_ "FlexKomComment" SG_ 1171 HVBatCellVlt_49 ".";
BA_ "GenSigSNA" SG_ 1171 HVBatCellVlt_50 "1FFFh";
BA_ "GenSigCycleTime" SG_ 1171 HVBatCellVlt_50 1000;
BA_ "FlexKomSigStartValue" SG_ 1171 HVBatCellVlt_50 "0000000000000000h";
BA_ "FlexKomSigStartPos" SG_ 1171 HVBatCellVlt_50 7;
BA_ "FlexKomSigName" SG_ 1171 HVBatCellVlt_50 "HybridRMS_CellVoltage13";
BA_ "FlexKomSigLaenge" SG_ 1171 HVBatCellVlt_50 64;
BA_ "FlexKomSID" SG_ 1171 HVBatCellVlt_50 2899;
BA_ "FlexKomIsMotorola" SG_ 1171 HVBatCellVlt_50 1;
BA_ "FlexKomComment" SG_ 1171 HVBatCellVlt_50 ".";
BA_ "GenSigSNA" SG_ 1171 HVBatCellVlt_51 "1FFFh";
BA_ "GenSigCycleTime" SG_ 1171 HVBatCellVlt_51 1000;
BA_ "FlexKomSigStartValue" SG_ 1171 HVBatCellVlt_51 "0000000000000000h";
BA_ "FlexKomSigStartPos" SG_ 1171 HVBatCellVlt_51 7;
BA_ "FlexKomSigName" SG_ 1171 HVBatCellVlt_51 "HybridRMS_CellVoltage13";
BA_ "FlexKomSigLaenge" SG_ 1171 HVBatCellVlt_51 64;
BA_ "FlexKomSID" SG_ 1171 HVBatCellVlt_51 2899;
BA_ "FlexKomIsMotorola" SG_ 1171 HVBatCellVlt_51 1;
BA_ "FlexKomComment" SG_ 1171 HVBatCellVlt_51 ".";
BA_ "GenSigSNA" SG_ 1171 HVBatCellVlt_52 "1FFFh";
BA_ "GenSigCycleTime" SG_ 1171 HVBatCellVlt_52 1000;
BA_ "FlexKomSigStartValue" SG_ 1171 HVBatCellVlt_52 "0000000000000000h";
BA_ "FlexKomSigStartPos" SG_ 1171 HVBatCellVlt_52 7;
BA_ "FlexKomSigName" SG_ 1171 HVBatCellVlt_52 "HybridRMS_CellVoltage13";
BA_ "FlexKomSigLaenge" SG_ 1171 HVBatCellVlt_52 64;
BA_ "FlexKomSID" SG_ 1171 HVBatCellVlt_52 2899;
BA_ "FlexKomIsMotorola" SG_ 1171 HVBatCellVlt_52 1;
BA_ "FlexKomComment" SG_ 1171 HVBatCellVlt_52 ".";
BA_ "GenSigSNA" SG_ 1172 HVBatCellVlt_53 "1FFFh";
BA_ "GenSigCycleTime" SG_ 1172 HVBatCellVlt_53 1000;
BA_ "FlexKomSigStartValue" SG_ 1172 HVBatCellVlt_53 "0000000000000000h";
BA_ "FlexKomSigStartPos" SG_ 1172 HVBatCellVlt_53 7;
BA_ "FlexKomSigName" SG_ 1172 HVBatCellVlt_53 "HybridRMS_CellVoltage14";
BA_ "FlexKomSigLaenge" SG_ 1172 HVBatCellVlt_53 64;
BA_ "FlexKomSID" SG_ 1172 HVBatCellVlt_53 2898;
BA_ "FlexKomIsMotorola" SG_ 1172 HVBatCellVlt_53 1;
BA_ "FlexKomComment" SG_ 1172 HVBatCellVlt_53 ".";
BA_ "GenSigSNA" SG_ 1172 HVBatCellVlt_54 "1FFFh";
BA_ "GenSigCycleTime" SG_ 1172 HVBatCellVlt_54 1000;
BA_ "FlexKomSigStartValue" SG_ 1172 HVBatCellVlt_54 "0000000000000000h";
BA_ "FlexKomSigStartPos" SG_ 1172 HVBatCellVlt_54 7;
BA_ "FlexKomSigName" SG_ 1172 HVBatCellVlt_54 "HybridRMS_CellVoltage14";
BA_ "FlexKomSigLaenge" SG_ 1172 HVBatCellVlt_54 64;
BA_ "FlexKomSID" SG_ 1172 HVBatCellVlt_54 2898;
BA_ "FlexKomIsMotorola" SG_ 1172 HVBatCellVlt_54 1;
BA_ "FlexKomComment" SG_ 1172 HVBatCellVlt_54 ".";
BA_ "GenSigSNA" SG_ 1172 HVBatCellVlt_55 "1FFFh";
BA_ "GenSigCycleTime" SG_ 1172 HVBatCellVlt_55 1000;
BA_ "FlexKomSigStartValue" SG_ 1172 HVBatCellVlt_55 "0000000000000000h";
BA_ "FlexKomSigStartPos" SG_ 1172 HVBatCellVlt_55 7;
BA_ "FlexKomSigName" SG_ 1172 HVBatCellVlt_55 "HybridRMS_CellVoltage14";
BA_ "FlexKomSigLaenge" SG_ 1172 HVBatCellVlt_55 64;
BA_ "FlexKomSID" SG_ 1172 HVBatCellVlt_55 2898;
BA_ "FlexKomIsMotorola" SG_ 1172 HVBatCellVlt_55 1;
BA_ "FlexKomComment" SG_ 1172 HVBatCellVlt_55 ".";
BA_ "GenSigSNA" SG_ 1172 HVBatCellVlt_56 "1FFFh";
BA_ "GenSigCycleTime" SG_ 1172 HVBatCellVlt_56 1000;
BA_ "FlexKomSigStartValue" SG_ 1172 HVBatCellVlt_56 "0000000000000000h";
BA_ "FlexKomSigStartPos" SG_ 1172 HVBatCellVlt_56 7;
BA_ "FlexKomSigName" SG_ 1172 HVBatCellVlt_56 "HybridRMS_CellVoltage14";
BA_ "FlexKomSigLaenge" SG_ 1172 HVBatCellVlt_56 64;
BA_ "FlexKomSID" SG_ 1172 HVBatCellVlt_56 2898;
BA_ "FlexKomIsMotorola" SG_ 1172 HVBatCellVlt_56 1;
BA_ "FlexKomComment" SG_ 1172 HVBatCellVlt_56 ".";
BA_ "GenSigSNA" SG_ 1173 HVBatCellVlt_57 "1FFFh";
BA_ "GenSigCycleTime" SG_ 1173 HVBatCellVlt_57 1000;
BA_ "FlexKomSigStartValue" SG_ 1173 HVBatCellVlt_57 "0000000000000000h";
BA_ "FlexKomSigStartPos" SG_ 1173 HVBatCellVlt_57 7;
BA_ "FlexKomSigName" SG_ 1173 HVBatCellVlt_57 "HybridRMS_CellVoltage15";
BA_ "FlexKomSigLaenge" SG_ 1173 HVBatCellVlt_57 64;
BA_ "FlexKomSID" SG_ 1173 HVBatCellVlt_57 2897;
BA_ "FlexKomIsMotorola" SG_ 1173 HVBatCellVlt_57 1;
BA_ "FlexKomComment" SG_ 1173 HVBatCellVlt_57 ".";
BA_ "GenSigSNA" SG_ 1173 HVBatCellVlt_58 "1FFFh";
BA_ "GenSigCycleTime" SG_ 1173 HVBatCellVlt_58 1000;
BA_ "FlexKomSigStartValue" SG_ 1173 HVBatCellVlt_58 "0000000000000000h";
BA_ "FlexKomSigStartPos" SG_ 1173 HVBatCellVlt_58 7;
BA_ "FlexKomSigName" SG_ 1173 HVBatCellVlt_58 "HybridRMS_CellVoltage15";
BA_ "FlexKomSigLaenge" SG_ 1173 HVBatCellVlt_58 64;
BA_ "FlexKomSID" SG_ 1173 HVBatCellVlt_58 2897;
BA_ "FlexKomIsMotorola" SG_ 1173 HVBatCellVlt_58 1;
BA_ "FlexKomComment" SG_ 1173 HVBatCellVlt_58 ".";
BA_ "GenSigSNA" SG_ 1173 HVBatCellVlt_59 "1FFFh";
BA_ "GenSigCycleTime" SG_ 1173 HVBatCellVlt_59 1000;
BA_ "FlexKomSigStartValue" SG_ 1173 HVBatCellVlt_59 "0000000000000000h";
BA_ "FlexKomSigStartPos" SG_ 1173 HVBatCellVlt_59 7;
BA_ "FlexKomSigName" SG_ 1173 HVBatCellVlt_59 "HybridRMS_CellVoltage15";
BA_ "FlexKomSigLaenge" SG_ 1173 HVBatCellVlt_59 64;
BA_ "FlexKomSID" SG_ 1173 HVBatCellVlt_59 2897;
BA_ "FlexKomIsMotorola" SG_ 1173 HVBatCellVlt_59 1;
BA_ "FlexKomComment" SG_ 1173 HVBatCellVlt_59 ".";
BA_ "GenSigSNA" SG_ 1173 HVBatCellVlt_60 "1FFFh";
BA_ "GenSigCycleTime" SG_ 1173 HVBatCellVlt_60 1000;
BA_ "FlexKomSigStartValue" SG_ 1173 HVBatCellVlt_60 "0000000000000000h";
BA_ "FlexKomSigStartPos" SG_ 1173 HVBatCellVlt_60 7;
BA_ "FlexKomSigName" SG_ 1173 HVBatCellVlt_60 "HybridRMS_CellVoltage15";
BA_ "FlexKomSigLaenge" SG_ 1173 HVBatCellVlt_60 64;
BA_ "FlexKomSID" SG_ 1173 HVBatCellVlt_60 2897;
BA_ "FlexKomIsMotorola" SG_ 1173 HVBatCellVlt_60 1;
BA_ "FlexKomComment" SG_ 1173 HVBatCellVlt_60 ".";
BA_ "GenSigSNA" SG_ 1174 HVBatCellVlt_61 "1FFFh";
BA_ "GenSigCycleTime" SG_ 1174 HVBatCellVlt_61 1000;
BA_ "FlexKomSigStartValue" SG_ 1174 HVBatCellVlt_61 "0000000000000000h";
BA_ "FlexKomSigStartPos" SG_ 1174 HVBatCellVlt_61 7;
BA_ "FlexKomSigName" SG_ 1174 HVBatCellVlt_61 "HybridRMS_CellVoltage16";
BA_ "FlexKomSigLaenge" SG_ 1174 HVBatCellVlt_61 64;
BA_ "FlexKomSID" SG_ 1174 HVBatCellVlt_61 2896;
BA_ "FlexKomIsMotorola" SG_ 1174 HVBatCellVlt_61 1;
BA_ "FlexKomComment" SG_ 1174 HVBatCellVlt_61 ".";
BA_ "GenSigSNA" SG_ 1174 HVBatCellVlt_62 "1FFFh";
BA_ "GenSigCycleTime" SG_ 1174 HVBatCellVlt_62 1000;
BA_ "FlexKomSigStartValue" SG_ 1174 HVBatCellVlt_62 "0000000000000000h";
BA_ "FlexKomSigStartPos" SG_ 1174 HVBatCellVlt_62 7;
BA_ "FlexKomSigName" SG_ 1174 HVBatCellVlt_62 "HybridRMS_CellVoltage16";
BA_ "FlexKomSigLaenge" SG_ 1174 HVBatCellVlt_62 64;
BA_ "FlexKomSID" SG_ 1174 HVBatCellVlt_62 2896;
BA_ "FlexKomIsMotorola" SG_ 1174 HVBatCellVlt_62 1;
BA_ "FlexKomComment" SG_ 1174 HVBatCellVlt_62 ".";
BA_ "GenSigSNA" SG_ 1174 HVBatCellVlt_63 "1FFFh";
BA_ "GenSigCycleTime" SG_ 1174 HVBatCellVlt_63 1000;
BA_ "FlexKomSigStartValue" SG_ 1174 HVBatCellVlt_63 "0000000000000000h";
BA_ "FlexKomSigStartPos" SG_ 1174 HVBatCellVlt_63 7;
BA_ "FlexKomSigName" SG_ 1174 HVBatCellVlt_63 "HybridRMS_CellVoltage16";
BA_ "FlexKomSigLaenge" SG_ 1174 HVBatCellVlt_63 64;
BA_ "FlexKomSID" SG_ 1174 HVBatCellVlt_63 2896;
BA_ "FlexKomIsMotorola" SG_ 1174 HVBatCellVlt_63 1;
BA_ "FlexKomComment" SG_ 1174 HVBatCellVlt_63 ".";
BA_ "GenSigSNA" SG_ 1174 HVBatCellVlt_64 "1FFFh";
BA_ "GenSigCycleTime" SG_ 1174 HVBatCellVlt_64 1000;
BA_ "FlexKomSigStartValue" SG_ 1174 HVBatCellVlt_64 "0000000000000000h";
BA_ "FlexKomSigStartPos" SG_ 1174 HVBatCellVlt_64 7;
BA_ "FlexKomSigName" SG_ 1174 HVBatCellVlt_64 "HybridRMS_CellVoltage16";
BA_ "FlexKomSigLaenge" SG_ 1174 HVBatCellVlt_64 64;
BA_ "FlexKomSID" SG_ 1174 HVBatCellVlt_64 2896;
BA_ "FlexKomIsMotorola" SG_ 1174 HVBatCellVlt_64 1;
BA_ "FlexKomComment" SG_ 1174 HVBatCellVlt_64 ".";
BA_ "GenSigSNA" SG_ 1175 HVBatCellVlt_65 "1FFFh";
BA_ "GenSigCycleTime" SG_ 1175 HVBatCellVlt_65 1000;
BA_ "FlexKomSigStartValue" SG_ 1175 HVBatCellVlt_65 "0000000000000000h";
BA_ "FlexKomSigStartPos" SG_ 1175 HVBatCellVlt_65 7;
BA_ "FlexKomSigName" SG_ 1175 HVBatCellVlt_65 "HybridRMS_CellVoltage17";
BA_ "FlexKomSigLaenge" SG_ 1175 HVBatCellVlt_65 64;
BA_ "FlexKomSID" SG_ 1175 HVBatCellVlt_65 2895;
BA_ "FlexKomIsMotorola" SG_ 1175 HVBatCellVlt_65 1;
BA_ "FlexKomComment" SG_ 1175 HVBatCellVlt_65 ".";
BA_ "GenSigSNA" SG_ 1175 HVBatCellVlt_66 "1FFFh";
BA_ "GenSigCycleTime" SG_ 1175 HVBatCellVlt_66 1000;
BA_ "FlexKomSigStartValue" SG_ 1175 HVBatCellVlt_66 "0000000000000000h";
BA_ "FlexKomSigStartPos" SG_ 1175 HVBatCellVlt_66 7;
BA_ "FlexKomSigName" SG_ 1175 HVBatCellVlt_66 "HybridRMS_CellVoltage17";
BA_ "FlexKomSigLaenge" SG_ 1175 HVBatCellVlt_66 64;
BA_ "FlexKomSID" SG_ 1175 HVBatCellVlt_66 2895;
BA_ "FlexKomIsMotorola" SG_ 1175 HVBatCellVlt_66 1;
BA_ "FlexKomComment" SG_ 1175 HVBatCellVlt_66 ".";
BA_ "GenSigSNA" SG_ 1175 HVBatCellVlt_67 "1FFFh";
BA_ "GenSigCycleTime" SG_ 1175 HVBatCellVlt_67 1000;
BA_ "FlexKomSigStartValue" SG_ 1175 HVBatCellVlt_67 "0000000000000000h";
BA_ "FlexKomSigStartPos" SG_ 1175 HVBatCellVlt_67 7;
BA_ "FlexKomSigName" SG_ 1175 HVBatCellVlt_67 "HybridRMS_CellVoltage17";
BA_ "FlexKomSigLaenge" SG_ 1175 HVBatCellVlt_67 64;
BA_ "FlexKomSID" SG_ 1175 HVBatCellVlt_67 2895;
BA_ "FlexKomIsMotorola" SG_ 1175 HVBatCellVlt_67 1;
BA_ "FlexKomComment" SG_ 1175 HVBatCellVlt_67 ".";
BA_ "GenSigSNA" SG_ 1175 HVBatCellVlt_68 "1FFFh";
BA_ "GenSigCycleTime" SG_ 1175 HVBatCellVlt_68 1000;
BA_ "FlexKomSigStartValue" SG_ 1175 HVBatCellVlt_68 "0000000000000000h";
BA_ "FlexKomSigStartPos" SG_ 1175 HVBatCellVlt_68 7;
BA_ "FlexKomSigName" SG_ 1175 HVBatCellVlt_68 "HybridRMS_CellVoltage17";
BA_ "FlexKomSigLaenge" SG_ 1175 HVBatCellVlt_68 64;
BA_ "FlexKomSID" SG_ 1175 HVBatCellVlt_68 2895;
BA_ "FlexKomIsMotorola" SG_ 1175 HVBatCellVlt_68 1;
BA_ "FlexKomComment" SG_ 1175 HVBatCellVlt_68 ".";
BA_ "GenSigSNA" SG_ 1176 HVBatCellVlt_69 "1FFFh";
BA_ "GenSigCycleTime" SG_ 1176 HVBatCellVlt_69 1000;
BA_ "FlexKomSigStartValue" SG_ 1176 HVBatCellVlt_69 "0000000000000000h";
BA_ "FlexKomSigStartPos" SG_ 1176 HVBatCellVlt_69 7;
BA_ "FlexKomSigName" SG_ 1176 HVBatCellVlt_69 "HybridRMS_CellVoltage18";
BA_ "FlexKomSigLaenge" SG_ 1176 HVBatCellVlt_69 64;
BA_ "FlexKomSID" SG_ 1176 HVBatCellVlt_69 2894;
BA_ "FlexKomIsMotorola" SG_ 1176 HVBatCellVlt_69 1;
BA_ "FlexKomComment" SG_ 1176 HVBatCellVlt_69 ".";
BA_ "GenSigSNA" SG_ 1176 HVBatCellVlt_70 "1FFFh";
BA_ "GenSigCycleTime" SG_ 1176 HVBatCellVlt_70 1000;
BA_ "FlexKomSigStartValue" SG_ 1176 HVBatCellVlt_70 "0000000000000000h";
BA_ "FlexKomSigStartPos" SG_ 1176 HVBatCellVlt_70 7;
BA_ "FlexKomSigName" SG_ 1176 HVBatCellVlt_70 "HybridRMS_CellVoltage18";
BA_ "FlexKomSigLaenge" SG_ 1176 HVBatCellVlt_70 64;
BA_ "FlexKomSID" SG_ 1176 HVBatCellVlt_70 2894;
BA_ "FlexKomIsMotorola" SG_ 1176 HVBatCellVlt_70 1;
BA_ "FlexKomComment" SG_ 1176 HVBatCellVlt_70 ".";
BA_ "GenSigSNA" SG_ 1176 HVBatCellVlt_71 "1FFFh";
BA_ "GenSigCycleTime" SG_ 1176 HVBatCellVlt_71 1000;
BA_ "FlexKomSigStartValue" SG_ 1176 HVBatCellVlt_71 "0000000000000000h";
BA_ "FlexKomSigStartPos" SG_ 1176 HVBatCellVlt_71 7;
BA_ "FlexKomSigName" SG_ 1176 HVBatCellVlt_71 "HybridRMS_CellVoltage18";
BA_ "FlexKomSigLaenge" SG_ 1176 HVBatCellVlt_71 64;
BA_ "FlexKomSID" SG_ 1176 HVBatCellVlt_71 2894;
BA_ "FlexKomIsMotorola" SG_ 1176 HVBatCellVlt_71 1;
BA_ "FlexKomComment" SG_ 1176 HVBatCellVlt_71 ".";
BA_ "GenSigSNA" SG_ 1176 HVBatCellVlt_72 "1FFFh";
BA_ "GenSigCycleTime" SG_ 1176 HVBatCellVlt_72 1000;
BA_ "FlexKomSigStartValue" SG_ 1176 HVBatCellVlt_72 "0000000000000000h";
BA_ "FlexKomSigStartPos" SG_ 1176 HVBatCellVlt_72 7;
BA_ "FlexKomSigName" SG_ 1176 HVBatCellVlt_72 "HybridRMS_CellVoltage18";
BA_ "FlexKomSigLaenge" SG_ 1176 HVBatCellVlt_72 64;
BA_ "FlexKomSID" SG_ 1176 HVBatCellVlt_72 2894;
BA_ "FlexKomIsMotorola" SG_ 1176 HVBatCellVlt_72 1;
BA_ "FlexKomComment" SG_ 1176 HVBatCellVlt_72 ".";
BA_ "GenSigSNA" SG_ 1177 HVBatCellVlt_73 "1FFFh";
BA_ "GenSigCycleTime" SG_ 1177 HVBatCellVlt_73 1000;
BA_ "FlexKomSigStartValue" SG_ 1177 HVBatCellVlt_73 "0000000000000000h";
BA_ "FlexKomSigStartPos" SG_ 1177 HVBatCellVlt_73 7;
BA_ "FlexKomSigName" SG_ 1177 HVBatCellVlt_73 "HybridRMS_CellVoltage19";
BA_ "FlexKomSigLaenge" SG_ 1177 HVBatCellVlt_73 64;
BA_ "FlexKomSID" SG_ 1177 HVBatCellVlt_73 2893;
BA_ "FlexKomIsMotorola" SG_ 1177 HVBatCellVlt_73 1;
BA_ "FlexKomComment" SG_ 1177 HVBatCellVlt_73 ".";
BA_ "GenSigSNA" SG_ 1177 HVBatCellVlt_74 "1FFFh";
BA_ "GenSigCycleTime" SG_ 1177 HVBatCellVlt_74 1000;
BA_ "FlexKomSigStartValue" SG_ 1177 HVBatCellVlt_74 "0000000000000000h";
BA_ "FlexKomSigStartPos" SG_ 1177 HVBatCellVlt_74 7;
BA_ "FlexKomSigName" SG_ 1177 HVBatCellVlt_74 "HybridRMS_CellVoltage19";
BA_ "FlexKomSigLaenge" SG_ 1177 HVBatCellVlt_74 64;
BA_ "FlexKomSID" SG_ 1177 HVBatCellVlt_74 2893;
BA_ "FlexKomIsMotorola" SG_ 1177 HVBatCellVlt_74 1;
BA_ "FlexKomComment" SG_ 1177 HVBatCellVlt_74 ".";
BA_ "GenSigSNA" SG_ 1177 HVBatCellVlt_75 "1FFFh";
BA_ "GenSigCycleTime" SG_ 1177 HVBatCellVlt_75 1000;
BA_ "FlexKomSigStartValue" SG_ 1177 HVBatCellVlt_75 "0000000000000000h";
BA_ "FlexKomSigStartPos" SG_ 1177 HVBatCellVlt_75 7;
BA_ "FlexKomSigName" SG_ 1177 HVBatCellVlt_75 "HybridRMS_CellVoltage19";
BA_ "FlexKomSigLaenge" SG_ 1177 HVBatCellVlt_75 64;
BA_ "FlexKomSID" SG_ 1177 HVBatCellVlt_75 2893;
BA_ "FlexKomIsMotorola" SG_ 1177 HVBatCellVlt_75 1;
BA_ "FlexKomComment" SG_ 1177 HVBatCellVlt_75 ".";
BA_ "GenSigSNA" SG_ 1177 HVBatCellVlt_76 "1FFFh";
BA_ "GenSigCycleTime" SG_ 1177 HVBatCellVlt_76 1000;
BA_ "FlexKomSigStartValue" SG_ 1177 HVBatCellVlt_76 "0000000000000000h";
BA_ "FlexKomSigStartPos" SG_ 1177 HVBatCellVlt_76 7;
BA_ "FlexKomSigName" SG_ 1177 HVBatCellVlt_76 "HybridRMS_CellVoltage19";
BA_ "FlexKomSigLaenge" SG_ 1177 HVBatCellVlt_76 64;
BA_ "FlexKomSID" SG_ 1177 HVBatCellVlt_76 2893;
BA_ "FlexKomIsMotorola" SG_ 1177 HVBatCellVlt_76 1;
BA_ "FlexKomComment" SG_ 1177 HVBatCellVlt_76 ".";
BA_ "GenSigSNA" SG_ 1178 HVBatCellVlt_77 "1FFFh";
BA_ "GenSigCycleTime" SG_ 1178 HVBatCellVlt_77 1000;
BA_ "FlexKomSigStartValue" SG_ 1178 HVBatCellVlt_77 "0000000000000000h";
BA_ "FlexKomSigStartPos" SG_ 1178 HVBatCellVlt_77 7;
BA_ "FlexKomSigName" SG_ 1178 HVBatCellVlt_77 "HybridRMS_CellVoltage20";
BA_ "FlexKomSigLaenge" SG_ 1178 HVBatCellVlt_77 64;
BA_ "FlexKomSID" SG_ 1178 HVBatCellVlt_77 2892;
BA_ "FlexKomIsMotorola" SG_ 1178 HVBatCellVlt_77 1;
BA_ "FlexKomComment" SG_ 1178 HVBatCellVlt_77 ".";
BA_ "GenSigSNA" SG_ 1178 HVBatCellVlt_78 "1FFFh";
BA_ "GenSigCycleTime" SG_ 1178 HVBatCellVlt_78 1000;
BA_ "FlexKomSigStartValue" SG_ 1178 HVBatCellVlt_78 "0000000000000000h";
BA_ "FlexKomSigStartPos" SG_ 1178 HVBatCellVlt_78 7;
BA_ "FlexKomSigName" SG_ 1178 HVBatCellVlt_78 "HybridRMS_CellVoltage20";
BA_ "FlexKomSigLaenge" SG_ 1178 HVBatCellVlt_78 64;
BA_ "FlexKomSID" SG_ 1178 HVBatCellVlt_78 2892;
BA_ "FlexKomIsMotorola" SG_ 1178 HVBatCellVlt_78 1;
BA_ "FlexKomComment" SG_ 1178 HVBatCellVlt_78 ".";
BA_ "GenSigSNA" SG_ 1178 HVBatCellVlt_79 "1FFFh";
BA_ "GenSigCycleTime" SG_ 1178 HVBatCellVlt_79 1000;
BA_ "FlexKomSigStartValue" SG_ 1178 HVBatCellVlt_79 "0000000000000000h";
BA_ "FlexKomSigStartPos" SG_ 1178 HVBatCellVlt_79 7;
BA_ "FlexKomSigName" SG_ 1178 HVBatCellVlt_79 "HybridRMS_CellVoltage20";
BA_ "FlexKomSigLaenge" SG_ 1178 HVBatCellVlt_79 64;
BA_ "FlexKomSID" SG_ 1178 HVBatCellVlt_79 2892;
BA_ "FlexKomIsMotorola" SG_ 1178 HVBatCellVlt_79 1;
BA_ "FlexKomComment" SG_ 1178 HVBatCellVlt_79 ".";
BA_ "GenSigSNA" SG_ 1178 HVBatCellVlt_80 "1FFFh";
BA_ "GenSigCycleTime" SG_ 1178 HVBatCellVlt_80 1000;
BA_ "FlexKomSigStartValue" SG_ 1178 HVBatCellVlt_80 "0000000000000000h";
BA_ "FlexKomSigStartPos" SG_ 1178 HVBatCellVlt_80 7;
BA_ "FlexKomSigName" SG_ 1178 HVBatCellVlt_80 "HybridRMS_CellVoltage20";
BA_ "FlexKomSigLaenge" SG_ 1178 HVBatCellVlt_80 64;
BA_ "FlexKomSID" SG_ 1178 HVBatCellVlt_80 2892;
BA_ "FlexKomIsMotorola" SG_ 1178 HVBatCellVlt_80 1;
BA_ "FlexKomComment" SG_ 1178 HVBatCellVlt_80 ".";
BA_ "GenSigSNA" SG_ 1179 HVBatCellVlt_81 "1FFFh";
BA_ "GenSigCycleTime" SG_ 1179 HVBatCellVlt_81 1000;
BA_ "FlexKomSigStartValue" SG_ 1179 HVBatCellVlt_81 "0000000000000000h";
BA_ "FlexKomSigStartPos" SG_ 1179 HVBatCellVlt_81 7;
BA_ "FlexKomSigName" SG_ 1179 HVBatCellVlt_81 "HybridRMS_CellVoltage21";
BA_ "FlexKomSigLaenge" SG_ 1179 HVBatCellVlt_81 64;
BA_ "FlexKomSID" SG_ 1179 HVBatCellVlt_81 2891;
BA_ "FlexKomIsMotorola" SG_ 1179 HVBatCellVlt_81 1;
BA_ "FlexKomComment" SG_ 1179 HVBatCellVlt_81 ".";
BA_ "GenSigSNA" SG_ 1179 HVBatCellVlt_82 "1FFFh";
BA_ "GenSigCycleTime" SG_ 1179 HVBatCellVlt_82 1000;
BA_ "FlexKomSigStartValue" SG_ 1179 HVBatCellVlt_82 "0000000000000000h";
BA_ "FlexKomSigStartPos" SG_ 1179 HVBatCellVlt_82 7;
BA_ "FlexKomSigName" SG_ 1179 HVBatCellVlt_82 "HybridRMS_CellVoltage21";
BA_ "FlexKomSigLaenge" SG_ 1179 HVBatCellVlt_82 64;
BA_ "FlexKomSID" SG_ 1179 HVBatCellVlt_82 2891;
BA_ "FlexKomIsMotorola" SG_ 1179 HVBatCellVlt_82 1;
BA_ "FlexKomComment" SG_ 1179 HVBatCellVlt_82 ".";
BA_ "GenSigSNA" SG_ 1179 HVBatCellVlt_83 "1FFFh";
BA_ "GenSigCycleTime" SG_ 1179 HVBatCellVlt_83 1000;
BA_ "FlexKomSigStartValue" SG_ 1179 HVBatCellVlt_83 "0000000000000000h";
BA_ "FlexKomSigStartPos" SG_ 1179 HVBatCellVlt_83 7;
BA_ "FlexKomSigName" SG_ 1179 HVBatCellVlt_83 "HybridRMS_CellVoltage21";
BA_ "FlexKomSigLaenge" SG_ 1179 HVBatCellVlt_83 64;
BA_ "FlexKomSID" SG_ 1179 HVBatCellVlt_83 2891;
BA_ "FlexKomIsMotorola" SG_ 1179 HVBatCellVlt_83 1;
BA_ "FlexKomComment" SG_ 1179 HVBatCellVlt_83 ".";
BA_ "GenSigSNA" SG_ 1179 HVBatCellVlt_84 "1FFFh";
BA_ "GenSigCycleTime" SG_ 1179 HVBatCellVlt_84 1000;
BA_ "FlexKomSigStartValue" SG_ 1179 HVBatCellVlt_84 "0000000000000000h";
BA_ "FlexKomSigStartPos" SG_ 1179 HVBatCellVlt_84 7;
BA_ "FlexKomSigName" SG_ 1179 HVBatCellVlt_84 "HybridRMS_CellVoltage21";
BA_ "FlexKomSigLaenge" SG_ 1179 HVBatCellVlt_84 64;
BA_ "FlexKomSID" SG_ 1179 HVBatCellVlt_84 2891;
BA_ "FlexKomIsMotorola" SG_ 1179 HVBatCellVlt_84 1;
BA_ "FlexKomComment" SG_ 1179 HVBatCellVlt_84 ".";
BA_ "GenSigSNA" SG_ 1180 HVBatCellVlt_85 "1FFFh";
BA_ "GenSigCycleTime" SG_ 1180 HVBatCellVlt_85 1000;
BA_ "FlexKomSigStartValue" SG_ 1180 HVBatCellVlt_85 "0000000000000000h";
BA_ "FlexKomSigStartPos" SG_ 1180 HVBatCellVlt_85 7;
BA_ "FlexKomSigName" SG_ 1180 HVBatCellVlt_85 "HybridRMS_CellVoltage22";
BA_ "FlexKomSigLaenge" SG_ 1180 HVBatCellVlt_85 64;
BA_ "FlexKomSID" SG_ 1180 HVBatCellVlt_85 2890;
BA_ "FlexKomIsMotorola" SG_ 1180 HVBatCellVlt_85 1;
BA_ "FlexKomComment" SG_ 1180 HVBatCellVlt_85 ".";
BA_ "GenSigSNA" SG_ 1180 HVBatCellVlt_86 "1FFFh";
BA_ "GenSigCycleTime" SG_ 1180 HVBatCellVlt_86 1000;
BA_ "FlexKomSigStartValue" SG_ 1180 HVBatCellVlt_86 "0000000000000000h";
BA_ "FlexKomSigStartPos" SG_ 1180 HVBatCellVlt_86 7;
BA_ "FlexKomSigName" SG_ 1180 HVBatCellVlt_86 "HybridRMS_CellVoltage22";
BA_ "FlexKomSigLaenge" SG_ 1180 HVBatCellVlt_86 64;
BA_ "FlexKomSID" SG_ 1180 HVBatCellVlt_86 2890;
BA_ "FlexKomIsMotorola" SG_ 1180 HVBatCellVlt_86 1;
BA_ "FlexKomComment" SG_ 1180 HVBatCellVlt_86 ".";
BA_ "GenSigSNA" SG_ 1180 HVBatCellVlt_87 "1FFFh";
BA_ "GenSigCycleTime" SG_ 1180 HVBatCellVlt_87 1000;
BA_ "FlexKomSigStartValue" SG_ 1180 HVBatCellVlt_87 "0000000000000000h";
BA_ "FlexKomSigStartPos" SG_ 1180 HVBatCellVlt_87 7;
BA_ "FlexKomSigName" SG_ 1180 HVBatCellVlt_87 "HybridRMS_CellVoltage22";
BA_ "FlexKomSigLaenge" SG_ 1180 HVBatCellVlt_87 64;
BA_ "FlexKomSID" SG_ 1180 HVBatCellVlt_87 2890;
BA_ "FlexKomIsMotorola" SG_ 1180 HVBatCellVlt_87 1;
BA_ "FlexKomComment" SG_ 1180 HVBatCellVlt_87 ".";
BA_ "GenSigSNA" SG_ 1180 HVBatCellVlt_88 "1FFFh";
BA_ "GenSigCycleTime" SG_ 1180 HVBatCellVlt_88 1000;
BA_ "FlexKomSigStartValue" SG_ 1180 HVBatCellVlt_88 "0000000000000000h";
BA_ "FlexKomSigStartPos" SG_ 1180 HVBatCellVlt_88 7;
BA_ "FlexKomSigName" SG_ 1180 HVBatCellVlt_88 "HybridRMS_CellVoltage22";
BA_ "FlexKomSigLaenge" SG_ 1180 HVBatCellVlt_88 64;
BA_ "FlexKomSID" SG_ 1180 HVBatCellVlt_88 2890;
BA_ "FlexKomIsMotorola" SG_ 1180 HVBatCellVlt_88 1;
BA_ "FlexKomComment" SG_ 1180 HVBatCellVlt_88 ".";
BA_ "GenSigSNA" SG_ 1181 HVBatCellVlt_89 "1FFFh";
BA_ "GenSigCycleTime" SG_ 1181 HVBatCellVlt_89 1000;
BA_ "FlexKomSigStartValue" SG_ 1181 HVBatCellVlt_89 "0000000000000000h";
BA_ "FlexKomSigStartPos" SG_ 1181 HVBatCellVlt_89 7;
BA_ "FlexKomSigName" SG_ 1181 HVBatCellVlt_89 "HybridRMS_CellVoltage23";
BA_ "FlexKomSigLaenge" SG_ 1181 HVBatCellVlt_89 64;
BA_ "FlexKomSID" SG_ 1181 HVBatCellVlt_89 2889;
BA_ "FlexKomIsMotorola" SG_ 1181 HVBatCellVlt_89 1;
BA_ "FlexKomComment" SG_ 1181 HVBatCellVlt_89 ".";
BA_ "GenSigSNA" SG_ 1181 HVBatCellVlt_90 "1FFFh";
BA_ "GenSigCycleTime" SG_ 1181 HVBatCellVlt_90 1000;
BA_ "FlexKomSigStartValue" SG_ 1181 HVBatCellVlt_90 "0000000000000000h";
BA_ "FlexKomSigStartPos" SG_ 1181 HVBatCellVlt_90 7;
BA_ "FlexKomSigName" SG_ 1181 HVBatCellVlt_90 "HybridRMS_CellVoltage23";
BA_ "FlexKomSigLaenge" SG_ 1181 HVBatCellVlt_90 64;
BA_ "FlexKomSID" SG_ 1181 HVBatCellVlt_90 2889;
BA_ "FlexKomIsMotorola" SG_ 1181 HVBatCellVlt_90 1;
BA_ "FlexKomComment" SG_ 1181 HVBatCellVlt_90 ".";
BA_ "GenSigSNA" SG_ 1181 HVBatCellVlt_91 "1FFFh";
BA_ "GenSigCycleTime" SG_ 1181 HVBatCellVlt_91 1000;
BA_ "FlexKomSigStartValue" SG_ 1181 HVBatCellVlt_91 "0000000000000000h";
BA_ "FlexKomSigStartPos" SG_ 1181 HVBatCellVlt_91 7;
BA_ "FlexKomSigName" SG_ 1181 HVBatCellVlt_91 "HybridRMS_CellVoltage23";
BA_ "FlexKomSigLaenge" SG_ 1181 HVBatCellVlt_91 64;
BA_ "FlexKomSID" SG_ 1181 HVBatCellVlt_91 2889;
BA_ "FlexKomIsMotorola" SG_ 1181 HVBatCellVlt_91 1;
BA_ "FlexKomComment" SG_ 1181 HVBatCellVlt_91 ".";
BA_ "GenSigSNA" SG_ 1181 HVBatCellVlt_92 "1FFFh";
BA_ "GenSigCycleTime" SG_ 1181 HVBatCellVlt_92 1000;
BA_ "FlexKomSigStartValue" SG_ 1181 HVBatCellVlt_92 "0000000000000000h";
BA_ "FlexKomSigStartPos" SG_ 1181 HVBatCellVlt_92 7;
BA_ "FlexKomSigName" SG_ 1181 HVBatCellVlt_92 "HybridRMS_CellVoltage23";
BA_ "FlexKomSigLaenge" SG_ 1181 HVBatCellVlt_92 64;
BA_ "FlexKomSID" SG_ 1181 HVBatCellVlt_92 2889;
BA_ "FlexKomIsMotorola" SG_ 1181 HVBatCellVlt_92 1;
BA_ "FlexKomComment" SG_ 1181 HVBatCellVlt_92 ".";
BA_ "GenSigSNA" SG_ 1182 HVBatCellVlt_93 "1FFFh";
BA_ "GenSigCycleTime" SG_ 1182 HVBatCellVlt_93 1000;
BA_ "FlexKomSigStartValue" SG_ 1182 HVBatCellVlt_93 "0000000000000000h";
BA_ "FlexKomSigStartPos" SG_ 1182 HVBatCellVlt_93 7;
BA_ "FlexKomSigName" SG_ 1182 HVBatCellVlt_93 "HybridRMS_CellVoltage24";
BA_ "FlexKomSigLaenge" SG_ 1182 HVBatCellVlt_93 64;
BA_ "FlexKomSID" SG_ 1182 HVBatCellVlt_93 2888;
BA_ "FlexKomIsMotorola" SG_ 1182 HVBatCellVlt_93 1;
BA_ "FlexKomComment" SG_ 1182 HVBatCellVlt_93 ".";
BA_ "GenSigSNA" SG_ 1182 HVBatCellVlt_94 "1FFFh";
BA_ "GenSigCycleTime" SG_ 1182 HVBatCellVlt_94 1000;
BA_ "FlexKomSigStartValue" SG_ 1182 HVBatCellVlt_94 "0000000000000000h";
BA_ "FlexKomSigStartPos" SG_ 1182 HVBatCellVlt_94 7;
BA_ "FlexKomSigName" SG_ 1182 HVBatCellVlt_94 "HybridRMS_CellVoltage24";
BA_ "FlexKomSigLaenge" SG_ 1182 HVBatCellVlt_94 64;
BA_ "FlexKomSID" SG_ 1182 HVBatCellVlt_94 2888;
BA_ "FlexKomIsMotorola" SG_ 1182 HVBatCellVlt_94 1;
BA_ "FlexKomComment" SG_ 1182 HVBatCellVlt_94 ".";
BA_ "GenSigSNA" SG_ 1182 HVBatCellVlt_95 "1FFFh";
BA_ "GenSigCycleTime" SG_ 1182 HVBatCellVlt_95 1000;
BA_ "FlexKomSigStartValue" SG_ 1182 HVBatCellVlt_95 "0000000000000000h";
BA_ "FlexKomSigStartPos" SG_ 1182 HVBatCellVlt_95 7;
BA_ "FlexKomSigName" SG_ 1182 HVBatCellVlt_95 "HybridRMS_CellVoltage24";
BA_ "FlexKomSigLaenge" SG_ 1182 HVBatCellVlt_95 64;
BA_ "FlexKomSID" SG_ 1182 HVBatCellVlt_95 2888;
BA_ "FlexKomIsMotorola" SG_ 1182 HVBatCellVlt_95 1;
BA_ "FlexKomComment" SG_ 1182 HVBatCellVlt_95 ".";
BA_ "GenSigSNA" SG_ 1182 HVBatCellVlt_96 "1FFFh";
BA_ "GenSigCycleTime" SG_ 1182 HVBatCellVlt_96 1000;
BA_ "FlexKomSigStartValue" SG_ 1182 HVBatCellVlt_96 "0000000000000000h";
BA_ "FlexKomSigStartPos" SG_ 1182 HVBatCellVlt_96 7;
BA_ "FlexKomSigName" SG_ 1182 HVBatCellVlt_96 "HybridRMS_CellVoltage24";
BA_ "FlexKomSigLaenge" SG_ 1182 HVBatCellVlt_96 64;
BA_ "FlexKomSID" SG_ 1182 HVBatCellVlt_96 2888;
BA_ "FlexKomIsMotorola" SG_ 1182 HVBatCellVlt_96 1;
BA_ "FlexKomComment" SG_ 1182 HVBatCellVlt_96 ".";
BA_ "GenSigSNA" SG_ 1183 HVBatCellVltMax "1FFFh";
BA_ "GenSigCycleTime" SG_ 1183 HVBatCellVltMax 1000;
BA_ "FlexKomSigStartValue" SG_ 1183 HVBatCellVltMax "000000000000h";
BA_ "FlexKomSigStartPos" SG_ 1183 HVBatCellVltMax 7;
BA_ "FlexKomSigName" SG_ 1183 HVBatCellVltMax "HybridRMS_CellVoltage25";
BA_ "FlexKomSigLaenge" SG_ 1183 HVBatCellVltMax 48;
BA_ "FlexKomSID" SG_ 1183 HVBatCellVltMax 2914;
BA_ "FlexKomIsMotorola" SG_ 1183 HVBatCellVltMax 1;
BA_ "FlexKomComment" SG_ 1183 HVBatCellVltMax ".";
BA_ "GenSigSNA" SG_ 1183 HVBatCellVltMin "1FFFh";
BA_ "GenSigCycleTime" SG_ 1183 HVBatCellVltMin 1000;
BA_ "FlexKomSigStartValue" SG_ 1183 HVBatCellVltMin "000000000000h";
BA_ "FlexKomSigStartPos" SG_ 1183 HVBatCellVltMin 7;
BA_ "FlexKomSigName" SG_ 1183 HVBatCellVltMin "HybridRMS_CellVoltage25";
BA_ "FlexKomSigLaenge" SG_ 1183 HVBatCellVltMin 48;
BA_ "FlexKomSID" SG_ 1183 HVBatCellVltMin 2914;
BA_ "FlexKomIsMotorola" SG_ 1183 HVBatCellVltMin 1;
BA_ "FlexKomComment" SG_ 1183 HVBatCellVltMin ".";
BA_ "GenSigSNA" SG_ 1183 HVBatMod_NumMaxVlt "0h";
BA_ "GenSigCycleTime" SG_ 1183 HVBatMod_NumMaxVlt 1000;
BA_ "FlexKomSigStartValue" SG_ 1183 HVBatMod_NumMaxVlt "000000000000h";
BA_ "FlexKomSigStartPos" SG_ 1183 HVBatMod_NumMaxVlt 7;
BA_ "FlexKomSigName" SG_ 1183 HVBatMod_NumMaxVlt "HybridRMS_CellVoltage25";
BA_ "FlexKomSigLaenge" SG_ 1183 HVBatMod_NumMaxVlt 48;
BA_ "FlexKomSID" SG_ 1183 HVBatMod_NumMaxVlt 2914;
BA_ "FlexKomIsMotorola" SG_ 1183 HVBatMod_NumMaxVlt 1;
BA_ "FlexKomComment" SG_ 1183 HVBatMod_NumMaxVlt ".";
BA_ "GenSigSNA" SG_ 1183 HVBatMod_NumMinVlt "0h";
BA_ "GenSigCycleTime" SG_ 1183 HVBatMod_NumMinVlt 1000;
BA_ "FlexKomSigStartValue" SG_ 1183 HVBatMod_NumMinVlt "000000000000h";
BA_ "FlexKomSigStartPos" SG_ 1183 HVBatMod_NumMinVlt 7;
BA_ "FlexKomSigName" SG_ 1183 HVBatMod_NumMinVlt "HybridRMS_CellVoltage25";
BA_ "FlexKomSigLaenge" SG_ 1183 HVBatMod_NumMinVlt 48;
BA_ "FlexKomSID" SG_ 1183 HVBatMod_NumMinVlt 2914;
BA_ "FlexKomIsMotorola" SG_ 1183 HVBatMod_NumMinVlt 1;
BA_ "FlexKomComment" SG_ 1183 HVBatMod_NumMinVlt ".";
BA_ "GenSigSNA" SG_ 1156 ACSideCurr "3FFh";
BA_ "GenSigCycleTime" SG_ 1156 ACSideCurr 1000;
BA_ "FlexKomSigStartValue" SG_ 1156 ACSideCurr "0000000000000000h";
BA_ "FlexKomSigStartPos" SG_ 1156 ACSideCurr 7;
BA_ "FlexKomSigName" SG_ 1156 ACSideCurr "HybridRMS_Charging_PKT";
BA_ "FlexKomSigLaenge" SG_ 1156 ACSideCurr 64;
BA_ "FlexKomSID" SG_ 1156 ACSideCurr 2913;
BA_ "FlexKomIsMotorola" SG_ 1156 ACSideCurr 1;
BA_ "FlexKomComment" SG_ 1156 ACSideCurr ".";
BA_ "GenSigSNA" SG_ 1156 ACSideVolt "FFFh";
BA_ "GenSigCycleTime" SG_ 1156 ACSideVolt 1000;
BA_ "FlexKomSigStartValue" SG_ 1156 ACSideVolt "0000000000000000h";
BA_ "FlexKomSigStartPos" SG_ 1156 ACSideVolt 7;
BA_ "FlexKomSigName" SG_ 1156 ACSideVolt "HybridRMS_Charging_PKT";
BA_ "FlexKomSigLaenge" SG_ 1156 ACSideVolt 64;
BA_ "FlexKomSID" SG_ 1156 ACSideVolt 2913;
BA_ "FlexKomIsMotorola" SG_ 1156 ACSideVolt 1;
BA_ "FlexKomComment" SG_ 1156 ACSideVolt ".";
BA_ "GenSigSNA" SG_ 1156 APM_FailureReason "3Fh";
BA_ "GenSigCycleTime" SG_ 1156 APM_FailureReason 1000;
BA_ "FlexKomSigStartValue" SG_ 1156 APM_FailureReason "0000000000000000h";
BA_ "FlexKomSigStartPos" SG_ 1156 APM_FailureReason 7;
BA_ "FlexKomSigName" SG_ 1156 APM_FailureReason "HybridRMS_Charging_PKT";
BA_ "FlexKomSigLaenge" SG_ 1156 APM_FailureReason 64;
BA_ "FlexKomSID" SG_ 1156 APM_FailureReason 2913;
BA_ "FlexKomIsMotorola" SG_ 1156 APM_FailureReason 1;
BA_ "FlexKomComment" SG_ 1156 APM_FailureReason ".";
BA_ "GenSigSNA" SG_ 1156 APM_OperModeStatus "Fh";
BA_ "GenSigCycleTime" SG_ 1156 APM_OperModeStatus 1000;
BA_ "FlexKomSigStartValue" SG_ 1156 APM_OperModeStatus "0000000000000000h";
BA_ "FlexKomSigStartPos" SG_ 1156 APM_OperModeStatus 7;
BA_ "FlexKomSigName" SG_ 1156 APM_OperModeStatus "HybridRMS_Charging_PKT";
BA_ "FlexKomSigLaenge" SG_ 1156 APM_OperModeStatus 64;
BA_ "FlexKomSID" SG_ 1156 APM_OperModeStatus 2913;
BA_ "FlexKomIsMotorola" SG_ 1156 APM_OperModeStatus 1;
BA_ "FlexKomComment" SG_ 1156 APM_OperModeStatus ".";
BA_ "GenSigSNA" SG_ 1156 APM_OutputPower "3FFh";
BA_ "GenSigCycleTime" SG_ 1156 APM_OutputPower 1000;
BA_ "FlexKomSigStartValue" SG_ 1156 APM_OutputPower "0000000000000000h";
BA_ "FlexKomSigStartPos" SG_ 1156 APM_OutputPower 7;
BA_ "FlexKomSigName" SG_ 1156 APM_OutputPower "HybridRMS_Charging_PKT";
BA_ "FlexKomSigLaenge" SG_ 1156 APM_OutputPower 64;
BA_ "FlexKomSID" SG_ 1156 APM_OutputPower 2913;
BA_ "FlexKomIsMotorola" SG_ 1156 APM_OutputPower 1;
BA_ "FlexKomComment" SG_ 1156 APM_OutputPower ".";
BA_ "GenSigSNA" SG_ 1156 IsolationResistance "FFFFh";
BA_ "GenSigCycleTime" SG_ 1156 IsolationResistance 1000;
BA_ "FlexKomSigStartValue" SG_ 1156 IsolationResistance "0000000000000000h";
BA_ "FlexKomSigStartPos" SG_ 1156 IsolationResistance 7;
BA_ "FlexKomSigName" SG_ 1156 IsolationResistance "HybridRMS_Charging_PKT";
BA_ "FlexKomSigLaenge" SG_ 1156 IsolationResistance 64;
BA_ "FlexKomSID" SG_ 1156 IsolationResistance 2913;
BA_ "FlexKomIsMotorola" SG_ 1156 IsolationResistance 1;
BA_ "FlexKomComment" SG_ 1156 IsolationResistance ".";
BA_ "GenSigStartValue" SG_ 1152 MtrA_RPM 32768;
BA_ "GenSigSNA" SG_ 1152 MtrA_RPM "8000h";
BA_ "GenSigCycleTime" SG_ 1152 MtrA_RPM 1000;
BA_ "FlexKomSigStartValue" SG_ 1152 MtrA_RPM "800010002800h";
BA_ "FlexKomSigStartPos" SG_ 1152 MtrA_RPM 7;
BA_ "FlexKomSigName" SG_ 1152 MtrA_RPM "HybridRMS_MotorA_1_PKT";
BA_ "FlexKomSigLaenge" SG_ 1152 MtrA_RPM 48;
BA_ "FlexKomSID" SG_ 1152 MtrA_RPM 2886;
BA_ "FlexKomIsMotorola" SG_ 1152 MtrA_RPM 1;
BA_ "FlexKomComment" SG_ 1152 MtrA_RPM ".";
BA_ "GenSigStartValue" SG_ 1152 MtrA_Temp 40;
BA_ "GenSigSNA" SG_ 1152 MtrA_Temp "28h";
BA_ "GenSigCycleTime" SG_ 1152 MtrA_Temp 1000;
BA_ "FlexKomSigStartValue" SG_ 1152 MtrA_Temp "800010002800h";
BA_ "FlexKomSigStartPos" SG_ 1152 MtrA_Temp 7;
BA_ "FlexKomSigName" SG_ 1152 MtrA_Temp "HybridRMS_MotorA_1_PKT";
BA_ "FlexKomSigLaenge" SG_ 1152 MtrA_Temp 48;
BA_ "FlexKomSID" SG_ 1152 MtrA_Temp 2886;
BA_ "FlexKomIsMotorola" SG_ 1152 MtrA_Temp 1;
BA_ "FlexKomComment" SG_ 1152 MtrA_Temp ".";
BA_ "GenSigStartValue" SG_ 1152 MtrA_TorqAchieved 4096;
BA_ "GenSigSNA" SG_ 1152 MtrA_TorqAchieved "1000h";
BA_ "GenSigCycleTime" SG_ 1152 MtrA_TorqAchieved 1000;
BA_ "FlexKomSigStartValue" SG_ 1152 MtrA_TorqAchieved "800010002800h";
BA_ "FlexKomSigStartPos" SG_ 1152 MtrA_TorqAchieved 7;
BA_ "FlexKomSigName" SG_ 1152 MtrA_TorqAchieved "HybridRMS_MotorA_1_PKT";
BA_ "FlexKomSigLaenge" SG_ 1152 MtrA_TorqAchieved 48;
BA_ "FlexKomSID" SG_ 1152 MtrA_TorqAchieved 2886;
BA_ "FlexKomIsMotorola" SG_ 1152 MtrA_TorqAchieved 1;
BA_ "FlexKomComment" SG_ 1152 MtrA_TorqAchieved ".";
BA_ "GenSigStartValue" SG_ 1153 MtrA_DC_Crnt 16384;
BA_ "GenSigSNA" SG_ 1153 MtrA_DC_Crnt "4000h";
BA_ "GenSigCycleTime" SG_ 1153 MtrA_DC_Crnt 1000;
BA_ "FlexKomSigStartValue" SG_ 1153 MtrA_DC_Crnt "400000002800h";
BA_ "FlexKomSigStartPos" SG_ 1153 MtrA_DC_Crnt 7;
BA_ "FlexKomSigName" SG_ 1153 MtrA_DC_Crnt "HybridRMS_MotorA_2_PKT";
BA_ "FlexKomSigLaenge" SG_ 1153 MtrA_DC_Crnt 48;
BA_ "FlexKomSID" SG_ 1153 MtrA_DC_Crnt 2884;
BA_ "FlexKomIsMotorola" SG_ 1153 MtrA_DC_Crnt 1;
BA_ "FlexKomComment" SG_ 1153 MtrA_DC_Crnt ".";
BA_ "GenSigSNA" SG_ 1153 MtrA_DC_Volt "0h";
BA_ "GenSigCycleTime" SG_ 1153 MtrA_DC_Volt 1000;
BA_ "FlexKomSigStartValue" SG_ 1153 MtrA_DC_Volt "400000002800h";
BA_ "FlexKomSigStartPos" SG_ 1153 MtrA_DC_Volt 7;
BA_ "FlexKomSigName" SG_ 1153 MtrA_DC_Volt "HybridRMS_MotorA_2_PKT";
BA_ "FlexKomSigLaenge" SG_ 1153 MtrA_DC_Volt 48;
BA_ "FlexKomSID" SG_ 1153 MtrA_DC_Volt 2884;
BA_ "FlexKomIsMotorola" SG_ 1153 MtrA_DC_Volt 1;
BA_ "FlexKomComment" SG_ 1153 MtrA_DC_Volt ".";
BA_ "GenSigStartValue" SG_ 1153 MtrA_InvrtrTemp 40;
BA_ "GenSigSNA" SG_ 1153 MtrA_InvrtrTemp "28h";
BA_ "GenSigCycleTime" SG_ 1153 MtrA_InvrtrTemp 1000;
BA_ "FlexKomSigStartValue" SG_ 1153 MtrA_InvrtrTemp "400000002800h";
BA_ "FlexKomSigStartPos" SG_ 1153 MtrA_InvrtrTemp 7;
BA_ "FlexKomSigName" SG_ 1153 MtrA_InvrtrTemp "HybridRMS_MotorA_2_PKT";
BA_ "FlexKomSigLaenge" SG_ 1153 MtrA_InvrtrTemp 48;
BA_ "FlexKomSID" SG_ 1153 MtrA_InvrtrTemp 2884;
BA_ "FlexKomIsMotorola" SG_ 1153 MtrA_InvrtrTemp 1;
BA_ "FlexKomComment" SG_ 1153 MtrA_InvrtrTemp ".";
BA_ "GenSigSNA" SG_ 1153 MtrA_Invrtr_State "0h";
BA_ "GenSigCycleTime" SG_ 1153 MtrA_Invrtr_State 1000;
BA_ "FlexKomSigStartValue" SG_ 1153 MtrA_Invrtr_State "400000002800h";
BA_ "FlexKomSigStartPos" SG_ 1153 MtrA_Invrtr_State 7;
BA_ "FlexKomSigName" SG_ 1153 MtrA_Invrtr_State "HybridRMS_MotorA_2_PKT";
BA_ "FlexKomSigLaenge" SG_ 1153 MtrA_Invrtr_State 48;
BA_ "FlexKomSID" SG_ 1153 MtrA_Invrtr_State 2884;
BA_ "FlexKomIsMotorola" SG_ 1153 MtrA_Invrtr_State 1;
BA_ "FlexKomComment" SG_ 1153 MtrA_Invrtr_State ".";
BA_ "GenSigStartValue" SG_ 1154 MtrB_RPM 32768;
BA_ "GenSigSNA" SG_ 1154 MtrB_RPM "8000h";
BA_ "GenSigCycleTime" SG_ 1154 MtrB_RPM 1000;
BA_ "FlexKomSigStartValue" SG_ 1154 MtrB_RPM "800010002800h";
BA_ "FlexKomSigStartPos" SG_ 1154 MtrB_RPM 7;
BA_ "FlexKomSigName" SG_ 1154 MtrB_RPM "HybridRMS_MotorB_1_PKT";
BA_ "FlexKomSigLaenge" SG_ 1154 MtrB_RPM 48;
BA_ "FlexKomSID" SG_ 1154 MtrB_RPM 2885;
BA_ "FlexKomIsMotorola" SG_ 1154 MtrB_RPM 1;
BA_ "FlexKomComment" SG_ 1154 MtrB_RPM ".";
BA_ "GenSigStartValue" SG_ 1154 MtrB_Temp 40;
BA_ "GenSigSNA" SG_ 1154 MtrB_Temp "28h";
BA_ "GenSigCycleTime" SG_ 1154 MtrB_Temp 1000;
BA_ "FlexKomSigStartValue" SG_ 1154 MtrB_Temp "800010002800h";
BA_ "FlexKomSigStartPos" SG_ 1154 MtrB_Temp 7;
BA_ "FlexKomSigName" SG_ 1154 MtrB_Temp "HybridRMS_MotorB_1_PKT";
BA_ "FlexKomSigLaenge" SG_ 1154 MtrB_Temp 48;
BA_ "FlexKomSID" SG_ 1154 MtrB_Temp 2885;
BA_ "FlexKomIsMotorola" SG_ 1154 MtrB_Temp 1;
BA_ "FlexKomComment" SG_ 1154 MtrB_Temp ".";
BA_ "GenSigStartValue" SG_ 1154 MtrB_TorqAchieved 4096;
BA_ "GenSigSNA" SG_ 1154 MtrB_TorqAchieved "1000h";
BA_ "GenSigCycleTime" SG_ 1154 MtrB_TorqAchieved 1000;
BA_ "FlexKomSigStartValue" SG_ 1154 MtrB_TorqAchieved "800010002800h";
BA_ "FlexKomSigStartPos" SG_ 1154 MtrB_TorqAchieved 7;
BA_ "FlexKomSigName" SG_ 1154 MtrB_TorqAchieved "HybridRMS_MotorB_1_PKT";
BA_ "FlexKomSigLaenge" SG_ 1154 MtrB_TorqAchieved 48;
BA_ "FlexKomSID" SG_ 1154 MtrB_TorqAchieved 2885;
BA_ "FlexKomIsMotorola" SG_ 1154 MtrB_TorqAchieved 1;
BA_ "FlexKomComment" SG_ 1154 MtrB_TorqAchieved ".";
BA_ "GenSigStartValue" SG_ 1155 MtrB_DC_Crnt 16384;
BA_ "GenSigSNA" SG_ 1155 MtrB_DC_Crnt "4000h";
BA_ "GenSigCycleTime" SG_ 1155 MtrB_DC_Crnt 1000;
BA_ "FlexKomSigStartValue" SG_ 1155 MtrB_DC_Crnt "400000002800h";
BA_ "FlexKomSigStartPos" SG_ 1155 MtrB_DC_Crnt 7;
BA_ "FlexKomSigName" SG_ 1155 MtrB_DC_Crnt "HybridRMS_MotorB_2_PKT";
BA_ "FlexKomSigLaenge" SG_ 1155 MtrB_DC_Crnt 48;
BA_ "FlexKomSID" SG_ 1155 MtrB_DC_Crnt 2883;
BA_ "FlexKomIsMotorola" SG_ 1155 MtrB_DC_Crnt 1;
BA_ "FlexKomComment" SG_ 1155 MtrB_DC_Crnt ".";
BA_ "GenSigSNA" SG_ 1155 MtrB_DC_Volt "0h";
BA_ "GenSigCycleTime" SG_ 1155 MtrB_DC_Volt 1000;
BA_ "FlexKomSigStartValue" SG_ 1155 MtrB_DC_Volt "400000002800h";
BA_ "FlexKomSigStartPos" SG_ 1155 MtrB_DC_Volt 7;
BA_ "FlexKomSigName" SG_ 1155 MtrB_DC_Volt "HybridRMS_MotorB_2_PKT";
BA_ "FlexKomSigLaenge" SG_ 1155 MtrB_DC_Volt 48;
BA_ "FlexKomSID" SG_ 1155 MtrB_DC_Volt 2883;
BA_ "FlexKomIsMotorola" SG_ 1155 MtrB_DC_Volt 1;
BA_ "FlexKomComment" SG_ 1155 MtrB_DC_Volt ".";
BA_ "GenSigStartValue" SG_ 1155 MtrB_InvrtrTemp 40;
BA_ "GenSigSNA" SG_ 1155 MtrB_InvrtrTemp "28h";
BA_ "GenSigCycleTime" SG_ 1155 MtrB_InvrtrTemp 1000;
BA_ "FlexKomSigStartValue" SG_ 1155 MtrB_InvrtrTemp "400000002800h";
BA_ "FlexKomSigStartPos" SG_ 1155 MtrB_InvrtrTemp 7;
BA_ "FlexKomSigName" SG_ 1155 MtrB_InvrtrTemp "HybridRMS_MotorB_2_PKT";
BA_ "FlexKomSigLaenge" SG_ 1155 MtrB_InvrtrTemp 48;
BA_ "FlexKomSID" SG_ 1155 MtrB_InvrtrTemp 2883;
BA_ "FlexKomIsMotorola" SG_ 1155 MtrB_InvrtrTemp 1;
BA_ "FlexKomComment" SG_ 1155 MtrB_InvrtrTemp ".";
BA_ "GenSigSNA" SG_ 1155 MtrB_Invrtr_State "0h";
BA_ "GenSigCycleTime" SG_ 1155 MtrB_Invrtr_State 1000;
BA_ "FlexKomSigStartValue" SG_ 1155 MtrB_Invrtr_State "400000002800h";
BA_ "FlexKomSigStartPos" SG_ 1155 MtrB_Invrtr_State 7;
BA_ "FlexKomSigName" SG_ 1155 MtrB_Invrtr_State "HybridRMS_MotorB_2_PKT";
BA_ "FlexKomSigLaenge" SG_ 1155 MtrB_Invrtr_State 48;
BA_ "FlexKomSID" SG_ 1155 MtrB_Invrtr_State 2883;
BA_ "FlexKomIsMotorola" SG_ 1155 MtrB_Invrtr_State 1;
BA_ "FlexKomComment" SG_ 1155 MtrB_Invrtr_State ".";
BA_ "GenSigSNA" SG_ 1158 APMPerfWrn "0h";
BA_ "GenSigCycleTime" SG_ 1158 APMPerfWrn 1000;
BA_ "FlexKomSigStartValue" SG_ 1158 APMPerfWrn "0000000000000000h";
BA_ "FlexKomSigStartPos" SG_ 1158 APMPerfWrn 7;
BA_ "FlexKomSigName" SG_ 1158 APMPerfWrn "HybridRMS_Warnings_PKT";
BA_ "FlexKomSigLaenge" SG_ 1158 APMPerfWrn 64;
BA_ "FlexKomSID" SG_ 1158 APMPerfWrn 2878;
BA_ "FlexKomIsMotorola" SG_ 1158 APMPerfWrn 1;
BA_ "FlexKomComment" SG_ 1158 APMPerfWrn ".";
BA_ "GenSigSNA" SG_ 1158 APMTempWrn "0h";
BA_ "GenSigCycleTime" SG_ 1158 APMTempWrn 1000;
BA_ "FlexKomSigStartValue" SG_ 1158 APMTempWrn "0000000000000000h";
BA_ "FlexKomSigStartPos" SG_ 1158 APMTempWrn 7;
BA_ "FlexKomSigName" SG_ 1158 APMTempWrn "HybridRMS_Warnings_PKT";
BA_ "FlexKomSigLaenge" SG_ 1158 APMTempWrn 64;
BA_ "FlexKomSID" SG_ 1158 APMTempWrn 2878;
BA_ "FlexKomIsMotorola" SG_ 1158 APMTempWrn 1;
BA_ "FlexKomComment" SG_ 1158 APMTempWrn ".";
BA_ "GenSigSNA" SG_ 1158 BPCMCellBalWrn "0h";
BA_ "GenSigCycleTime" SG_ 1158 BPCMCellBalWrn 1000;
BA_ "FlexKomSigStartValue" SG_ 1158 BPCMCellBalWrn "0000000000000000h";
BA_ "FlexKomSigStartPos" SG_ 1158 BPCMCellBalWrn 7;
BA_ "FlexKomSigName" SG_ 1158 BPCMCellBalWrn "HybridRMS_Warnings_PKT";
BA_ "FlexKomSigLaenge" SG_ 1158 BPCMCellBalWrn 64;
BA_ "FlexKomSID" SG_ 1158 BPCMCellBalWrn 2878;
BA_ "FlexKomIsMotorola" SG_ 1158 BPCMCellBalWrn 1;
BA_ "FlexKomComment" SG_ 1158 BPCMCellBalWrn ".";
BA_ "GenSigSNA" SG_ 1158 BPCMCellOverWrn "0h";
BA_ "GenSigCycleTime" SG_ 1158 BPCMCellOverWrn 1000;
BA_ "FlexKomSigStartValue" SG_ 1158 BPCMCellOverWrn "0000000000000000h";
BA_ "FlexKomSigStartPos" SG_ 1158 BPCMCellOverWrn 7;
BA_ "FlexKomSigName" SG_ 1158 BPCMCellOverWrn "HybridRMS_Warnings_PKT";
BA_ "FlexKomSigLaenge" SG_ 1158 BPCMCellOverWrn 64;
BA_ "FlexKomSID" SG_ 1158 BPCMCellOverWrn 2878;
BA_ "FlexKomIsMotorola" SG_ 1158 BPCMCellOverWrn 1;
BA_ "FlexKomComment" SG_ 1158 BPCMCellOverWrn ".";
BA_ "GenSigSNA" SG_ 1158 BPCMCellUnderWrn "0h";
BA_ "GenSigCycleTime" SG_ 1158 BPCMCellUnderWrn 1000;
BA_ "FlexKomSigStartValue" SG_ 1158 BPCMCellUnderWrn "0000000000000000h";
BA_ "FlexKomSigStartPos" SG_ 1158 BPCMCellUnderWrn 7;
BA_ "FlexKomSigName" SG_ 1158 BPCMCellUnderWrn "HybridRMS_Warnings_PKT";
BA_ "FlexKomSigLaenge" SG_ 1158 BPCMCellUnderWrn 64;
BA_ "FlexKomSID" SG_ 1158 BPCMCellUnderWrn 2878;
BA_ "FlexKomIsMotorola" SG_ 1158 BPCMCellUnderWrn 1;
BA_ "FlexKomComment" SG_ 1158 BPCMCellUnderWrn ".";
BA_ "GenSigSNA" SG_ 1158 BPCMHighSOCWrn "0h";
BA_ "GenSigCycleTime" SG_ 1158 BPCMHighSOCWrn 1000;
BA_ "FlexKomSigStartValue" SG_ 1158 BPCMHighSOCWrn "0000000000000000h";
BA_ "FlexKomSigStartPos" SG_ 1158 BPCMHighSOCWrn 7;
BA_ "FlexKomSigName" SG_ 1158 BPCMHighSOCWrn "HybridRMS_Warnings_PKT";
BA_ "FlexKomSigLaenge" SG_ 1158 BPCMHighSOCWrn 64;
BA_ "FlexKomSID" SG_ 1158 BPCMHighSOCWrn 2878;
BA_ "FlexKomIsMotorola" SG_ 1158 BPCMHighSOCWrn 1;
BA_ "FlexKomComment" SG_ 1158 BPCMHighSOCWrn ".";
BA_ "GenSigSNA" SG_ 1158 BPCMInsulWrn "0h";
BA_ "GenSigCycleTime" SG_ 1158 BPCMInsulWrn 1000;
BA_ "FlexKomSigStartValue" SG_ 1158 BPCMInsulWrn "0000000000000000h";
BA_ "FlexKomSigStartPos" SG_ 1158 BPCMInsulWrn 7;
BA_ "FlexKomSigName" SG_ 1158 BPCMInsulWrn "HybridRMS_Warnings_PKT";
BA_ "FlexKomSigLaenge" SG_ 1158 BPCMInsulWrn 64;
BA_ "FlexKomSID" SG_ 1158 BPCMInsulWrn 2878;
BA_ "FlexKomIsMotorola" SG_ 1158 BPCMInsulWrn 1;
BA_ "FlexKomComment" SG_ 1158 BPCMInsulWrn ".";
BA_ "GenSigSNA" SG_ 1158 BPCMMaxTempWrn "0h";
BA_ "GenSigCycleTime" SG_ 1158 BPCMMaxTempWrn 1000;
BA_ "FlexKomSigStartValue" SG_ 1158 BPCMMaxTempWrn "0000000000000000h";
BA_ "FlexKomSigStartPos" SG_ 1158 BPCMMaxTempWrn 7;
BA_ "FlexKomSigName" SG_ 1158 BPCMMaxTempWrn "HybridRMS_Warnings_PKT";
BA_ "FlexKomSigLaenge" SG_ 1158 BPCMMaxTempWrn 64;
BA_ "FlexKomSID" SG_ 1158 BPCMMaxTempWrn 2878;
BA_ "FlexKomIsMotorola" SG_ 1158 BPCMMaxTempWrn 1;
BA_ "FlexKomComment" SG_ 1158 BPCMMaxTempWrn ".";
BA_ "GenSigSNA" SG_ 1158 BPCMOverChrgWrn "0h";
BA_ "GenSigCycleTime" SG_ 1158 BPCMOverChrgWrn 1000;
BA_ "FlexKomSigStartValue" SG_ 1158 BPCMOverChrgWrn "0000000000000000h";
BA_ "FlexKomSigStartPos" SG_ 1158 BPCMOverChrgWrn 7;
BA_ "FlexKomSigName" SG_ 1158 BPCMOverChrgWrn "HybridRMS_Warnings_PKT";
BA_ "FlexKomSigLaenge" SG_ 1158 BPCMOverChrgWrn 64;
BA_ "FlexKomSID" SG_ 1158 BPCMOverChrgWrn 2878;
BA_ "FlexKomIsMotorola" SG_ 1158 BPCMOverChrgWrn 1;
BA_ "FlexKomComment" SG_ 1158 BPCMOverChrgWrn ".";
BA_ "GenSigSNA" SG_ 1158 BPCMOverVoltWrn "0h";
BA_ "GenSigCycleTime" SG_ 1158 BPCMOverVoltWrn 1000;
BA_ "FlexKomSigStartValue" SG_ 1158 BPCMOverVoltWrn "0000000000000000h";
BA_ "FlexKomSigStartPos" SG_ 1158 BPCMOverVoltWrn 7;
BA_ "FlexKomSigName" SG_ 1158 BPCMOverVoltWrn "HybridRMS_Warnings_PKT";
BA_ "FlexKomSigLaenge" SG_ 1158 BPCMOverVoltWrn 64;
BA_ "FlexKomSID" SG_ 1158 BPCMOverVoltWrn 2878;
BA_ "FlexKomIsMotorola" SG_ 1158 BPCMOverVoltWrn 1;
BA_ "FlexKomComment" SG_ 1158 BPCMOverVoltWrn ".";
BA_ "GenSigSNA" SG_ 1158 BPCMSOCJumpWrn "0h";
BA_ "GenSigCycleTime" SG_ 1158 BPCMSOCJumpWrn 1000;
BA_ "FlexKomSigStartValue" SG_ 1158 BPCMSOCJumpWrn "0000000000000000h";
BA_ "FlexKomSigStartPos" SG_ 1158 BPCMSOCJumpWrn 7;
BA_ "FlexKomSigName" SG_ 1158 BPCMSOCJumpWrn "HybridRMS_Warnings_PKT";
BA_ "FlexKomSigLaenge" SG_ 1158 BPCMSOCJumpWrn 64;
BA_ "FlexKomSID" SG_ 1158 BPCMSOCJumpWrn 2878;
BA_ "FlexKomIsMotorola" SG_ 1158 BPCMSOCJumpWrn 1;
BA_ "FlexKomComment" SG_ 1158 BPCMSOCJumpWrn ".";
BA_ "GenSigSNA" SG_ 1158 BPCMSOCLowWrn "0h";
BA_ "GenSigCycleTime" SG_ 1158 BPCMSOCLowWrn 1000;
BA_ "FlexKomSigStartValue" SG_ 1158 BPCMSOCLowWrn "0000000000000000h";
BA_ "FlexKomSigStartPos" SG_ 1158 BPCMSOCLowWrn 7;
BA_ "FlexKomSigName" SG_ 1158 BPCMSOCLowWrn "HybridRMS_Warnings_PKT";
BA_ "FlexKomSigLaenge" SG_ 1158 BPCMSOCLowWrn 64;
BA_ "FlexKomSID" SG_ 1158 BPCMSOCLowWrn 2878;
BA_ "FlexKomIsMotorola" SG_ 1158 BPCMSOCLowWrn 1;
BA_ "FlexKomComment" SG_ 1158 BPCMSOCLowWrn ".";
BA_ "GenSigSNA" SG_ 1158 BPCMTempDiffWrn "0h";
BA_ "GenSigCycleTime" SG_ 1158 BPCMTempDiffWrn 1000;
BA_ "FlexKomSigStartValue" SG_ 1158 BPCMTempDiffWrn "0000000000000000h";
BA_ "FlexKomSigStartPos" SG_ 1158 BPCMTempDiffWrn 7;
BA_ "FlexKomSigName" SG_ 1158 BPCMTempDiffWrn "HybridRMS_Warnings_PKT";
BA_ "FlexKomSigLaenge" SG_ 1158 BPCMTempDiffWrn 64;
BA_ "FlexKomSID" SG_ 1158 BPCMTempDiffWrn 2878;
BA_ "FlexKomIsMotorola" SG_ 1158 BPCMTempDiffWrn 1;
BA_ "FlexKomComment" SG_ 1158 BPCMTempDiffWrn ".";
BA_ "GenSigSNA" SG_ 1158 BPCMUnderVoltWrn "0h";
BA_ "GenSigCycleTime" SG_ 1158 BPCMUnderVoltWrn 1000;
BA_ "FlexKomSigStartValue" SG_ 1158 BPCMUnderVoltWrn "0000000000000000h";
BA_ "FlexKomSigStartPos" SG_ 1158 BPCMUnderVoltWrn 7;
BA_ "FlexKomSigName" SG_ 1158 BPCMUnderVoltWrn "HybridRMS_Warnings_PKT";
BA_ "FlexKomSigLaenge" SG_ 1158 BPCMUnderVoltWrn 64;
BA_ "FlexKomSID" SG_ 1158 BPCMUnderVoltWrn 2878;
BA_ "FlexKomIsMotorola" SG_ 1158 BPCMUnderVoltWrn 1;
BA_ "FlexKomComment" SG_ 1158 BPCMUnderVoltWrn ".";
BA_ "GenSigSNA" SG_ 1158 BPCMUnmatchedWrn "0h";
BA_ "GenSigCycleTime" SG_ 1158 BPCMUnmatchedWrn 1000;
BA_ "FlexKomSigStartValue" SG_ 1158 BPCMUnmatchedWrn "0000000000000000h";
BA_ "FlexKomSigStartPos" SG_ 1158 BPCMUnmatchedWrn 7;
BA_ "FlexKomSigName" SG_ 1158 BPCMUnmatchedWrn "HybridRMS_Warnings_PKT";
BA_ "FlexKomSigLaenge" SG_ 1158 BPCMUnmatchedWrn 64;
BA_ "FlexKomSID" SG_ 1158 BPCMUnmatchedWrn 2878;
BA_ "FlexKomIsMotorola" SG_ 1158 BPCMUnmatchedWrn 1;
BA_ "FlexKomComment" SG_ 1158 BPCMUnmatchedWrn ".";
BA_ "GenSigSNA" SG_ 1158 HVILWrn "0h";
BA_ "GenSigCycleTime" SG_ 1158 HVILWrn 1000;
BA_ "FlexKomSigStartValue" SG_ 1158 HVILWrn "0000000000000000h";
BA_ "FlexKomSigStartPos" SG_ 1158 HVILWrn 7;
BA_ "FlexKomSigName" SG_ 1158 HVILWrn "HybridRMS_Warnings_PKT";
BA_ "FlexKomSigLaenge" SG_ 1158 HVILWrn 64;
BA_ "FlexKomSID" SG_ 1158 HVILWrn 2878;
BA_ "FlexKomIsMotorola" SG_ 1158 HVILWrn 1;
BA_ "FlexKomComment" SG_ 1158 HVILWrn ".";
BA_ "GenSigSNA" SG_ 1158 HighestWarnLevel "0h";
BA_ "GenSigCycleTime" SG_ 1158 HighestWarnLevel 1000;
BA_ "FlexKomSigStartValue" SG_ 1158 HighestWarnLevel "0000000000000000h";
BA_ "FlexKomSigStartPos" SG_ 1158 HighestWarnLevel 7;
BA_ "FlexKomSigName" SG_ 1158 HighestWarnLevel "HybridRMS_Warnings_PKT";
BA_ "FlexKomSigLaenge" SG_ 1158 HighestWarnLevel 64;
BA_ "FlexKomSID" SG_ 1158 HighestWarnLevel 2878;
BA_ "FlexKomIsMotorola" SG_ 1158 HighestWarnLevel 1;
BA_ "FlexKomComment" SG_ 1158 HighestWarnLevel ".";
BA_ "GenSigSNA" SG_ 1158 MtrA_InvOverTempWrn "0h";
BA_ "GenSigCycleTime" SG_ 1158 MtrA_InvOverTempWrn 1000;
BA_ "FlexKomSigStartValue" SG_ 1158 MtrA_InvOverTempWrn "0000000000000000h";
BA_ "FlexKomSigStartPos" SG_ 1158 MtrA_InvOverTempWrn 7;
BA_ "FlexKomSigName" SG_ 1158 MtrA_InvOverTempWrn "HybridRMS_Warnings_PKT";
BA_ "FlexKomSigLaenge" SG_ 1158 MtrA_InvOverTempWrn 64;
BA_ "FlexKomSID" SG_ 1158 MtrA_InvOverTempWrn 2878;
BA_ "FlexKomIsMotorola" SG_ 1158 MtrA_InvOverTempWrn 1;
BA_ "FlexKomComment" SG_ 1158 MtrA_InvOverTempWrn ".";
BA_ "GenSigSNA" SG_ 1158 MtrA_OverTempWrn "0h";
BA_ "GenSigCycleTime" SG_ 1158 MtrA_OverTempWrn 1000;
BA_ "FlexKomSigStartValue" SG_ 1158 MtrA_OverTempWrn "0000000000000000h";
BA_ "FlexKomSigStartPos" SG_ 1158 MtrA_OverTempWrn 7;
BA_ "FlexKomSigName" SG_ 1158 MtrA_OverTempWrn "HybridRMS_Warnings_PKT";
BA_ "FlexKomSigLaenge" SG_ 1158 MtrA_OverTempWrn 64;
BA_ "FlexKomSID" SG_ 1158 MtrA_OverTempWrn 2878;
BA_ "FlexKomIsMotorola" SG_ 1158 MtrA_OverTempWrn 1;
BA_ "FlexKomComment" SG_ 1158 MtrA_OverTempWrn ".";
BA_ "GenSigSNA" SG_ 1158 MtrB_InvOverTempWrn "0h";
BA_ "GenSigCycleTime" SG_ 1158 MtrB_InvOverTempWrn 1000;
BA_ "FlexKomSigStartValue" SG_ 1158 MtrB_InvOverTempWrn "0000000000000000h";
BA_ "FlexKomSigStartPos" SG_ 1158 MtrB_InvOverTempWrn 7;
BA_ "FlexKomSigName" SG_ 1158 MtrB_InvOverTempWrn "HybridRMS_Warnings_PKT";
BA_ "FlexKomSigLaenge" SG_ 1158 MtrB_InvOverTempWrn 64;
BA_ "FlexKomSID" SG_ 1158 MtrB_InvOverTempWrn 2878;
BA_ "FlexKomIsMotorola" SG_ 1158 MtrB_InvOverTempWrn 1;
BA_ "FlexKomComment" SG_ 1158 MtrB_InvOverTempWrn ".";
BA_ "GenSigSNA" SG_ 1158 MtrB_OverTempWrn "0h";
BA_ "GenSigCycleTime" SG_ 1158 MtrB_OverTempWrn 1000;
BA_ "FlexKomSigStartValue" SG_ 1158 MtrB_OverTempWrn "0000000000000000h";
BA_ "FlexKomSigStartPos" SG_ 1158 MtrB_OverTempWrn 7;
BA_ "FlexKomSigName" SG_ 1158 MtrB_OverTempWrn "HybridRMS_Warnings_PKT";
BA_ "FlexKomSigLaenge" SG_ 1158 MtrB_OverTempWrn 64;
BA_ "FlexKomSID" SG_ 1158 MtrB_OverTempWrn 2878;
BA_ "FlexKomIsMotorola" SG_ 1158 MtrB_OverTempWrn 1;
BA_ "FlexKomComment" SG_ 1158 MtrB_OverTempWrn ".";
BA_ "RID" SG_ 503 Est_Range_Disp "6522";
BA_ "GenSigTimeout_ETM" SG_ 503 Est_Range_Disp 5250;
BA_ "GenSigTimeout_CBC" SG_ 503 Est_Range_Disp 5250;
BA_ "GenSigSNA" SG_ 503 Est_Range_Disp "FFh";
BA_ "GenSigCycleTime" SG_ 503 Est_Range_Disp 500;
BA_ "FlexKomSigStartValue" SG_ 503 Est_Range_Disp "00h";
BA_ "FlexKomSigStartPos" SG_ 503 Est_Range_Disp 39;
BA_ "FlexKomSigName" SG_ 503 Est_Range_Disp "Est_Range_Disp";
BA_ "FlexKomSigLaenge" SG_ 503 Est_Range_Disp 8;
BA_ "FlexKomSID" SG_ 503 Est_Range_Disp 2543;
BA_ "FlexKomIsMotorola" SG_ 503 Est_Range_Disp 1;
BA_ "FlexKomComment" SG_ 503 Est_Range_Disp "Estimated electric range for display";
BA_ "RID" SG_ 503 VehSpdDisp "1057";
BA_ "GenSigTimeout_CBC" SG_ 503 VehSpdDisp 5250;
BA_ "GenSigStartValue" SG_ 503 VehSpdDisp 65535;
BA_ "GenSigSNA" SG_ 503 VehSpdDisp "FFFFh";
BA_ "GenSigCycleTime" SG_ 503 VehSpdDisp 500;
BA_ "FlexKomSigStartValue" SG_ 503 VehSpdDisp "FFFFh";
BA_ "FlexKomSigStartPos" SG_ 503 VehSpdDisp 55;
BA_ "FlexKomSigName" SG_ 503 VehSpdDisp "VehSpdDisp";
BA_ "FlexKomSigLaenge" SG_ 503 VehSpdDisp 16;
BA_ "FlexKomSID" SG_ 503 VehSpdDisp 1430;
BA_ "FlexKomIsMotorola" SG_ 503 VehSpdDisp 1;
BA_ "FlexKomComment" SG_ 503 VehSpdDisp "Vehicle speed - displayed";
BA_ "RID" SG_ 503 VehSpd_MPH "1330";
BA_ "GenSigSNA" SG_ 503 VehSpd_MPH "0h";
BA_ "GenSigCycleTime" SG_ 503 VehSpd_MPH 500;
BA_ "FlexKomSigStartValue" SG_ 503 VehSpd_MPH "00h";
BA_ "FlexKomSigStartPos" SG_ 503 VehSpd_MPH 47;
BA_ "FlexKomSigName" SG_ 503 VehSpd_MPH "VehSpd_MPH";
BA_ "FlexKomSigLaenge" SG_ 503 VehSpd_MPH 1;
BA_ "FlexKomSID" SG_ 503 VehSpd_MPH 1585;
BA_ "FlexKomIsMotorola" SG_ 503 VehSpd_MPH 1;
BA_ "FlexKomComment" SG_ 503 VehSpd_MPH "Vehicle speed signal is in miles per hour format";
BA_ "GenSigTimeout_ETM" SG_ 503 xtended_AvgFuelLvl 5250;
BA_ "GenSigTimeout_CBC" SG_ 503 xtended_AvgFuelLvl 5250;
BA_ "GenSigStartValue" SG_ 503 xtended_AvgFuelLvl 4095;
BA_ "GenSigSNA" SG_ 503 xtended_AvgFuelLvl "FFFh";
BA_ "GenSigCycleTime" SG_ 503 xtended_AvgFuelLvl 500;
BA_ "FlexKomSigStartValue" SG_ 503 xtended_AvgFuelLvl "0FFFh";
BA_ "FlexKomSigStartPos" SG_ 503 xtended_AvgFuelLvl 23;
BA_ "FlexKomSigName" SG_ 503 xtended_AvgFuelLvl "xtended_AvgFuelLvl";
BA_ "FlexKomSigLaenge" SG_ 503 xtended_AvgFuelLvl 16;
BA_ "FlexKomSID" SG_ 503 xtended_AvgFuelLvl 2440;
BA_ "FlexKomIsMotorola" SG_ 503 xtended_AvgFuelLvl 1;
BA_ "FlexKomComment" SG_ 503 xtended_AvgFuelLvl "Epanded average filtered fuel level in liters";
BA_ "RID" SG_ 634 AvgFuelLvl "1196";
BA_ "GenSigTimeout_TBM" SG_ 634 AvgFuelLvl 10500;
BA_ "GenSigTimeout_ETM" SG_ 634 AvgFuelLvl 10500;
BA_ "GenSigTimeout_CBC" SG_ 634 AvgFuelLvl 10500;
BA_ "GenSigStartValue" SG_ 634 AvgFuelLvl 511;
BA_ "GenSigSNA" SG_ 634 AvgFuelLvl "1FFh";
BA_ "GenSigSendType" SG_ 634 AvgFuelLvl 5;
BA_ "GenSigCycleTime" SG_ 634 AvgFuelLvl 1000;
BA_ "FlexKomSigStartValue" SG_ 634 AvgFuelLvl "01FFh";
BA_ "FlexKomSigStartPos" SG_ 634 AvgFuelLvl 7;
BA_ "FlexKomSigName" SG_ 634 AvgFuelLvl "AvgFuelLvl";
BA_ "FlexKomSigLaenge" SG_ 634 AvgFuelLvl 16;
BA_ "FlexKomSID" SG_ 634 AvgFuelLvl 848;
BA_ "FlexKomIsMotorola" SG_ 634 AvgFuelLvl 1;
BA_ "FlexKomComment" SG_ 634 AvgFuelLvl "Average filtered fuel level in liters";
BA_ "GenSigTimeout_CBC" SG_ 634 FuelLvlLow 10500;
BA_ "GenSigSNA" SG_ 634 FuelLvlLow "0h";
BA_ "GenSigSendType" SG_ 634 FuelLvlLow 5;
BA_ "GenSigCycleTime" SG_ 634 FuelLvlLow 1000;
BA_ "FlexKomSigStartValue" SG_ 634 FuelLvlLow "00h";
BA_ "FlexKomSigStartPos" SG_ 634 FuelLvlLow 6;
BA_ "FlexKomSigName" SG_ 634 FuelLvlLow "FuelLvlLow";
BA_ "FlexKomSigLaenge" SG_ 634 FuelLvlLow 1;
BA_ "FlexKomSID" SG_ 634 FuelLvlLow 1049;
BA_ "FlexKomIsMotorola" SG_ 634 FuelLvlLow 1;
BA_ "FlexKomComment" SG_ 634 FuelLvlLow "Fuel level low";
BA_ "RID" SG_ 634 ODO "1177 2112";
BA_ "GenSigTimeout_TPM" SG_ 634 ODO 10500;
BA_ "GenSigTimeout_TCM" SG_ 634 ODO 3500;
BA_ "GenSigTimeout_SCCM" SG_ 634 ODO 10500;
BA_ "GenSigTimeout_RF_HUB" SG_ 634 ODO 10500;
BA_ "GenSigTimeout_ORC" SG_ 634 ODO 3500;
BA_ "GenSigTimeout_ESM" SG_ 634 ODO 10500;
BA_ "GenSigTimeout_EHPS" SG_ 634 ODO 10500;
BA_ "GenSigTimeout_DTCM" SG_ 634 ODO 10500;
BA_ "GenSigTimeout_CBC" SG_ 634 ODO 10500;
BA_ "GenSigStartValue" SG_ 634 ODO 16777215;
BA_ "GenSigSNA" SG_ 634 ODO "FFFFFFh";
BA_ "GenSigSendType" SG_ 634 ODO 5;
BA_ "GenSigCycleTime" SG_ 634 ODO 1000;
BA_ "FlexKomSigStartValue" SG_ 634 ODO "FFFFFFh";
BA_ "FlexKomSigStartPos" SG_ 634 ODO 39;
BA_ "FlexKomSigName" SG_ 634 ODO "ODO";
BA_ "FlexKomSigLaenge" SG_ 634 ODO 24;
BA_ "FlexKomSID" SG_ 634 ODO 804;
BA_ "FlexKomIsMotorola" SG_ 634 ODO 1;
BA_ "FlexKomComment" SG_ 634 ODO "Odometer";
BA_ "GenSigSNA" SG_ 634 OilChgRst "0h";
BA_ "GenSigSendType" SG_ 634 OilChgRst 5;
BA_ "GenSigCycleTime" SG_ 634 OilChgRst 1000;
BA_ "FlexKomSigStartValue" SG_ 634 OilChgRst "00h";
BA_ "FlexKomSigStartPos" SG_ 634 OilChgRst 29;
BA_ "FlexKomSigName" SG_ 634 OilChgRst "OilChgRst";
BA_ "FlexKomSigLaenge" SG_ 634 OilChgRst 1;
BA_ "FlexKomSID" SG_ 634 OilChgRst 1819;
BA_ "FlexKomIsMotorola" SG_ 634 OilChgRst 1;
BA_ "FlexKomComment" SG_ 634 OilChgRst "Oil change reminder reset request";
BA_ "GenSigTimeout_TBM" SG_ 634 SRS_LMP_STAT 10500;
BA_ "GenSigTimeout_ORC" SG_ 634 SRS_LMP_STAT 3500;
BA_ "GenSigTimeout_ETM" SG_ 634 SRS_LMP_STAT 10500;
BA_ "GenSigSNA" SG_ 634 SRS_LMP_STAT "3h";
BA_ "GenSigSendType" SG_ 634 SRS_LMP_STAT 5;
BA_ "GenSigCycleTime" SG_ 634 SRS_LMP_STAT 1000;
BA_ "FlexKomSigStartValue" SG_ 634 SRS_LMP_STAT "00h";
BA_ "FlexKomSigStartPos" SG_ 634 SRS_LMP_STAT 5;
BA_ "FlexKomSigName" SG_ 634 SRS_LMP_STAT "SRS_LMP_STAT";
BA_ "FlexKomSigLaenge" SG_ 634 SRS_LMP_STAT 2;
BA_ "FlexKomSID" SG_ 634 SRS_LMP_STAT 851;
BA_ "FlexKomIsMotorola" SG_ 634 SRS_LMP_STAT 1;
BA_ "FlexKomComment" SG_ 634 SRS_LMP_STAT "Airbag indicator lamp status";
BA_ "GenSigSNA" SG_ 634 WTS_LmpRqOn "0h";
BA_ "GenSigSendType" SG_ 634 WTS_LmpRqOn 5;
BA_ "GenSigCycleTime" SG_ 634 WTS_LmpRqOn 1000;
BA_ "FlexKomSigStartValue" SG_ 634 WTS_LmpRqOn "00h";
BA_ "FlexKomSigStartPos" SG_ 634 WTS_LmpRqOn 7;
BA_ "FlexKomSigName" SG_ 634 WTS_LmpRqOn "WTS_LmpRqOn";
BA_ "FlexKomSigLaenge" SG_ 634 WTS_LmpRqOn 1;
BA_ "FlexKomSID" SG_ 634 WTS_LmpRqOn 1559;
BA_ "FlexKomIsMotorola" SG_ 634 WTS_LmpRqOn 1;
BA_ "FlexKomComment" SG_ 634 WTS_LmpRqOn "Wait to start lamp requested on; true = [1]";
BA_ "RID" SG_ 673 ConsumptionUnit "2002";
BA_ "GenSigTimeout_CBC" SG_ 673 ConsumptionUnit 10500;
BA_ "GenSigSNA" SG_ 673 ConsumptionUnit "7h";
BA_ "GenSigSendType" SG_ 673 ConsumptionUnit 5;
BA_ "GenSigCycleTime" SG_ 673 ConsumptionUnit 1000;
BA_ "FlexKomSigStartValue" SG_ 673 ConsumptionUnit "00h";
BA_ "FlexKomSigStartPos" SG_ 673 ConsumptionUnit 55;
BA_ "FlexKomSigName" SG_ 673 ConsumptionUnit "ConsumptionUnit";
BA_ "FlexKomSigLaenge" SG_ 673 ConsumptionUnit 3;
BA_ "FlexKomSID" SG_ 673 ConsumptionUnit 2005;
BA_ "FlexKomIsMotorola" SG_ 673 ConsumptionUnit 1;
BA_ "FlexKomComment" SG_ 673 ConsumptionUnit "Fuel consumption units";
BA_ "RID" SG_ 673 DistanceUnit "1992";
BA_ "GenSigSNA" SG_ 673 DistanceUnit "0h";
BA_ "GenSigSendType" SG_ 673 DistanceUnit 5;
BA_ "GenSigCycleTime" SG_ 673 DistanceUnit 1000;
BA_ "FlexKomSigStartValue" SG_ 673 DistanceUnit "00h";
BA_ "FlexKomSigStartPos" SG_ 673 DistanceUnit 50;
BA_ "FlexKomSigName" SG_ 673 DistanceUnit "DistanceUnit";
BA_ "FlexKomSigLaenge" SG_ 673 DistanceUnit 1;
BA_ "FlexKomSID" SG_ 673 DistanceUnit 2002;
BA_ "FlexKomIsMotorola" SG_ 673 DistanceUnit 1;
BA_ "FlexKomComment" SG_ 673 DistanceUnit "Distance (odometer) units; Miles = [1]";
BA_ "RID" SG_ 673 LANG_C "1797";
BA_ "GenSigTimeout_CBC" SG_ 673 LANG_C 10500;
BA_ "GenSigStartValue" SG_ 673 LANG_C 31;
BA_ "GenSigSNA" SG_ 673 LANG_C "1Fh";
BA_ "GenSigSendType" SG_ 673 LANG_C 5;
BA_ "GenSigCycleTime" SG_ 673 LANG_C 1000;
BA_ "FlexKomSigStartValue" SG_ 673 LANG_C "3Eh";
BA_ "FlexKomSigStartPos" SG_ 673 LANG_C 15;
BA_ "FlexKomSigName" SG_ 673 LANG_C "CFG_STAT_C";
BA_ "FlexKomSigLaenge" SG_ 673 LANG_C 6;
BA_ "FlexKomSID" SG_ 673 LANG_C 1804;
BA_ "FlexKomIsMotorola" SG_ 673 LANG_C 1;
BA_ "FlexKomComment" SG_ 673 LANG_C "Configuration status";
BA_ "RID" SG_ 673 PowerUnit "2007";
BA_ "GenSigTimeout_CBC" SG_ 673 PowerUnit 10500;
BA_ "GenSigSNA" SG_ 673 PowerUnit "0h";
BA_ "GenSigSendType" SG_ 673 PowerUnit 5;
BA_ "GenSigCycleTime" SG_ 673 PowerUnit 1000;
BA_ "FlexKomSigStartValue" SG_ 673 PowerUnit "00h";
BA_ "FlexKomSigStartPos" SG_ 673 PowerUnit 35;
BA_ "FlexKomSigName" SG_ 673 PowerUnit "PowerUnit";
BA_ "FlexKomSigLaenge" SG_ 673 PowerUnit 2;
BA_ "FlexKomSID" SG_ 673 PowerUnit 1999;
BA_ "FlexKomIsMotorola" SG_ 673 PowerUnit 1;
BA_ "FlexKomComment" SG_ 673 PowerUnit "Power units";
BA_ "RID" SG_ 673 PressureUnit "1998";
BA_ "GenSigTimeout_CBC" SG_ 673 PressureUnit 10500;
BA_ "GenSigSNA" SG_ 673 PressureUnit "0h";
BA_ "GenSigSendType" SG_ 673 PressureUnit 5;
BA_ "GenSigCycleTime" SG_ 673 PressureUnit 1000;
BA_ "FlexKomSigStartValue" SG_ 673 PressureUnit "00h";
BA_ "FlexKomSigStartPos" SG_ 673 PressureUnit 37;
BA_ "FlexKomSigName" SG_ 673 PressureUnit "PressureUnit";
BA_ "FlexKomSigLaenge" SG_ 673 PressureUnit 2;
BA_ "FlexKomSID" SG_ 673 PressureUnit 2000;
BA_ "FlexKomIsMotorola" SG_ 673 PressureUnit 1;
BA_ "FlexKomComment" SG_ 673 PressureUnit "Pressure units";
BA_ "RID" SG_ 673 RDY_DRV_STAT_CSO "5028";
BA_ "GenSigSNA" SG_ 673 RDY_DRV_STAT_CSO "0h";
BA_ "GenSigSendType" SG_ 673 RDY_DRV_STAT_CSO 5;
BA_ "GenSigCycleTime" SG_ 673 RDY_DRV_STAT_CSO 1000;
BA_ "FlexKomSigStartValue" SG_ 673 RDY_DRV_STAT_CSO "00h";
BA_ "FlexKomSigStartPos" SG_ 673 RDY_DRV_STAT_CSO 17;
BA_ "FlexKomSigName" SG_ 673 RDY_DRV_STAT_CSO "RDY_DRV_STAT_CSO";
BA_ "FlexKomSigLaenge" SG_ 673 RDY_DRV_STAT_CSO 1;
BA_ "FlexKomSID" SG_ 673 RDY_DRV_STAT_CSO 2592;
BA_ "FlexKomIsMotorola" SG_ 673 RDY_DRV_STAT_CSO 1;
BA_ "FlexKomComment" SG_ 673 RDY_DRV_STAT_CSO "Ready to drive popup status enable/disable; Disabl";
BA_ "RID" SG_ 673 SpeedUnit "2000";
BA_ "GenSigSNA" SG_ 673 SpeedUnit "0h";
BA_ "GenSigSendType" SG_ 673 SpeedUnit 5;
BA_ "GenSigCycleTime" SG_ 673 SpeedUnit 1000;
BA_ "FlexKomSigStartValue" SG_ 673 SpeedUnit "00h";
BA_ "FlexKomSigStartPos" SG_ 673 SpeedUnit 51;
BA_ "FlexKomSigName" SG_ 673 SpeedUnit "SpeedUnit";
BA_ "FlexKomSigLaenge" SG_ 673 SpeedUnit 1;
BA_ "FlexKomSID" SG_ 673 SpeedUnit 2004;
BA_ "FlexKomIsMotorola" SG_ 673 SpeedUnit 1;
BA_ "FlexKomComment" SG_ 673 SpeedUnit "Speed (speedometer) units; Miles = [1]";
BA_ "RID" SG_ 673 TemperatureUnit "2004";
BA_ "GenSigSNA" SG_ 673 TemperatureUnit "0h";
BA_ "GenSigSendType" SG_ 673 TemperatureUnit 5;
BA_ "GenSigCycleTime" SG_ 673 TemperatureUnit 1000;
BA_ "FlexKomSigStartValue" SG_ 673 TemperatureUnit "00h";
BA_ "FlexKomSigStartPos" SG_ 673 TemperatureUnit 52;
BA_ "FlexKomSigName" SG_ 673 TemperatureUnit "TemperatureUnit";
BA_ "FlexKomSigLaenge" SG_ 673 TemperatureUnit 1;
BA_ "FlexKomSID" SG_ 673 TemperatureUnit 2003;
BA_ "FlexKomIsMotorola" SG_ 673 TemperatureUnit 1;
BA_ "FlexKomComment" SG_ 673 TemperatureUnit "Temperature units; Farenheit = [1]";
BA_ "RID" SG_ 673 TorqueUnit "1994";
BA_ "GenSigSNA" SG_ 673 TorqueUnit "0h";
BA_ "GenSigSendType" SG_ 673 TorqueUnit 5;
BA_ "GenSigCycleTime" SG_ 673 TorqueUnit 1000;
BA_ "FlexKomSigStartValue" SG_ 673 TorqueUnit "00h";
BA_ "FlexKomSigStartPos" SG_ 673 TorqueUnit 7;
BA_ "FlexKomSigName" SG_ 673 TorqueUnit "TorqueUnit";
BA_ "FlexKomSigLaenge" SG_ 673 TorqueUnit 1;
BA_ "FlexKomSID" SG_ 673 TorqueUnit 1998;
BA_ "FlexKomIsMotorola" SG_ 673 TorqueUnit 1;
BA_ "FlexKomComment" SG_ 673 TorqueUnit "Torque units; Foot Pounds (ft-lb) = [1]";
BA_ "RID" SG_ 673 UNIT_SET_CSO "5045";
BA_ "GenSigTimeout_CBC" SG_ 673 UNIT_SET_CSO 10500;
BA_ "GenSigSNA" SG_ 673 UNIT_SET_CSO "0h";
BA_ "GenSigSendType" SG_ 673 UNIT_SET_CSO 5;
BA_ "GenSigCycleTime" SG_ 673 UNIT_SET_CSO 1000;
BA_ "FlexKomSigStartValue" SG_ 673 UNIT_SET_CSO "00h";
BA_ "FlexKomSigStartPos" SG_ 673 UNIT_SET_CSO 25;
BA_ "FlexKomSigName" SG_ 673 UNIT_SET_CSO "UNIT_SET_CSO";
BA_ "FlexKomSigLaenge" SG_ 673 UNIT_SET_CSO 2;
BA_ "FlexKomSID" SG_ 673 UNIT_SET_CSO 2602;
BA_ "FlexKomIsMotorola" SG_ 673 UNIT_SET_CSO 1;
BA_ "FlexKomComment" SG_ 673 UNIT_SET_CSO "Unit set status enable/disable";
BA_ "RID" SG_ 635 Gas_Range "3068";
BA_ "GenSigTimeout_CBC" SG_ 635 Gas_Range 10500;
BA_ "GenSigStartValue" SG_ 635 Gas_Range 1023;
BA_ "GenSigSNA" SG_ 635 Gas_Range "3FFh";
BA_ "GenSigSendType" SG_ 635 Gas_Range 5;
BA_ "GenSigCycleTime" SG_ 635 Gas_Range 1000;
BA_ "FlexKomSigStartValue" SG_ 635 Gas_Range "A3FF07FF00000000h";
BA_ "FlexKomSigStartPos" SG_ 635 Gas_Range 7;
BA_ "FlexKomSigName" SG_ 635 Gas_Range "IC_A5_Pkt";
BA_ "FlexKomSigLaenge" SG_ 635 Gas_Range 64;
BA_ "FlexKomSID" SG_ 635 Gas_Range 2522;
BA_ "FlexKomIsMotorola" SG_ 635 Gas_Range 1;
BA_ "FlexKomComment" SG_ 635 Gas_Range "IC_A5 packet";
BA_ "RID" SG_ 635 Total_Range "3064";
BA_ "GenSigTimeout_CBC" SG_ 635 Total_Range 10500;
BA_ "GenSigStartValue" SG_ 635 Total_Range 2047;
BA_ "GenSigSNA" SG_ 635 Total_Range "7FFh";
BA_ "GenSigSendType" SG_ 635 Total_Range 5;
BA_ "GenSigCycleTime" SG_ 635 Total_Range 1000;
BA_ "FlexKomSigStartValue" SG_ 635 Total_Range "A3FF07FF00000000h";
BA_ "FlexKomSigStartPos" SG_ 635 Total_Range 7;
BA_ "FlexKomSigName" SG_ 635 Total_Range "IC_A5_Pkt";
BA_ "FlexKomSigLaenge" SG_ 635 Total_Range 64;
BA_ "FlexKomSID" SG_ 635 Total_Range 2522;
BA_ "FlexKomIsMotorola" SG_ 635 Total_Range 1;
BA_ "FlexKomComment" SG_ 635 Total_Range "IC_A5 packet";
BA_ "RID" SG_ 754 Avg_Fuel_Econ "5049";
BA_ "GenSigTimeout_CBC" SG_ 754 Avg_Fuel_Econ 1050;
BA_ "GenSigStartValue" SG_ 754 Avg_Fuel_Econ 1023;
BA_ "GenSigSNA" SG_ 754 Avg_Fuel_Econ "3FFh";
BA_ "GenSigCycleTime" SG_ 754 Avg_Fuel_Econ 100;
BA_ "FlexKomSigStartValue" SG_ 754 Avg_Fuel_Econ "03FFh";
BA_ "FlexKomSigStartPos" SG_ 754 Avg_Fuel_Econ 39;
BA_ "FlexKomSigName" SG_ 754 Avg_Fuel_Econ "Avg_Fuel_Econ";
BA_ "FlexKomSigLaenge" SG_ 754 Avg_Fuel_Econ 16;
BA_ "FlexKomSID" SG_ 754 Avg_Fuel_Econ 2608;
BA_ "FlexKomIsMotorola" SG_ 754 Avg_Fuel_Econ 1;
BA_ "FlexKomComment" SG_ 754 Avg_Fuel_Econ "Average fuel economy";
BA_ "RID" SG_ 754 Inst_Fuel_Econ "5048";
BA_ "GenSigTimeout_CBC" SG_ 754 Inst_Fuel_Econ 1050;
BA_ "GenSigStartValue" SG_ 754 Inst_Fuel_Econ 1023;
BA_ "GenSigSNA" SG_ 754 Inst_Fuel_Econ "3FFh";
BA_ "GenSigCycleTime" SG_ 754 Inst_Fuel_Econ 100;
BA_ "FlexKomSigStartValue" SG_ 754 Inst_Fuel_Econ "03FFh";
BA_ "FlexKomSigStartPos" SG_ 754 Inst_Fuel_Econ 55;
BA_ "FlexKomSigName" SG_ 754 Inst_Fuel_Econ "Inst_Fuel_Econ";
BA_ "FlexKomSigLaenge" SG_ 754 Inst_Fuel_Econ 16;
BA_ "FlexKomSID" SG_ 754 Inst_Fuel_Econ 2609;
BA_ "FlexKomIsMotorola" SG_ 754 Inst_Fuel_Econ 1;
BA_ "FlexKomComment" SG_ 754 Inst_Fuel_Econ "Instantaneous fuel economy";
BA_ "GenSigTimeout_ETM" SG_ 938 A_EV_Kilometers 10500;
BA_ "GenSigSNA" SG_ 938 A_EV_Kilometers "FFFFFFh";
BA_ "GenSigCycleTime" SG_ 938 A_EV_Kilometers 1000;
BA_ "FlexKomSigStartValue" SG_ 938 A_EV_Kilometers "0000000000000000h";
BA_ "FlexKomSigStartPos" SG_ 938 A_EV_Kilometers 7;
BA_ "FlexKomSigName" SG_ 938 A_EV_Kilometers "IC_TripData_Pkt_1";
BA_ "FlexKomSigLaenge" SG_ 938 A_EV_Kilometers 64;
BA_ "FlexKomSID" SG_ 938 A_EV_Kilometers 2585;
BA_ "FlexKomIsMotorola" SG_ 938 A_EV_Kilometers 1;
BA_ "FlexKomComment" SG_ 938 A_EV_Kilometers "IC Trip data packet 1";
BA_ "GenSigTimeout_ETM" SG_ 938 A_EV_Miles 10500;
BA_ "GenSigSNA" SG_ 938 A_EV_Miles "FFFFFFh";
BA_ "GenSigCycleTime" SG_ 938 A_EV_Miles 1000;
BA_ "FlexKomSigStartValue" SG_ 938 A_EV_Miles "0000000000000000h";
BA_ "FlexKomSigStartPos" SG_ 938 A_EV_Miles 7;
BA_ "FlexKomSigName" SG_ 938 A_EV_Miles "IC_TripData_Pkt_1";
BA_ "FlexKomSigLaenge" SG_ 938 A_EV_Miles 64;
BA_ "FlexKomSID" SG_ 938 A_EV_Miles 2585;
BA_ "FlexKomIsMotorola" SG_ 938 A_EV_Miles 1;
BA_ "FlexKomComment" SG_ 938 A_EV_Miles "IC Trip data packet 1";
BA_ "GenSigTimeout_ETM" SG_ 938 A_MPG 10500;
BA_ "GenSigSNA" SG_ 938 A_MPG "3FFh";
BA_ "GenSigCycleTime" SG_ 938 A_MPG 1000;
BA_ "FlexKomSigStartValue" SG_ 938 A_MPG "0000000000000000h";
BA_ "FlexKomSigStartPos" SG_ 938 A_MPG 7;
BA_ "FlexKomSigName" SG_ 938 A_MPG "IC_TripData_Pkt_1";
BA_ "FlexKomSigLaenge" SG_ 938 A_MPG 64;
BA_ "FlexKomSID" SG_ 938 A_MPG 2585;
BA_ "FlexKomIsMotorola" SG_ 938 A_MPG 1;
BA_ "FlexKomComment" SG_ 938 A_MPG "IC Trip data packet 1";
BA_ "GenSigTimeout_ETM" SG_ 939 A_Hybrid_Kilometers 10500;
BA_ "GenSigSNA" SG_ 939 A_Hybrid_Kilometers "FFFFFFh";
BA_ "GenSigCycleTime" SG_ 939 A_Hybrid_Kilometers 1000;
BA_ "FlexKomSigStartValue" SG_ 939 A_Hybrid_Kilometers "0000000000000000h";
BA_ "FlexKomSigStartPos" SG_ 939 A_Hybrid_Kilometers 7;
BA_ "FlexKomSigName" SG_ 939 A_Hybrid_Kilometers "IC_TripData_Pkt_2";
BA_ "FlexKomSigLaenge" SG_ 939 A_Hybrid_Kilometers 64;
BA_ "FlexKomSID" SG_ 939 A_Hybrid_Kilometers 2584;
BA_ "FlexKomIsMotorola" SG_ 939 A_Hybrid_Kilometers 1;
BA_ "FlexKomComment" SG_ 939 A_Hybrid_Kilometers "IC Trip data packet 2";
BA_ "GenSigTimeout_ETM" SG_ 939 A_Hybrid_Miles 10500;
BA_ "GenSigSNA" SG_ 939 A_Hybrid_Miles "FFFFFFh";
BA_ "GenSigCycleTime" SG_ 939 A_Hybrid_Miles 1000;
BA_ "FlexKomSigStartValue" SG_ 939 A_Hybrid_Miles "0000000000000000h";
BA_ "FlexKomSigStartPos" SG_ 939 A_Hybrid_Miles 7;
BA_ "FlexKomSigName" SG_ 939 A_Hybrid_Miles "IC_TripData_Pkt_2";
BA_ "FlexKomSigLaenge" SG_ 939 A_Hybrid_Miles 64;
BA_ "FlexKomSID" SG_ 939 A_Hybrid_Miles 2584;
BA_ "FlexKomIsMotorola" SG_ 939 A_Hybrid_Miles 1;
BA_ "FlexKomComment" SG_ 939 A_Hybrid_Miles "IC Trip data packet 2";
BA_ "GenSigTimeout_ETM" SG_ 939 A_KMpL 10500;
BA_ "GenSigSNA" SG_ 939 A_KMpL "3FFh";
BA_ "GenSigCycleTime" SG_ 939 A_KMpL 1000;
BA_ "FlexKomSigStartValue" SG_ 939 A_KMpL "0000000000000000h";
BA_ "FlexKomSigStartPos" SG_ 939 A_KMpL 7;
BA_ "FlexKomSigName" SG_ 939 A_KMpL "IC_TripData_Pkt_2";
BA_ "FlexKomSigLaenge" SG_ 939 A_KMpL 64;
BA_ "FlexKomSID" SG_ 939 A_KMpL 2584;
BA_ "FlexKomIsMotorola" SG_ 939 A_KMpL 1;
BA_ "FlexKomComment" SG_ 939 A_KMpL "IC Trip data packet 2";
BA_ "GenSigTimeout_ETM" SG_ 940 A_Total_Dist_Kilometers 10500;
BA_ "GenSigSNA" SG_ 940 A_Total_Dist_Kilometers "FFFFFFh";
BA_ "GenSigCycleTime" SG_ 940 A_Total_Dist_Kilometers 1000;
BA_ "FlexKomSigStartValue" SG_ 940 A_Total_Dist_Kilometers "00FF000000000000h";
BA_ "FlexKomSigStartPos" SG_ 940 A_Total_Dist_Kilometers 7;
BA_ "FlexKomSigName" SG_ 940 A_Total_Dist_Kilometers "IC_TripData_Pkt_3";
BA_ "FlexKomSigLaenge" SG_ 940 A_Total_Dist_Kilometers 64;
BA_ "FlexKomSID" SG_ 940 A_Total_Dist_Kilometers 2583;
BA_ "FlexKomIsMotorola" SG_ 940 A_Total_Dist_Kilometers 1;
BA_ "FlexKomComment" SG_ 940 A_Total_Dist_Kilometers "IC Trip data packet 3";
BA_ "GenSigTimeout_ETM" SG_ 940 A_Total_Dist_Miles 10500;
BA_ "GenSigSNA" SG_ 940 A_Total_Dist_Miles "FFFFFFh";
BA_ "GenSigCycleTime" SG_ 940 A_Total_Dist_Miles 1000;
BA_ "FlexKomSigStartValue" SG_ 940 A_Total_Dist_Miles "00FF000000000000h";
BA_ "FlexKomSigStartPos" SG_ 940 A_Total_Dist_Miles 7;
BA_ "FlexKomSigName" SG_ 940 A_Total_Dist_Miles "IC_TripData_Pkt_3";
BA_ "FlexKomSigLaenge" SG_ 940 A_Total_Dist_Miles 64;
BA_ "FlexKomSID" SG_ 940 A_Total_Dist_Miles 2583;
BA_ "FlexKomIsMotorola" SG_ 940 A_Total_Dist_Miles 1;
BA_ "FlexKomComment" SG_ 940 A_Total_Dist_Miles "IC Trip data packet 3";
BA_ "GenSigTimeout_ETM" SG_ 941 B_EV_Kilometers 10500;
BA_ "GenSigSNA" SG_ 941 B_EV_Kilometers "FFFFFFh";
BA_ "GenSigCycleTime" SG_ 941 B_EV_Kilometers 1000;
BA_ "FlexKomSigStartValue" SG_ 941 B_EV_Kilometers "0000000000000000h";
BA_ "FlexKomSigStartPos" SG_ 941 B_EV_Kilometers 7;
BA_ "FlexKomSigName" SG_ 941 B_EV_Kilometers "IC_TripData_Pkt_4";
BA_ "FlexKomSigLaenge" SG_ 941 B_EV_Kilometers 64;
BA_ "FlexKomSID" SG_ 941 B_EV_Kilometers 2582;
BA_ "FlexKomIsMotorola" SG_ 941 B_EV_Kilometers 1;
BA_ "FlexKomComment" SG_ 941 B_EV_Kilometers "IC Trip data packet 4";
BA_ "GenSigTimeout_ETM" SG_ 941 B_EV_Miles 10500;
BA_ "GenSigSNA" SG_ 941 B_EV_Miles "FFFFFFh";
BA_ "GenSigCycleTime" SG_ 941 B_EV_Miles 1000;
BA_ "FlexKomSigStartValue" SG_ 941 B_EV_Miles "0000000000000000h";
BA_ "FlexKomSigStartPos" SG_ 941 B_EV_Miles 7;
BA_ "FlexKomSigName" SG_ 941 B_EV_Miles "IC_TripData_Pkt_4";
BA_ "FlexKomSigLaenge" SG_ 941 B_EV_Miles 64;
BA_ "FlexKomSID" SG_ 941 B_EV_Miles 2582;
BA_ "FlexKomIsMotorola" SG_ 941 B_EV_Miles 1;
BA_ "FlexKomComment" SG_ 941 B_EV_Miles "IC Trip data packet 4";
BA_ "GenSigTimeout_ETM" SG_ 941 B_MPG 10500;
BA_ "GenSigSNA" SG_ 941 B_MPG "3FFh";
BA_ "GenSigCycleTime" SG_ 941 B_MPG 1000;
BA_ "FlexKomSigStartValue" SG_ 941 B_MPG "0000000000000000h";
BA_ "FlexKomSigStartPos" SG_ 941 B_MPG 7;
BA_ "FlexKomSigName" SG_ 941 B_MPG "IC_TripData_Pkt_4";
BA_ "FlexKomSigLaenge" SG_ 941 B_MPG 64;
BA_ "FlexKomSID" SG_ 941 B_MPG 2582;
BA_ "FlexKomIsMotorola" SG_ 941 B_MPG 1;
BA_ "FlexKomComment" SG_ 941 B_MPG "IC Trip data packet 4";
BA_ "GenSigTimeout_ETM" SG_ 942 B_Hybrid_Kilometers 10500;
BA_ "GenSigSNA" SG_ 942 B_Hybrid_Kilometers "FFFFFFh";
BA_ "GenSigCycleTime" SG_ 942 B_Hybrid_Kilometers 1000;
BA_ "FlexKomSigStartValue" SG_ 942 B_Hybrid_Kilometers "0000000000000000h";
BA_ "FlexKomSigStartPos" SG_ 942 B_Hybrid_Kilometers 7;
BA_ "FlexKomSigName" SG_ 942 B_Hybrid_Kilometers "IC_TripData_Pkt_5";
BA_ "FlexKomSigLaenge" SG_ 942 B_Hybrid_Kilometers 64;
BA_ "FlexKomSID" SG_ 942 B_Hybrid_Kilometers 2581;
BA_ "FlexKomIsMotorola" SG_ 942 B_Hybrid_Kilometers 1;
BA_ "FlexKomComment" SG_ 942 B_Hybrid_Kilometers "IC Trip data packet 5";
BA_ "GenSigTimeout_ETM" SG_ 942 B_Hybrid_Miles 10500;
BA_ "GenSigSNA" SG_ 942 B_Hybrid_Miles "FFFFFFh";
BA_ "GenSigCycleTime" SG_ 942 B_Hybrid_Miles 1000;
BA_ "FlexKomSigStartValue" SG_ 942 B_Hybrid_Miles "0000000000000000h";
BA_ "FlexKomSigStartPos" SG_ 942 B_Hybrid_Miles 7;
BA_ "FlexKomSigName" SG_ 942 B_Hybrid_Miles "IC_TripData_Pkt_5";
BA_ "FlexKomSigLaenge" SG_ 942 B_Hybrid_Miles 64;
BA_ "FlexKomSID" SG_ 942 B_Hybrid_Miles 2581;
BA_ "FlexKomIsMotorola" SG_ 942 B_Hybrid_Miles 1;
BA_ "FlexKomComment" SG_ 942 B_Hybrid_Miles "IC Trip data packet 5";
BA_ "GenSigTimeout_ETM" SG_ 942 B_KMpL 10500;
BA_ "GenSigSNA" SG_ 942 B_KMpL "3FFh";
BA_ "GenSigCycleTime" SG_ 942 B_KMpL 1000;
BA_ "FlexKomSigStartValue" SG_ 942 B_KMpL "0000000000000000h";
BA_ "FlexKomSigStartPos" SG_ 942 B_KMpL 7;
BA_ "FlexKomSigName" SG_ 942 B_KMpL "IC_TripData_Pkt_5";
BA_ "FlexKomSigLaenge" SG_ 942 B_KMpL 64;
BA_ "FlexKomSID" SG_ 942 B_KMpL 2581;
BA_ "FlexKomIsMotorola" SG_ 942 B_KMpL 1;
BA_ "FlexKomComment" SG_ 942 B_KMpL "IC Trip data packet 5";
VAL_ 803 Batt_CabinPriority3 0 "Checkbox_Unselected" 1 "Checkbox_Selected" ;
VAL_ 803 ChargeUntilFull3 0 "Charge_Until_Full_Not_selected" 1 "Charge_Until_Full" ;
VAL_ 803 Do_Not_Repeat3 0 "Repeat" 1 "Do_Not_Repeat" ;
VAL_ 803 Enable_Schedule3 0 "Disable_schedule" 1 "Enable_schedule" ;
VAL_ 803 End_Time_Hr3 31 "SNA" ;
VAL_ 803 End_Time_Min3 15 "SNA" ;
VAL_ 803 Schedule_Day3 0 "No_Selection" 1 "M" 2 "T" 3 "TM" 4 "W" 5 "WM" 6 "WT" 7 "WTM" 8 "Th" 9 "ThM" 10 "ThT" 11 "ThTM" 12 "ThW" 13 "ThWM" 14 "ThWT" 15 "ThWTM" 16 "F" 17 "FM" 18 "FT" 19 "FTM" 20 "FW" 21 "FWM" 22 "FWT" 23 "FWTM" 24 "FTh" 25 "FThM" 26 "FThT" 27 "FThTM" 28 "FThW" 29 "FThWM" 30 "FThWT" 31 "FThWTM" 32 "S" 33 "SM" 34 "ST" 35 "STM" 36 "SW" 37 "SWM" 38 "SWT" 39 "SWTM" 40 "STh" 41 "SThM" 42 "SThT" 43 "SThTM" 44 "SThW" 45 "SThWM" 46 "SThWT" 47 "SThWTM" 48 "SF" 49 "SFM" 50 "SFT" 51 "SFTM" 52 "SFW" 53 "SFWM" 54 "SFWT" 55 "SFWTM" 56 "SFTh" 57 "SFThM" 58 "SFThT" 59 "SFThTM" 60 "SFThW" 61 "SFThWM" 62 "SFThWT" 63 "SFThWTM" 64 "Sa" 65 "SaM" 66 "SaT" 67 "SaTM" 68 "SaW" 69 "SaWM" 70 "SaWT" 71 "SaWTM" 72 "SaTh" 73 "SaThM" 74 "SaThT" 75 "SaThTM" 76 "SaThW" 77 "SaThWM" 78 "SaThWT" 79 "SaThWTM" 80 "SaF" 81 "SaFM" 82 "SaFT" 83 "SaFTM" 84 "SaFW" 85 "SaFWM" 86 "SaFWT" 87 "SaFWTM" 88 "SaFTh" 89 "SaFThM" 90 "SaFThT" 91 "SaFThTM" 92 "SaFThW" 93 "SaFThWM" 94 "SaFThWT" 95 "SaFThWTM" 96 "SaS" 97 "SaSM" 98 "SaST" 99 "SaSTM" 100 "SaSW" 101 "SaSWM" 102 "SaSWT" 103 "SaSWTM" 104 "SaSTh" 105 "SaSThM" 106 "SaSThT" 107 "SaSThTM" 108 "SaSThW" 109 "SaSThWM" 110 "SaSThWT" 111 "SaSThWTM" 112 "SaSF" 113 "SaSFM" 114 "SaSFT" 115 "SaSFTM" 116 "SaSFW" 117 "SaSFWM" 118 "SaSFWT" 119 "SaSFWTM" 120 "SaSFTh" 121 "SaSFThM" 122 "SaSFThT" 123 "SaSFThTM" 124 "SaSFThW" 125 "SaSFThWM" 126 "SaSFThWT" 127 "SaSFThWTM" ;
VAL_ 803 Schedule_Type3 0 "No_Selection" 1 "Departure_Time" 2 "Charge_Interval" 3 "SNA" ;
VAL_ 803 Start_Time_Hr3 31 "SNA" ;
VAL_ 803 Start_Time_Min3 15 "SNA" ;
VAL_ 803 Submit_Schedule3 0 "No_Change" 1 "Change_in_schedule" ;
VAL_ 560 EVAP_TEMP 255 "SNA" ;
VAL_ 560 EVAP_TEMP_P1C 2047 "SNA" ;
VAL_ 560 EvapTempTar 255 "SNA" ;
VAL_ 560 PTC_Enbl 1 "SNA" ;
VAL_ 560 SmrtAlt_HVAC_Disabled 0 "DISABLED" 1 "ENABLED" 3 "SNA" ;
VAL_ 560 SpSt_DsblHVAC 0 "SPST_ON" 1 "CABIN_HI" 2 "CABIN_LO" 3 "MAX_AC" 4 "FT_DEFROST" 5 "EBL" 7 "SNA" ;
VAL_ 818 A2D_DRV_TEMP_DR_POS 1023 "SNA" ;
VAL_ 818 Blower_Diagnostics 1023 "SNA" ;
VAL_ 818 Blower_Speed 511 "SNA" ;
VAL_ 807 CabinConditioningSts 0 "Default" 1 "Rejected_not_plugged_in" 2 "Stopped_due_to_SOC" 3 "Preconditioning" 4 "Cabin_set_point_reached" 5 "Preconditioning_off" 6 "Failed_due_to_other_conditions" 7 "Fails_due_to_HV_battery_temp" 8 "Ccomplete_and_HV_battery_ok" 9 "Stopped_before_complete" 15 "SNA" ;
VAL_ 807 SchCond_Time_Till_Dep 127 "SNA" ;
VAL_ 807 Sch_PreCondition_Sts 0 "FALSE" 1 "TRUE" 3 "SNA" ;
VAL_ 1186 HVBatModT_13 255 "SNA" ;
VAL_ 1186 HVBatModT_14 255 "SNA" ;
VAL_ 1186 HVBatModT_15 255 "SNA" ;
VAL_ 1186 HVBatModT_16 255 "SNA" ;
VAL_ 1186 HVBatModTempMax 255 "SNA" ;
VAL_ 1186 HVBatModTempMin 255 "SNA" ;
VAL_ 1194 HVBatSerial_Length 255 "SNA" ;
VAL_ 1194 HVBatSerial_Msg 0 "DIGITS_0_6" 1 "DIGITS_7_12" 2 "DIGITS_13_18" 3 "DIGITS_19_24" 15 "SNA" ;
VAL_ 1157 HVBatCrnt 0 "SNA" ;
VAL_ 1157 HVBatIsolStat 0 "N_S" 1 "PASS" 2 "FAIL" 3 "INV" ;
VAL_ 1157 HVBatPk_CellNumMaxVlt 127 "SNA" ;
VAL_ 1157 HVBatPk_CellNumMinVlt 127 "SNA" ;
VAL_ 1157 HVBatVlt 4095 "SNA" ;
VAL_ 1157 PwrtrnHV_IsolStat 0 "N_S" 1 "PASS" 2 "FAIL" 3 "INV" ;
VAL_ 1159 HVBatCellVlt_01 8191 "SNA" ;
VAL_ 1159 HVBatCellVlt_02 8191 "SNA" ;
VAL_ 1159 HVBatCellVlt_03 8191 "SNA" ;
VAL_ 1159 HVBatCellVlt_04 8191 "SNA" ;
VAL_ 1160 HVBatCellVlt_05 8191 "SNA" ;
VAL_ 1160 HVBatCellVlt_06 8191 "SNA" ;
VAL_ 1160 HVBatCellVlt_07 8191 "SNA" ;
VAL_ 1160 HVBatCellVlt_08 8191 "SNA" ;
VAL_ 1161 HVBatCellVlt_09 8191 "SNA" ;
VAL_ 1161 HVBatCellVlt_10 8191 "SNA" ;
VAL_ 1161 HVBatCellVlt_11 8191 "SNA" ;
VAL_ 1161 HVBatCellVlt_12 8191 "SNA" ;
VAL_ 1162 HVBatCellVlt_13 8191 "SNA" ;
VAL_ 1162 HVBatCellVlt_14 8191 "SNA" ;
VAL_ 1162 HVBatCellVlt_15 8191 "SNA" ;
VAL_ 1162 HVBatCellVlt_16 8191 "SNA" ;
VAL_ 1163 HVBatCellVlt_17 8191 "SNA" ;
VAL_ 1163 HVBatCellVlt_18 8191 "SNA" ;
VAL_ 1163 HVBatCellVlt_19 8191 "SNA" ;
VAL_ 1163 HVBatCellVlt_20 8191 "SNA" ;
VAL_ 1164 HVBatCellVlt_21 8191 "SNA" ;
VAL_ 1164 HVBatCellVlt_22 8191 "SNA" ;
VAL_ 1164 HVBatCellVlt_23 8191 "SNA" ;
VAL_ 1164 HVBatCellVlt_24 8191 "SNA" ;
VAL_ 1165 HVBatCellVlt_25 8191 "SNA" ;
VAL_ 1165 HVBatCellVlt_26 8191 "SNA" ;
VAL_ 1165 HVBatCellVlt_27 8191 "SNA" ;
VAL_ 1165 HVBatCellVlt_28 8191 "SNA" ;
VAL_ 1166 HVBatCellVlt_29 8191 "SNA" ;
VAL_ 1166 HVBatCellVlt_30 8191 "SNA" ;
VAL_ 1166 HVBatCellVlt_31 8191 "SNA" ;
VAL_ 1166 HVBatCellVlt_32 8191 "SNA" ;
VAL_ 1167 HVBatCellVlt_33 8191 "SNA" ;
VAL_ 1167 HVBatCellVlt_34 8191 "SNA" ;
VAL_ 1167 HVBatCellVlt_35 8191 "SNA" ;
VAL_ 1167 HVBatCellVlt_36 8191 "SNA" ;
VAL_ 1168 HVBatCellVlt_37 8191 "SNA" ;
VAL_ 1168 HVBatCellVlt_38 8191 "SNA" ;
VAL_ 1168 HVBatCellVlt_39 8191 "SNA" ;
VAL_ 1168 HVBatCellVlt_40 8191 "SNA" ;
VAL_ 1169 HVBatCellVlt_41 8191 "SNA" ;
VAL_ 1169 HVBatCellVlt_42 8191 "SNA" ;
VAL_ 1169 HVBatCellVlt_43 8191 "SNA" ;
VAL_ 1169 HVBatCellVlt_44 8191 "SNA" ;
VAL_ 1170 HVBatCellVlt_45 8191 "SNA" ;
VAL_ 1170 HVBatCellVlt_46 8191 "SNA" ;
VAL_ 1170 HVBatCellVlt_47 8191 "SNA" ;
VAL_ 1170 HVBatCellVlt_48 8191 "SNA" ;
VAL_ 1171 HVBatCellVlt_49 8191 "SNA" ;
VAL_ 1171 HVBatCellVlt_50 8191 "SNA" ;
VAL_ 1171 HVBatCellVlt_51 8191 "SNA" ;
VAL_ 1171 HVBatCellVlt_52 8191 "SNA" ;
VAL_ 1172 HVBatCellVlt_53 8191 "SNA" ;
VAL_ 1172 HVBatCellVlt_54 8191 "SNA" ;
VAL_ 1172 HVBatCellVlt_55 8191 "SNA" ;
VAL_ 1172 HVBatCellVlt_56 8191 "SNA" ;
VAL_ 1173 HVBatCellVlt_57 8191 "SNA" ;
VAL_ 1173 HVBatCellVlt_58 8191 "SNA" ;
VAL_ 1173 HVBatCellVlt_59 8191 "SNA" ;
VAL_ 1173 HVBatCellVlt_60 8191 "SNA" ;
VAL_ 1174 HVBatCellVlt_61 8191 "SNA" ;
VAL_ 1174 HVBatCellVlt_62 8191 "SNA" ;
VAL_ 1174 HVBatCellVlt_63 8191 "SNA" ;
VAL_ 1174 HVBatCellVlt_64 8191 "SNA" ;
VAL_ 1175 HVBatCellVlt_65 8191 "SNA" ;
VAL_ 1175 HVBatCellVlt_66 8191 "SNA" ;
VAL_ 1175 HVBatCellVlt_67 8191 "SNA" ;
VAL_ 1175 HVBatCellVlt_68 8191 "SNA" ;
VAL_ 1176 HVBatCellVlt_69 8191 "SNA" ;
VAL_ 1176 HVBatCellVlt_70 8191 "SNA" ;
VAL_ 1176 HVBatCellVlt_71 8191 "SNA" ;
VAL_ 1176 HVBatCellVlt_72 8191 "SNA" ;
VAL_ 1177 HVBatCellVlt_73 8191 "SNA" ;
VAL_ 1177 HVBatCellVlt_74 8191 "SNA" ;
VAL_ 1177 HVBatCellVlt_75 8191 "SNA" ;
VAL_ 1177 HVBatCellVlt_76 8191 "SNA" ;
VAL_ 1178 HVBatCellVlt_77 8191 "SNA" ;
VAL_ 1178 HVBatCellVlt_78 8191 "SNA" ;
VAL_ 1178 HVBatCellVlt_79 8191 "SNA" ;
VAL_ 1178 HVBatCellVlt_80 8191 "SNA" ;
VAL_ 1179 HVBatCellVlt_81 8191 "SNA" ;
VAL_ 1179 HVBatCellVlt_82 8191 "SNA" ;
VAL_ 1179 HVBatCellVlt_83 8191 "SNA" ;
VAL_ 1179 HVBatCellVlt_84 8191 "SNA" ;
VAL_ 1180 HVBatCellVlt_85 8191 "SNA" ;
VAL_ 1180 HVBatCellVlt_86 8191 "SNA" ;
VAL_ 1180 HVBatCellVlt_87 8191 "SNA" ;
VAL_ 1180 HVBatCellVlt_88 8191 "SNA" ;
VAL_ 1181 HVBatCellVlt_89 8191 "SNA" ;
VAL_ 1181 HVBatCellVlt_90 8191 "SNA" ;
VAL_ 1181 HVBatCellVlt_91 8191 "SNA" ;
VAL_ 1181 HVBatCellVlt_92 8191 "SNA" ;
VAL_ 1182 HVBatCellVlt_93 8191 "SNA" ;
VAL_ 1182 HVBatCellVlt_94 8191 "SNA" ;
VAL_ 1182 HVBatCellVlt_95 8191 "SNA" ;
VAL_ 1182 HVBatCellVlt_96 8191 "SNA" ;
VAL_ 1183 HVBatCellVltMax 8191 "SNA" ;
VAL_ 1183 HVBatCellVltMin 8191 "SNA" ;
VAL_ 1156 ACSideCurr 1023 "SNA" ;
VAL_ 1156 ACSideVolt 4095 "SNA" ;
VAL_ 1156 APM_FailureReason 0 "No_Failure" 1 "Fail_high_voltage_at_HV" 2 "Fail_low_voltage_at_HV" 3 "Fail_high_voltage_at_LV" 4 "Fail_low_voltage_at_LV" 5 "Fail_high_PCB_temperature" 6 "Fail_high_DBC_temperature" 7 "Fail_high_cur_at_LV" 8 "Fail_high_curr_at_HV" 9 "Fail_short_circ_at_LV" 10 "Fail_short_circ_at_HV" 11 "Fail_open_circ_at_LV" 12 "Fail_open_circ_at_HV" 13 "Fail_init_failure" 14 "Fail_wake_up_issue" 15 "Fail_internal_hardware" 16 "Fail_bat_feed_low" 17 "Fail_bat_feed_high_" 18 "Fail_Aux_OV" 19 "Fail_Aux_UV" 20 "Fail_HVIL_fault" 21 "Fail_LOC_with_HCP" 22 "Fail_LOC_with_BPCM" 23 "Fail_cont_not_closed" 24 "Fail_SBC_fault" 25 "Memory_Fail" 26 "Implausible_data_from_HCP" 27 "Implausible_data_from_BPCM" 28 "CAN_bus_off" 29 "Fail_temp_diff_is_high" 30 "Fail_high_voltage_diff_is_high" 31 "Fail_for_other_reason" 32 "LOC_ORC" 33 "Implausible_data_ORC" 63 "SNA" ;
VAL_ 1156 APM_OperModeStatus 0 "IDLE" 1 "Buck_CV" 2 "Buck_CC" 3 "Buck_CP" 4 "Buck_Special" 5 "Boost" 6 "Precharge" 7 "Discharge" 8 "Failure" 15 "SNA" ;
VAL_ 1156 APM_OutputPower 1023 "SNA" ;
VAL_ 1156 IsolationResistance 65535 "SNA" ;
VAL_ 1153 MtrA_Invrtr_State 0 "NORMAL_PWR_STAGE_OFF" 1 "NORMAL_PWR_STAGE_ON" 2 "PWR_STAGE_ON_SHUTDWN_PNDING" 3 "ACTIVE_DISCHARGE" 4 "INVERTER_FAULTED" ;
VAL_ 1155 MtrB_Invrtr_State 0 "NORMAL_PWR_STAGE_OFF" 1 "NORMAL_PWR_STAGE_ON" 2 "PWR_STAGE_ON_SHUTDWN_PNDING" 3 "ACTIVE_DISCHARGE" 4 "INVERTER_FAULTED" ;
VAL_ 1158 APMPerfWrn 0 "Normal" 1 "Warning" ;
VAL_ 1158 APMTempWrn 0 "Normal" 1 "Warning" ;
VAL_ 1158 BPCMCellBalWrn 0 "Normal" 1 "Warning" ;
VAL_ 1158 BPCMCellOverWrn 0 "Normal" 1 "Warning" ;
VAL_ 1158 BPCMCellUnderWrn 0 "Normal" 1 "Warning" ;
VAL_ 1158 BPCMHighSOCWrn 0 "Normal" 1 "Warning" ;
VAL_ 1158 BPCMInsulWrn 0 "Normal" 1 "Warning" ;
VAL_ 1158 BPCMMaxTempWrn 0 "Normal" 1 "Warning" ;
VAL_ 1158 BPCMOverChrgWrn 0 "Normal" 1 "Warning" ;
VAL_ 1158 BPCMOverVoltWrn 0 "Normal" 1 "Warning" ;
VAL_ 1158 BPCMSOCJumpWrn 0 "Normal" 1 "Warning" ;
VAL_ 1158 BPCMSOCLowWrn 0 "Normal" 1 "Warning" ;
VAL_ 1158 BPCMTempDiffWrn 0 "Normal" 1 "Warning" ;
VAL_ 1158 BPCMUnderVoltWrn 0 "Normal" 1 "Warning" ;
VAL_ 1158 BPCMUnmatchedWrn 0 "Normal" 1 "Warning" ;
VAL_ 1158 HVILWrn 0 "Normal" 1 "Warning" ;
VAL_ 1158 HighestWarnLevel 0 "No_Faults" 1 "Level_1" 2 "Level_2" 3 "Level_3" ;
VAL_ 1158 MtrA_InvOverTempWrn 0 "Normal" 1 "Warning" ;
VAL_ 1158 MtrA_OverTempWrn 0 "Normal" 1 "Warning" ;
VAL_ 1158 MtrB_InvOverTempWrn 0 "Normal" 1 "Warning" ;
VAL_ 1158 MtrB_OverTempWrn 0 "Normal" 1 "Warning" ;
VAL_ 503 Est_Range_Disp 255 "SNA" ;
VAL_ 503 VehSpdDisp 65535 "SNA" ;
VAL_ 503 xtended_AvgFuelLvl 4095 "SNA" ;
VAL_ 634 AvgFuelLvl 511 "SNA" ;
VAL_ 634 ODO 16777215 "SNA" ;
VAL_ 634 SRS_LMP_STAT 0 "SRS_LMP_OFF" 1 "SRS_LMP_ON" 2 "SRS_LMP_ON_IC" 3 "SNA" ;
VAL_ 673 ConsumptionUnit 0 "KMPL" 1 "LP100KM" 2 "MPG_UK" 3 "MPG_US" 7 "SNA" ;
VAL_ 673 LANG_C 0 "GERMAN" 1 "US_ENGLISH" 2 "FRENCH" 3 "ITALIAN" 4 "SPANISH" 5 "JAPANESE" 6 "PORTUGESE" 7 "DUTCH" 8 "UK_ENGLISH" 9 "MANDARIN_S" 10 "RUSSIAN" 11 "KOREAN" 12 "ARABIC" 13 "BRAZILIAN" 14 "MANDARIN_T" 15 "HINDI" 16 "TURKISH" 17 "POLISH" 31 "LANG_NO_CHG" ;
VAL_ 673 PowerUnit 0 "KW" 1 "HP_UK" 2 "HP_US" ;
VAL_ 673 PressureUnit 0 "KPA" 1 "BAR" 2 "PSI" ;
VAL_ 673 UNIT_SET_CSO 0 "UnitSet_1" 1 "UnitSet_2" 2 "UnitSet_3" 3 "UnitSet_4" ;
VAL_ 635 Gas_Range 1023 "SNA" ;
VAL_ 635 Total_Range 2047 "SNA" ;
VAL_ 754 Avg_Fuel_Econ 1023 "SNA" ;
VAL_ 754 Inst_Fuel_Econ 1023 "SNA" ;
VAL_ 938 A_EV_Kilometers 16777215 "SNA" ;
VAL_ 938 A_EV_Miles 16777215 "SNA" ;
VAL_ 938 A_MPG 1023 "SNA" ;
VAL_ 939 A_Hybrid_Kilometers 16777215 "SNA" ;
VAL_ 939 A_Hybrid_Miles 16777215 "SNA" ;
VAL_ 939 A_KMpL 1023 "SNA" ;
VAL_ 940 A_Total_Dist_Kilometers 16777215 "SNA" ;
VAL_ 940 A_Total_Dist_Miles 16777215 "SNA" ;
VAL_ 941 B_EV_Kilometers 16777215 "SNA" ;
VAL_ 941 B_EV_Miles 16777215 "SNA" ;
VAL_ 941 B_MPG 1023 "SNA" ;
VAL_ 942 B_Hybrid_Kilometers 16777215 "SNA" ;
VAL_ 942 B_Hybrid_Miles 16777215 "SNA" ;
VAL_ 942 B_KMpL 1023 "SNA" ;
